VERSION ""

NS_ :

BS_:

BU_: Receiver ChassisBus VehicleBus PartyBus

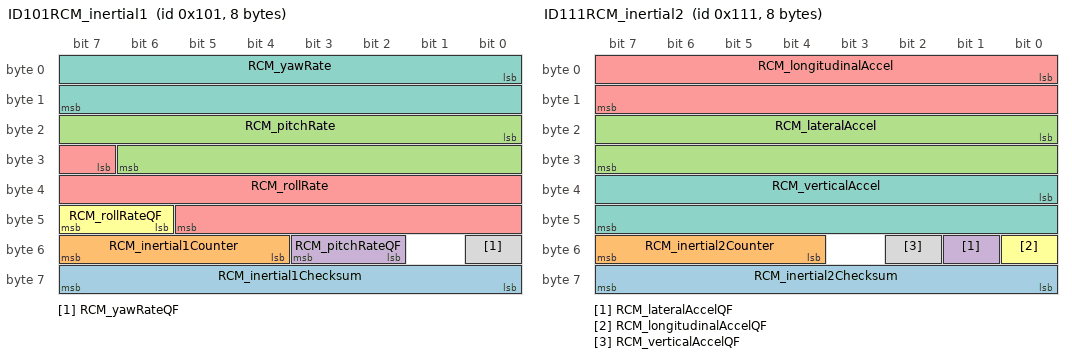
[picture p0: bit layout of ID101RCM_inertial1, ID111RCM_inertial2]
BO_ 257 ID101RCM_inertial1: 8 ChassisBus
 SG_ RCM_inertial1Checksum : 56|8@1+ (1,0) [0|255] ""  Receiver
 SG_ RCM_inertial1Counter : 52|4@1+ (1,0) [0|15] ""  Receiver
 SG_ RCM_pitchRate : 16|15@1- (0.00025,0) [-4.096|4.09575] "rad/s"  Receiver
 SG_ RCM_pitchRateQF : 50|2@1+ (1,0) [0|3] ""  Receiver
 SG_ RCM_rollRate : 31|15@1- (0.00025,0) [-4.096|4.09575] "rad/s"  Receiver
 SG_ RCM_rollRateQF : 46|2@1+ (1,0) [0|3] ""  Receiver
 SG_ RCM_yawRate : 0|16@1- (0.0001,0) [-3.2766|3.2766] "rad/s"  Receiver
 SG_ RCM_yawRateQF : 48|1@1+ (1,0) [0|1] ""  Receiver

BO_ 273 ID111RCM_inertial2: 8 ChassisBus
 SG_ RCM_inertial2Checksum : 56|8@1+ (1,0) [0|255] ""  Receiver
 SG_ RCM_inertial2Counter : 52|4@1+ (1,0) [0|15] ""  Receiver
 SG_ RCM_lateralAccel : 16|16@1- (0.00125,0) [-40.9575|40.9575] "m/s^2"  Receiver
 SG_ RCM_lateralAccelQF : 49|1@1+ (1,0) [0|1] ""  Receiver
 SG_ RCM_longitudinalAccel : 0|16@1- (0.00125,0) [-40.9575|40.9575] "m/s^2"  Receiver
 SG_ RCM_longitudinalAccelQF : 48|1@1+ (1,0) [0|1] ""  Receiver
 SG_ RCM_verticalAccel : 32|16@1- (0.00125,0) [-40.9575|40.9575] "m/s^2"  Receiver
 SG_ RCM_verticalAccelQF : 50|1@1+ (1,0) [0|1] ""  Receiver

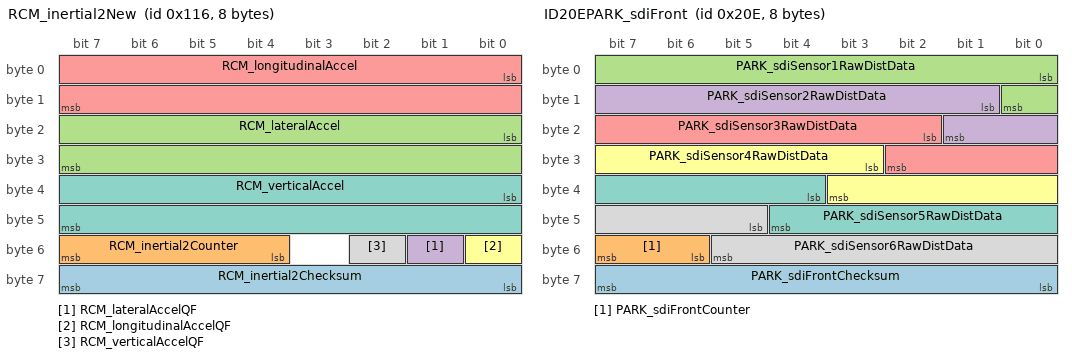
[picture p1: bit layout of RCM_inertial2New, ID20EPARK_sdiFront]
BO_ 278 RCM_inertial2New: 8 ChassisBus
 SG_ RCM_inertial2Checksum : 56|8@1+ (1,0) [0|255] ""  Receiver
 SG_ RCM_inertial2Counter : 52|4@1+ (1,0) [0|15] ""  Receiver
 SG_ RCM_lateralAccel : 16|16@1- (0.00125,0) [-40.9575|40.9575] "m/s^2"  Receiver
 SG_ RCM_lateralAccelQF : 49|1@1+ (1,0) [0|1] ""  Receiver
 SG_ RCM_longitudinalAccel : 0|16@1- (0.00125,0) [-40.9575|40.9575] "m/s^2"  Receiver
 SG_ RCM_longitudinalAccelQF : 48|1@1+ (1,0) [0|1] ""  Receiver
 SG_ RCM_verticalAccel : 32|16@1- (0.00125,0) [-40.9575|40.9575] "m/s^2"  Receiver
 SG_ RCM_verticalAccelQF : 50|1@1+ (1,0) [0|1] ""  Receiver

BO_ 325 ID145ESP_status: 8 ChassisBus
 SG_ ESP_absBrakeEvent2 : 22|2@1+ (1,0) [0|3] ""  Receiver
 SG_ ESP_absFaultLamp : 17|1@1+ (1,0) [0|1] ""  Receiver
 SG_ ESP_brakeApply : 31|1@1+ (1,0) [0|1] ""  Receiver
 SG_ ESP_brakeDiscWipingActive : 28|1@1+ (1,0) [0|1] ""  Receiver
 SG_ ESP_brakeLamp : 21|1@1+ (1,0) [0|1] ""  Receiver
 SG_ ESP_brakeTorqueTarget : 51|13@1+ (2,0) [0|16382] "Nm"  Receiver
 SG_ ESP_btcTargetState : 38|2@1+ (1,0) [0|3] ""  Receiver
 SG_ ESP_cdpStatus : 34|2@1+ (1,0) [0|3] ""  Receiver
 SG_ ESP_driverBrakeApply : 29|2@1+ (1,0) [0|3] ""  Receiver
 SG_ ESP_ebdFaultLamp : 16|1@1+ (1,0) [0|1] ""  Receiver
 SG_ ESP_ebrStandstillSkid : 48|1@1+ (1,0) [0|1] ""  Receiver
 SG_ ESP_ebrStatus : 49|2@1+ (1,0) [0|3] ""  Receiver
 SG_ ESP_espFaultLamp : 18|1@1+ (1,0) [0|1] ""  Receiver
 SG_ ESP_espLampFlash : 20|1@1+ (1,0) [0|1] ""  Receiver
 SG_ ESP_espModeActive : 12|2@1+ (1,0) [0|3] ""  Receiver
 SG_ ESP_hydraulicBoostEnabled : 19|1@1+ (1,0) [0|1] ""  Receiver
 SG_ ESP_lateralAccelQF : 25|1@1+ (1,0) [0|1] ""  Receiver
 SG_ ESP_longitudinalAccelQF : 24|1@1+ (1,0) [0|1] ""  Receiver
 SG_ ESP_ptcTargetState : 36|2@1+ (1,0) [0|3] ""  Receiver
 SG_ ESP_stabilityControlSts2 : 14|2@1+ (1,0) [0|3] ""  Receiver
 SG_ ESP_statusChecksum : 0|8@1+ (1,0) [0|255] ""  Receiver
 SG_ ESP_statusCounter : 8|4@1+ (1,0) [0|15] ""  Receiver
 SG_ ESP_steeringAngleQF : 27|1@1+ (1,0) [0|1] ""  Receiver
 SG_ ESP_yawRateQF : 26|1@1+ (1,0) [0|1] ""  Receiver

BO_ 526 ID20EPARK_sdiFront: 8 ChassisBus
 SG_ PARK_sdiFrontChecksum : 56|8@1+ (1,0) [0|255] ""  Receiver
 SG_ PARK_sdiFrontCounter : 54|2@1+ (1,0) [0|3] ""  Receiver
 SG_ PARK_sdiSensor1RawDistData : 0|9@1+ (1,0) [0|511] "cm"  Receiver
 SG_ PARK_sdiSensor2RawDistData : 9|9@1+ (1,0) [0|511] "cm"  Receiver
 SG_ PARK_sdiSensor3RawDistData : 18|9@1+ (1,0) [0|511] "cm"  Receiver
 SG_ PARK_sdiSensor4RawDistData : 27|9@1+ (1,0) [0|511] "cm"  Receiver
 SG_ PARK_sdiSensor5RawDistData : 36|9@1+ (1,0) [0|511] "cm"  Receiver
 SG_ PARK_sdiSensor6RawDistData : 45|9@1+ (1,0) [0|511] "cm"  Receiver

BO_ 537 ID219VCSEC_TPMSData: 5 ChassisBus
 SG_ VCSEC_TPMSDataIndex M : 0|2@1+ (1,0) [0|3] ""  Receiver
 SG_ VCSEC_TPMSBatVoltage0 m0 : 24|8@1+ (0.01,1.5) [1.5|4.04] "V"  Receiver
 SG_ VCSEC_TPMSBatVoltage1 m1 : 24|8@1+ (0.01,1.5) [1.5|4.04] "V"  Receiver
 SG_ VCSEC_TPMSBatVoltage2 m2 : 24|8@1+ (0.01,1.5) [1.5|4.04] "V"  Receiver
 SG_ VCSEC_TPMSBatVoltage3 m3 : 24|8@1+ (0.01,1.5) [1.5|4.04] "V"  Receiver
 SG_ VCSEC_TPMSLocation0 m0 : 32|3@1+ (1,0) [0|4] ""  Receiver
 SG_ VCSEC_TPMSLocation1 m1 : 32|3@1+ (1,0) [0|4] ""  Receiver
 SG_ VCSEC_TPMSLocation2 m2 : 32|3@1+ (1,0) [0|4] ""  Receiver
 SG_ VCSEC_TPMSLocation3 m3 : 32|3@1+ (1,0) [0|4] ""  Receiver
 SG_ VCSEC_TPMSPressure0 m0 : 8|8@1+ (0.025,0) [0|6.35] "bar"  Receiver
 SG_ VCSEC_TPMSPressure1 m1 : 8|8@1+ (0.025,0) [0|6.35] "bar"  Receiver
 SG_ VCSEC_TPMSPressure2 m2 : 8|8@1+ (0.025,0) [0|6.35] "bar"  Receiver
 SG_ VCSEC_TPMSPressure3 m3 : 8|8@1+ (0.025,0) [0|6.35] "bar"  Receiver
 SG_ VCSEC_TPMSTemperature0 m0 : 16|8@1+ (1,-40) [-40|214] "C"  Receiver
 SG_ VCSEC_TPMSTemperature1 m1 : 16|8@1+ (1,-40) [-40|214] "C"  Receiver
 SG_ VCSEC_TPMSTemperature2 m2 : 16|8@1+ (1,-40) [-40|214] "C"  Receiver
 SG_ VCSEC_TPMSTemperature3 m3 : 16|8@1+ (1,-40) [-40|214] "C"  Receiver

BO_ 568 ID238UI_driverAssistMapData: 8 ChassisBus
 SG_ UI_acceptBottsDots : 48|1@1+ (1,0) [0|1] ""  Receiver
 SG_ UI_autosteerRestricted : 49|1@1+ (1,0) [0|1] ""  Receiver
 SG_ UI_controlledAccess : 37|1@1+ (1,0) [0|1] ""  Receiver
 SG_ UI_countryCode : 16|10@1+ (1,0) [0|1023] ""  Receiver
 SG_ UI_gpsRoadMatch : 28|1@1+ (1,0) [0|1] ""  Receiver
 SG_ UI_inSuperchargerGeofence : 6|1@1+ (1,0) [0|1] ""  Receiver
 SG_ UI_mapDataChecksum : 56|8@1+ (1,0) [0|255] ""  Receiver
 SG_ UI_mapDataCounter : 52|4@1+ (1,0) [0|15] ""  Receiver
 SG_ UI_mapSpeedLimit : 8|5@1+ (1,0) [0|31] ""  Receiver
 SG_ UI_mapSpeedLimitDependency : 0|3@1+ (1,0) [0|7] ""  Receiver
 SG_ UI_mapSpeedLimitType : 13|3@1+ (1,0) [0|7] ""  Receiver
 SG_ UI_mapSpeedUnits : 7|1@1+ (1,0) [0|1] ""  Receiver
 SG_ UI_navRouteActive : 29|1@1+ (1,0) [0|1] ""  Receiver
 SG_ UI_nextBranchDist : 32|5@1+ (10,0) [0|300] "m"  Receiver
 SG_ UI_nextBranchLeftOffRamp : 38|1@1+ (1,0) [0|1] ""  Receiver
 SG_ UI_nextBranchRightOffRamp : 39|1@1+ (1,0) [0|1] ""  Receiver
 SG_ UI_parallelAutoparkEnabled : 30|1@1+ (1,0) [0|1] ""  Receiver
 SG_ UI_perpendicularAutoparkEnabled : 31|1@1+ (1,0) [0|1] ""  Receiver
 SG_ UI_pmmEnabled : 50|1@1+ (1,0) [0|1] ""  Receiver
 SG_ UI_rejectAutosteer : 46|1@1+ (1,0) [0|1] ""  Receiver
 SG_ UI_rejectHPP : 42|1@1+ (1,0) [0|1] ""  Receiver
 SG_ UI_rejectHandsOn : 47|1@1+ (1,0) [0|1] ""  Receiver
 SG_ UI_rejectLeftFreeSpace : 44|1@1+ (1,0) [0|1] ""  Receiver
 SG_ UI_rejectLeftLane : 40|1@1+ (1,0) [0|1] ""  Receiver
 SG_ UI_rejectNav : 43|1@1+ (1,0) [0|1] ""  Receiver
 SG_ UI_rejectRightFreeSpace : 45|1@1+ (1,0) [0|1] ""  Receiver
 SG_ UI_rejectRightLane : 41|1@1+ (1,0) [0|1] ""  Receiver
 SG_ UI_roadClass : 3|3@1+ (1,0) [0|6] ""  Receiver
 SG_ UI_scaEnabled : 51|1@1+ (1,0) [0|1] ""  Receiver
 SG_ UI_streetCount : 26|2@1+ (1,0) [0|3] ""  Receiver

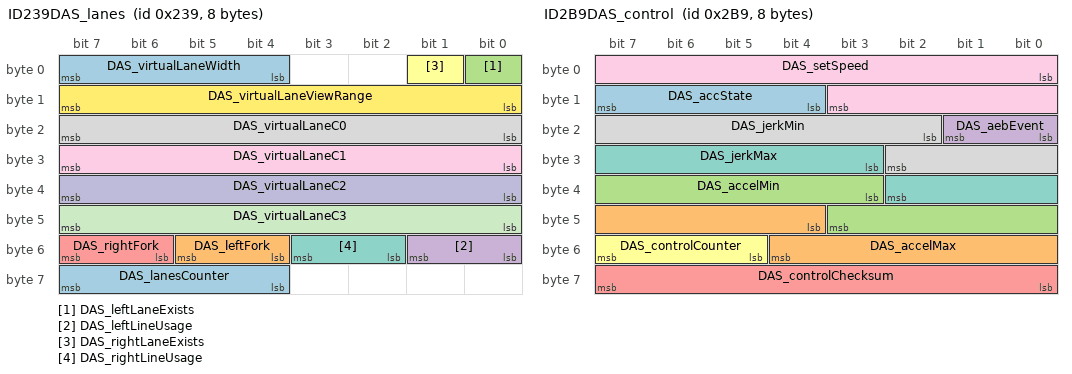
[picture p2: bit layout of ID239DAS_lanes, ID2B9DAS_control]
BO_ 569 ID239DAS_lanes: 8 ChassisBus
 SG_ DAS_lanesCounter : 60|4@1+ (1,0) [0|15] ""  Receiver
 SG_ DAS_leftFork : 52|2@1+ (1,0) [0|3] ""  Receiver
 SG_ DAS_leftLaneExists : 0|1@1+ (1,0) [0|1] ""  Receiver
 SG_ DAS_leftLineUsage : 48|2@1+ (1,0) [0|3] ""  Receiver
 SG_ DAS_rightFork : 54|2@1+ (1,0) [0|3] ""  Receiver
 SG_ DAS_rightLaneExists : 1|1@1+ (1,0) [0|1] ""  Receiver
 SG_ DAS_rightLineUsage : 50|2@1+ (1,0) [0|3] ""  Receiver
 SG_ DAS_virtualLaneC0 : 16|8@1+ (0.035,-3.5) [-3.5|3.5] "m"  Receiver
 SG_ DAS_virtualLaneC1 : 24|8@1+ (0.0016,-0.2) [-0.2|0.2] "rad"  Receiver
 SG_ DAS_virtualLaneC2 : 32|8@1+ (2E-005,-0.0025) [-0.0025|0.0025] "m-1"  Receiver
 SG_ DAS_virtualLaneC3 : 40|8@1+ (2.4E-007,-3E-005) [-3E-005|3E-005] "m-2"  Receiver
 SG_ DAS_virtualLaneViewRange : 8|8@1+ (1,0) [0|160] "m"  Receiver
 SG_ DAS_virtualLaneWidth : 4|4@1+ (0.3125,2) [2|6.6875] "m"  Receiver

BO_ 586 ID24ADAS_visualDebug: 8 ChassisBus
 SG_ DAS_accSmartSpeedActive : 48|1@1+ (1,0) [0|1] ""  Receiver
 SG_ DAS_accSmartSpeedState : 49|3@1+ (1,0) [0|7] ""  Receiver
 SG_ DAS_autosteerBottsDotsUsage : 12|2@1+ (1,0) [0|3] ""  Receiver
 SG_ DAS_autosteerHPPUsage : 6|2@1+ (1,0) [0|3] ""  Receiver
 SG_ DAS_autosteerHealthAnomalyLevel : 18|3@1+ (1,0) [0|7] ""  Receiver
 SG_ DAS_autosteerHealthState : 21|3@1+ (1,0) [0|5] ""  Receiver
 SG_ DAS_autosteerModelUsage : 10|2@1+ (1,0) [0|3] ""  Receiver
 SG_ DAS_autosteerNavigationUsage : 8|2@1+ (1,0) [0|3] ""  Receiver
 SG_ DAS_autosteerVehiclesUsage : 4|2@1+ (1,0) [0|3] ""  Receiver
 SG_ DAS_behaviorType : 56|2@1+ (1,0) [0|3] ""  Receiver
 SG_ DAS_devAppInterfaceEnabled : 38|1@1+ (1,0) [0|1] ""  Receiver
 SG_ DAS_lastAutosteerAbortReason : 32|6@1+ (1,0) [0|34] ""  Receiver
 SG_ DAS_lastLinePreferenceReason : 24|4@1+ (1,0) [0|15] ""  Receiver
 SG_ DAS_navAvailable : 39|1@1+ (1,0) [0|1] ""  Receiver
 SG_ DAS_navDistance : 40|8@1+ (100,0) [0|25500] "km"  Receiver
 SG_ DAS_offsetSide : 14|2@1+ (1,0) [0|3] ""  Receiver
 SG_ DAS_plannerState : 28|4@1+ (1,0) [0|7] ""  Receiver
 SG_ DAS_rearLeftVehDetectedCurrent : 61|1@1+ (1,0) [0|1] ""  Receiver
 SG_ DAS_rearLeftVehDetectedTrip : 63|1@1+ (1,0) [0|1] ""  Receiver
 SG_ DAS_rearRightVehDetectedTrip : 62|1@1+ (1,0) [0|1] ""  Receiver
 SG_ DAS_rearVehDetectedThisCycle : 60|1@1+ (1,0) [0|1] ""  Receiver
 SG_ DAS_roadSurfaceType : 16|2@1+ (1,0) [0|2] ""  Receiver
 SG_ DAS_ulcInProgress : 52|1@1+ (1,0) [0|1] ""  Receiver
 SG_ DAS_ulcType : 58|2@1+ (1,0) [0|2] ""  Receiver

BO_ 603 ID25BAPP_environment: 1 ChassisBus
 SG_ APP_environmentRainy : 0|1@1+ (1,0) [0|1] ""  Receiver
 SG_ APP_environmentSnowy : 1|1@1+ (1,0) [0|1] ""  Receiver

BO_ 697 ID2B9DAS_control: 8 ChassisBus
 SG_ DAS_accState : 12|4@1+ (1,0) [0|15] ""  Receiver
 SG_ DAS_accelMax : 44|9@1+ (0.04,-15) [-15|5.44] "m/s^2"  Receiver
 SG_ DAS_accelMin : 35|9@1+ (0.04,-15) [-15|5.44] "m/s^2"  Receiver
 SG_ DAS_aebEvent : 16|2@1+ (1,0) [0|3] ""  Receiver
 SG_ DAS_controlChecksum : 56|8@1+ (1,0) [0|255] ""  Receiver
 SG_ DAS_controlCounter : 53|3@1+ (1,0) [0|7] ""  Receiver
 SG_ DAS_jerkMax : 27|8@1+ (0.059,0) [0|15.045] "m/s^3"  Receiver
 SG_ DAS_jerkMin : 18|9@1+ (0.03,-15.232) [-15.232|0.098] "m/s^3"  Receiver
 SG_ DAS_setSpeed : 0|12@1+ (0.1,0) [0|409.4] "kph"  Receiver

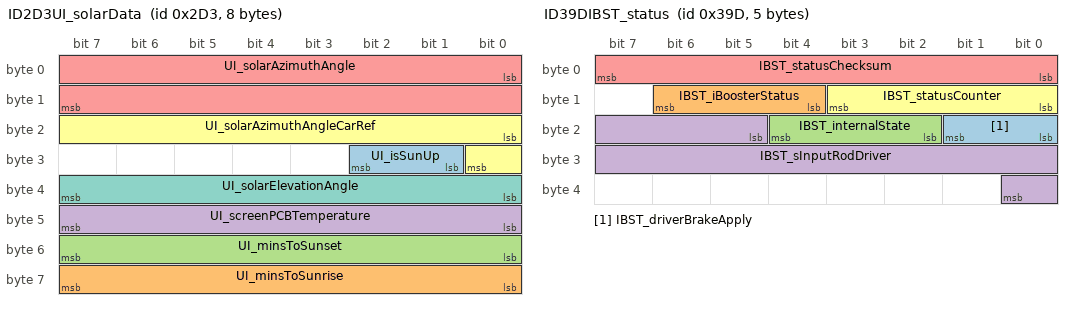
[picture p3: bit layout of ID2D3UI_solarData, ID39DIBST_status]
BO_ 723 ID2D3UI_solarData: 8 ChassisBus
 SG_ UI_isSunUp : 25|2@1+ (1,0) [0|3] ""  Receiver
 SG_ UI_minsToSunrise : 56|8@1+ (10,0) [0|2550] "min"  Receiver
 SG_ UI_minsToSunset : 48|8@1+ (10,0) [0|2550] "min"  Receiver
 SG_ UI_screenPCBTemperature : 40|8@1- (0.5,40) [-20|100] "C"  Receiver
 SG_ UI_solarAzimuthAngle : 0|16@1- (1,0) [-32767|32767] "deg"  Receiver
 SG_ UI_solarAzimuthAngleCarRef : 16|9@1- (1,0) [-256|254] "deg"  Receiver
 SG_ UI_solarElevationAngle : 32|8@1- (1,0) [-128|126] "deg"  Receiver

BO_ 905 ID389DAS_status2: 8 ChassisBus
 SG_ DAS_ACC_report : 26|5@1+ (1,0) [0|24] ""  Receiver
 SG_ DAS_accSpeedLimit : 0|10@1+ (0.2,0) [0|204.6] "mph"  Receiver
 SG_ DAS_activationFailureStatus : 14|2@1+ (1,0) [0|2] ""  Receiver
 SG_ DAS_csaState : 32|2@1+ (1,0) [0|3] ""  Receiver
 SG_ DAS_driverInteractionLevel : 38|2@1+ (1,0) [0|2] ""  Receiver
 SG_ DAS_longCollisionWarning : 48|4@1+ (1,0) [0|15] ""  Receiver
 SG_ DAS_pmmCameraFaultReason : 24|2@1+ (1,0) [0|2] ""  Receiver
 SG_ DAS_pmmLoggingRequest : 13|1@1+ (1,0) [0|1] ""  Receiver
 SG_ DAS_pmmObstacleSeverity : 10|3@1+ (1,0) [0|7] ""  Receiver
 SG_ DAS_pmmRadarFaultReason : 19|2@1+ (1,0) [0|2] ""  Receiver
 SG_ DAS_pmmSysFaultReason : 21|3@1+ (1,0) [0|7] ""  Receiver
 SG_ DAS_pmmUltrasonicsFaultReason : 16|3@1+ (1,0) [0|4] ""  Receiver
 SG_ DAS_ppOffsetDesiredRamp : 40|8@1+ (0.01,-1.28) [-1.28|1.27] "m"  Receiver
 SG_ DAS_radarTelemetry : 34|2@1+ (1,0) [0|2] ""  Receiver
 SG_ DAS_relaxCruiseLimits : 31|1@1+ (1,0) [0|1] ""  Receiver
 SG_ DAS_robState : 36|2@1+ (1,0) [0|3] ""  Receiver
 SG_ DAS_status2Checksum : 56|8@1+ (1,0) [0|255] ""  Receiver
 SG_ DAS_status2Counter : 52|4@1+ (1,0) [0|15] ""  Receiver

BO_ 921 ID399DAS_status: 8 ChassisBus
 SG_ DAS_autoLaneChangeState : 46|5@1+ (1,0) [0|31] ""  Receiver
 SG_ DAS_autoParked : 25|1@1+ (1,0) [0|1] ""  Receiver
 SG_ DAS_autoparkReady : 24|1@1+ (1,0) [0|1] ""  Receiver
 SG_ DAS_autoparkWaitingForBrake : 26|1@1+ (1,0) [0|1] ""  Receiver
 SG_ DAS_autopilotHandsOnState : 42|4@1+ (1,0) [0|15] ""  Receiver
 SG_ DAS_autopilotState : 0|4@1+ (1,0) [0|15] ""  Receiver
 SG_ DAS_blindSpotRearLeft : 4|2@1+ (1,0) [0|3] ""  Receiver
 SG_ DAS_blindSpotRearRight : 6|2@1+ (1,0) [0|3] ""  Receiver
 SG_ DAS_fleetSpeedState : 40|2@1+ (1,0) [0|3] ""  Receiver
 SG_ DAS_forwardCollisionWarning : 22|2@1+ (1,0) [0|3] ""  Receiver
 SG_ DAS_fusedSpeedLimit : 8|5@1+ (5,0) [0|150] "kph/mph"  Receiver
 SG_ DAS_heaterState : 21|1@1+ (1,0) [0|1] ""  Receiver
 SG_ DAS_laneDepartureWarning : 37|3@1+ (1,0) [0|5] ""  Receiver
 SG_ DAS_lssState : 29|3@1+ (1,0) [0|7] ""  Receiver
 SG_ DAS_sideCollisionAvoid : 32|2@1+ (1,0) [0|3] ""  Receiver
 SG_ DAS_sideCollisionInhibit : 36|1@1+ (1,0) [0|1] ""  Receiver
 SG_ DAS_sideCollisionWarning : 34|2@1+ (1,0) [0|3] ""  Receiver
 SG_ DAS_statusChecksum : 56|8@1+ (1,0) [0|255] ""  Receiver
 SG_ DAS_statusCounter : 52|4@1+ (1,0) [0|15] ""  Receiver
 SG_ DAS_summonAvailable : 51|1@1+ (1,0) [0|1] ""  Receiver
 SG_ DAS_summonClearedGate : 15|1@1+ (1,0) [0|1] ""  Receiver
 SG_ DAS_summonFwdLeashReached : 27|1@1+ (1,0) [0|1] ""  Receiver
 SG_ DAS_summonObstacle : 14|1@1+ (1,0) [0|1] ""  Receiver
 SG_ DAS_summonRvsLeashReached : 28|1@1+ (1,0) [0|1] ""  Receiver
 SG_ DAS_suppressSpeedWarning : 13|1@1+ (1,0) [0|1] ""  Receiver
 SG_ DAS_visionOnlySpeedLimit : 16|5@1+ (5,0) [0|150] "kph/mph"  Receiver

BO_ 925 ID39DIBST_status: 5 ChassisBus
 SG_ IBST_driverBrakeApply : 16|2@1+ (1,0) [0|3] ""  Receiver
 SG_ IBST_iBoosterStatus : 12|3@1+ (1,0) [0|6] ""  Receiver
 SG_ IBST_internalState : 18|3@1+ (1,0) [0|6] ""  Receiver
 SG_ IBST_sInputRodDriver : 21|12@1+ (0.015625,-5) [-5|47] "mm"  Receiver
 SG_ IBST_statusChecksum : 0|8@1+ (1,0) [0|255] ""  Receiver
 SG_ IBST_statusCounter : 8|4@1+ (1,0) [0|15] ""  Receiver

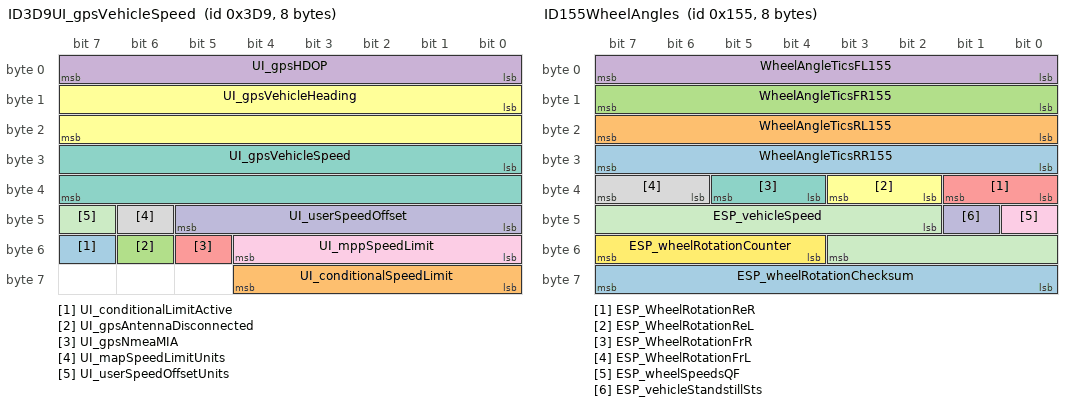
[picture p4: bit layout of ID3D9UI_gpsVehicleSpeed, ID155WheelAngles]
BO_ 985 ID3D9UI_gpsVehicleSpeed: 8 ChassisBus
 SG_ UI_conditionalLimitActive : 55|1@1+ (1,0) [0|1] ""  Receiver
 SG_ UI_conditionalSpeedLimit : 56|5@1+ (5,0) [0|155] "kph/mph"  Receiver
 SG_ UI_gpsAntennaDisconnected : 54|1@1+ (1,0) [0|1] ""  Receiver
 SG_ UI_gpsHDOP : 0|8@1+ (0.1,0) [0|25.5] ""  Receiver
 SG_ UI_gpsNmeaMIA : 53|1@1+ (1,0) [0|1] ""  Receiver
 SG_ UI_gpsVehicleHeading : 8|16@1+ (0.0078125,0) [0|511.992] "deg"  Receiver
 SG_ UI_gpsVehicleSpeed : 24|16@1+ (0.00390625,0) [0|250.996] "kph"  Receiver
 SG_ UI_mapSpeedLimitUnits : 46|1@1+ (1,0) [0|1] ""  Receiver
 SG_ UI_mppSpeedLimit : 48|5@1+ (5,0) [0|155] "kph/mph"  Receiver
 SG_ UI_userSpeedOffset : 40|6@1+ (1,-30) [-30|33] "kph/mph"  Receiver
 SG_ UI_userSpeedOffsetUnits : 47|1@1+ (1,0) [0|1] ""  Receiver

BO_ 1011 ID3F3UI_odo: 3 ChassisBus
 SG_ UI_odometer : 0|24@1+ (0.1,0) [0|1677720] "km"  Receiver

BO_ 1016 ID3F8UI_driverAssistControl: 8 ChassisBus
 SG_ UI_accFollowDistanceSetting : 45|3@1+ (1,0) [0|7] ""  Receiver
 SG_ UI_adaptiveSetSpeedEnable : 39|1@1+ (1,0) [0|1] ""  Receiver
 SG_ UI_alcOffHighwayEnable : 56|1@1+ (1,0) [0|1] ""  Receiver
 SG_ UI_autoSummonEnable : 10|1@1+ (1,0) [0|1] ""  Receiver
 SG_ UI_autopilotControlRequest : 0|1@1+ (1,0) [0|1] ""  Receiver
 SG_ UI_coastToCoast : 9|1@1+ (1,0) [0|1] ""  Receiver
 SG_ UI_curvSpeedAdaptDisable : 4|1@1+ (1,0) [0|1] ""  Receiver
 SG_ UI_curvatureDatabaseOnly : 22|1@1+ (1,0) [0|1] ""  Receiver
 SG_ UI_dasDeveloper : 5|1@1+ (1,0) [0|1] ""  Receiver
 SG_ UI_driveOnMapsEnable : 13|1@1+ (1,0) [0|1] ""  Receiver
 SG_ UI_drivingSide : 40|2@1+ (1,0) [0|2] ""  Receiver
 SG_ UI_enableBrakeLightPulse : 63|1@1+ (1,0) [0|1] ""  Receiver
 SG_ UI_enableClipTelemetry : 42|1@1+ (1,0) [0|1] ""  Receiver
 SG_ UI_enableRoadSegmentTelemetry : 44|1@1+ (1,0) [0|1] ""  Receiver
 SG_ UI_enableTripTelemetry : 43|1@1+ (1,0) [0|1] ""  Receiver
 SG_ UI_enableVinAssociation : 6|1@1+ (1,0) [0|1] ""  Receiver
 SG_ UI_enableVisionOnlyStops : 60|1@1+ (1,0) [0|1] ""  Receiver
 SG_ UI_exceptionListEnable : 11|1@1+ (1,0) [0|1] ""  Receiver
 SG_ UI_followNavRouteEnable : 49|1@1+ (1,0) [0|1] ""  Receiver
 SG_ UI_fuseHPPDisable : 17|1@1+ (1,0) [0|1] ""  Receiver
 SG_ UI_fuseLanesDisable : 16|1@1+ (1,0) [0|1] ""  Receiver
 SG_ UI_fuseVehiclesDisable : 18|1@1+ (1,0) [0|1] ""  Receiver
 SG_ UI_handsOnRequirementDisable : 14|1@1+ (1,0) [0|1] ""  Receiver
 SG_ UI_hasDriveOnNav : 48|1@1+ (1,0) [0|1] ""  Receiver
 SG_ UI_lssElkEnabled : 23|1@1+ (1,0) [0|1] ""  Receiver
 SG_ UI_lssLdwEnabled : 8|1@1+ (1,0) [0|1] ""  Receiver
 SG_ UI_lssLkaEnabled : 7|1@1+ (1,0) [0|1] ""  Receiver
 SG_ UI_roadCheckDisable : 12|1@1+ (1,0) [0|1] ""  Receiver
 SG_ UI_selfParkRequest : 28|4@1+ (1,0) [0|15] ""  Receiver
 SG_ UI_smartSummonType : 58|2@1+ (1,0) [0|2] ""  Receiver
 SG_ UI_source3D : 61|2@1+ (1,0) [0|2] ""  Receiver
 SG_ UI_summonEntryType : 26|2@1+ (1,0) [0|3] ""  Receiver
 SG_ UI_summonExitType : 24|2@1+ (1,0) [0|3] ""  Receiver
 SG_ UI_summonHeartbeat : 2|2@1+ (1,0) [0|3] ""  Receiver
 SG_ UI_summonReverseDist : 32|6@1+ (1,0) [0|63] ""  Receiver
 SG_ UI_ulcBlindSpotConfig : 52|2@1+ (1,0) [0|2] ""  Receiver
 SG_ UI_ulcOffHighway : 15|1@1+ (1,0) [0|1] ""  Receiver
 SG_ UI_ulcSpeedConfig : 50|2@1+ (1,0) [0|3] ""  Receiver
 SG_ UI_ulcStalkConfirm : 1|1@1+ (1,0) [0|1] ""  Receiver
 SG_ UI_undertakeAssistEnable : 38|1@1+ (1,0) [0|1] ""  Receiver
 SG_ UI_validationLoop : 57|1@1+ (1,0) [0|1] ""  Receiver
 SG_ UI_visionSpeedType : 20|2@1+ (1,0) [0|3] ""  Receiver

BO_ 1021 ID3FDUI_autopilotControl: 8 ChassisBus
 SG_ UI_autopilotControlIndex M : 0|3@1+ (1,0) [0|7] ""  Receiver
 SG_ UI_apmv3Branch m1 : 40|3@1+ (1,0) [0|5] ""  Receiver
 SG_ UI_applyEceR79 m1 : 19|1@1+ (1,0) [0|1] ""  Receiver
 SG_ UI_blindspotDistance m0 : 15|3@1+ (1,0) [0|5] ""  Receiver
 SG_ UI_blindspotMinSpeed m0 : 11|4@1+ (1,0) [0|10] ""  Receiver
 SG_ UI_blindspotTTC m0 : 18|3@1+ (1,0) [0|7] ""  Receiver
 SG_ UI_disableBackup m1 : 30|1@1+ (1,0) [0|1] ""  Receiver
 SG_ UI_disableFisheye m1 : 25|1@1+ (1,0) [0|1] ""  Receiver
 SG_ UI_disableLeftPillar m1 : 26|1@1+ (1,0) [0|1] ""  Receiver
 SG_ UI_disableLeftRepeater m1 : 28|1@1+ (1,0) [0|1] ""  Receiver
 SG_ UI_disableMain m1 : 23|1@1+ (1,0) [0|1] ""  Receiver
 SG_ UI_disableNarrow m1 : 24|1@1+ (1,0) [0|1] ""  Receiver
 SG_ UI_disableRadar m1 : 31|1@1+ (1,0) [0|1] ""  Receiver
 SG_ UI_disableRightPillar m1 : 27|1@1+ (1,0) [0|1] ""  Receiver
 SG_ UI_disableRightRepeater m1 : 29|1@1+ (1,0) [0|1] ""  Receiver
 SG_ UI_donAlcProgGoreAbortThres m0 : 29|4@1+ (1,0) [0|9] ""  Receiver
 SG_ UI_donDisableAutoWiperDuration m0 : 4|3@1+ (1,0) [0|6] ""  Receiver
 SG_ UI_donDisableCutin m0 : 24|1@1+ (1,0) [0|1] ""  Receiver
 SG_ UI_donDisableOnAutoWiperSpeed m0 : 7|4@1+ (1,0) [0|15] ""  Receiver
 SG_ UI_donMinGoreWidthForAbortMap m0 : 25|4@1+ (1,0) [0|11] ""  Receiver
 SG_ UI_donMinGoreWidthForAbortNotMap m0 : 33|4@1+ (1,0) [0|11] ""  Receiver
 SG_ UI_donStopEndOfRampBuffer m0 : 21|3@1+ (1,0) [0|4] ""  Receiver
 SG_ UI_driverMonitorConfirmation m1 : 17|1@1+ (1,0) [0|1] ""  Receiver
 SG_ UI_enableAutopilotStopWarning m1 : 44|1@1+ (1,0) [0|1] ""  Receiver
 SG_ UI_enableCabinCamera m1 : 43|1@1+ (1,0) [0|1] ""  Receiver
 SG_ UI_enableCabinCameraTelemetry m1 : 48|1@1+ (1,0) [0|1] ""  Receiver
 SG_ UI_enableMapStops m1 : 20|1@1+ (1,0) [0|1] ""  Receiver
 SG_ UI_factorySummonEnable m1 : 39|1@1+ (1,0) [0|1] ""  Receiver
 SG_ UI_fsdStopsControlEnabled m0 : 38|1@1+ (1,0) [0|1] ""  Receiver
 SG_ UI_fsdVisualizationEnabled m0 : 37|1@1+ (1,0) [0|1] ""  Receiver
 SG_ UI_hardCoreSummon m1 : 47|1@1+ (1,0) [0|1] ""  Receiver
 SG_ UI_homelinkNearby m0 : 45|1@1+ (1,0) [0|1] ""  Receiver
 SG_ UI_hovEnabled m0 : 3|1@1+ (1,0) [0|1] ""  Receiver
 SG_ UI_noStalkConfirmAlertChime m1 : 37|1@1+ (1,0) [0|1] ""  Receiver
 SG_ UI_noStalkConfirmAlertHaptic m1 : 32|1@1+ (1,0) [0|1] ""  Receiver
 SG_ UI_showLaneGraph m1 : 45|1@1+ (1,0) [0|1] ""  Receiver
 SG_ UI_showTrackLabels m1 : 46|1@1+ (1,0) [0|1] ""  Receiver
 SG_ UI_ulcSnooze m1 : 36|1@1+ (1,0) [0|1] ""  Receiver

BO_ 341 ID155WheelAngles: 8 ChassisBus
 SG_ WheelAngleTicsRR155 : 24|8@1+ (1.40625,0) [0|358.594] "deg"  Receiver
 SG_ WheelAngleTicsRL155 : 16|8@1+ (1.40625,0) [0|358.594] "deg"  Receiver
 SG_ WheelAngleTicsFR155 : 8|8@1+ (1.40625,0) [0|358.594] "deg"  Receiver
 SG_ WheelAngleTicsFL155 : 0|8@1+ (1.40625,0) [0|358.594] "deg"  Receiver
 SG_ ESP_WheelRotationReR : 32|2@1+ (1,0) [0|3] ""  Receiver
 SG_ ESP_WheelRotationReL : 34|2@1+ (1,0) [0|3] ""  Receiver
 SG_ ESP_WheelRotationFrR : 36|2@1+ (1,0) [0|3] ""  Receiver
 SG_ ESP_WheelRotationFrL : 38|2@1+ (1,0) [0|3] ""  Receiver
 SG_ ESP_wheelSpeedsQF : 40|1@1+ (1,0) [0|1] ""  Receiver
 SG_ ESP_vehicleStandstillSts : 41|1@1+ (1,0) [0|1] ""  Receiver
 SG_ ESP_vehicleSpeed : 42|10@1+ (0.5,0) [0|511] "kph"  Receiver
 SG_ ESP_wheelRotationCounter : 52|4@1+ (1,0) [0|15] ""  Receiver
 SG_ ESP_wheelRotationChecksum : 56|8@1+ (1,0) [0|255] ""  Receiver

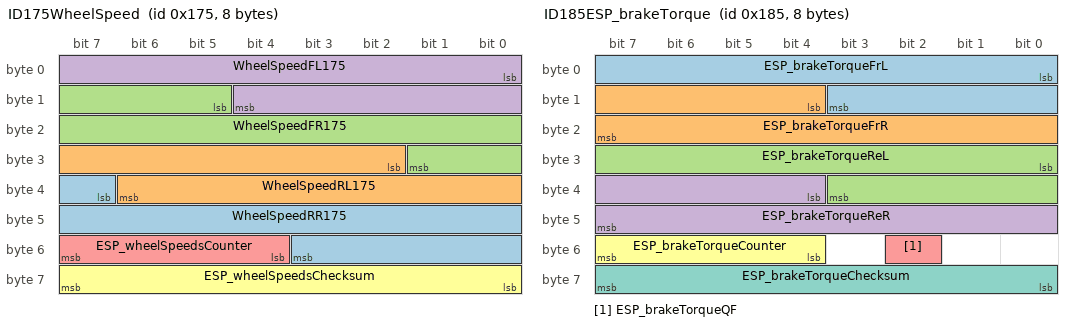
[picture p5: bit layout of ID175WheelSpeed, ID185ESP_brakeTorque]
BO_ 373 ID175WheelSpeed: 8 ChassisBus
 SG_ WheelSpeedRR175 : 39|13@1+ (0.04,0) [0|327.64] "KPH"  Receiver
 SG_ WheelSpeedRL175 : 26|13@1+ (0.04,0) [0|327.64] "KPH"  Receiver
 SG_ WheelSpeedFR175 : 13|13@1+ (0.04,0) [0|327.64] "KPH"  Receiver
 SG_ WheelSpeedFL175 : 0|13@1+ (0.04,0) [0|327.64] "KPH"  Receiver
 SG_ ESP_wheelSpeedsCounter : 52|4@1+ (1,0) [0|15] ""  Receiver
 SG_ ESP_wheelSpeedsChecksum : 56|8@1+ (1,0) [0|255] ""  Receiver

BO_ 389 ID185ESP_brakeTorque: 8 ChassisBus
 SG_ ESP_brakeTorqueFrL : 0|12@1+ (2,0) [0|8190] "Nm"  Receiver
 SG_ ESP_brakeTorqueFrR : 12|12@1+ (2,0) [0|8190] "Nm"  Receiver
 SG_ ESP_brakeTorqueReL : 24|12@1+ (2,0) [0|8190] "Nm"  Receiver
 SG_ ESP_brakeTorqueReR : 36|12@1+ (2,0) [0|8190] "Nm"  Receiver
 SG_ ESP_brakeTorqueQF : 50|1@1+ (1,0) [0|1] ""  Receiver
 SG_ ESP_brakeTorqueCounter : 52|4@1+ (1,0) [0|15] ""  Receiver
 SG_ ESP_brakeTorqueChecksum : 56|8@1+ (1,0) [0|255] ""  Receiver

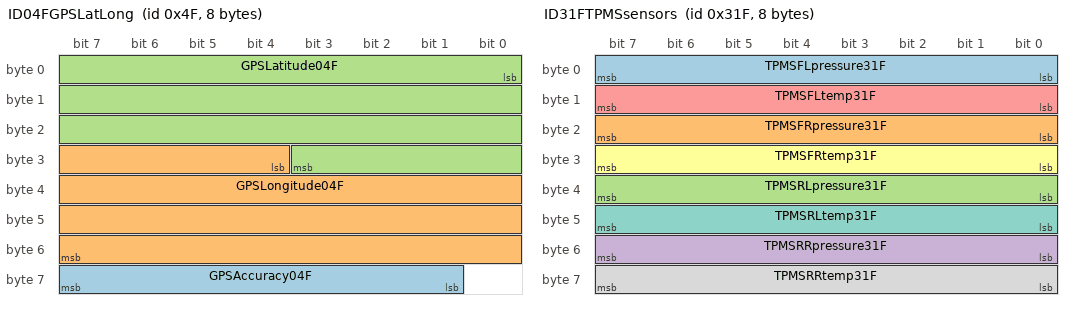
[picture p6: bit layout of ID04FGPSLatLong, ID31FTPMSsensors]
BO_ 79 ID04FGPSLatLong: 8 ChassisBus
 SG_ GPSAccuracy04F : 57|7@1+ (0.2,0) [0|25.2] "m"  Receiver
 SG_ GPSLongitude04F : 28|28@1- (1E-006,0) [-134.218|134.218] "Deg"  Receiver
 SG_ GPSLatitude04F : 0|28@1- (1E-006,0) [-134.218|134.218] "Deg"  Receiver

BO_ 799 ID31FTPMSsensors: 8 ChassisBus
 SG_ TPMSFLpressure31F : 0|8@1+ (0.025,0) [0|6.375] "bar"  Receiver
 SG_ TPMSFRpressure31F : 16|8@1+ (0.025,0) [0|6.375] "bar"  Receiver
 SG_ TPMSRLpressure31F : 32|8@1+ (0.025,0) [0|6.375] "bar"  Receiver
 SG_ TPMSRRpressure31F : 48|8@1+ (0.025,0) [0|6.375] "bar"  Receiver
 SG_ TPMSFLtemp31F : 8|8@1+ (1,-40) [-40|215] "C"  Receiver
 SG_ TPMSFRtemp31F : 24|8@1+ (1,-40) [-40|215] "C"  Receiver
 SG_ TPMSRLtemp31F : 40|8@1+ (1,-40) [-40|215] "C"  Receiver
 SG_ TPMSRRtemp31F : 56|8@1+ (1,-40) [-40|215] "C"  Receiver

CM_ SG_ 130 UI_tripPlanningActive "Navigation Active";
CM_ SG_ 257 RCM_pitchRate "Pitch";
CM_ SG_ 257 RCM_rollRate "Roll";
CM_ SG_ 257 RCM_yawRate "Yaw";
CM_ SG_ 273 RCM_lateralAccel "L/R Acceleration";
CM_ SG_ 273 RCM_longitudinalAccel "F/B Acceleration";
CM_ SG_ 273 RCM_verticalAccel "Vertical Acceleration";
CM_ SG_ 692 PCS_dcdcHvBusVolt "DCDC HV Voltage";
CM_ SG_ 692 PCS_dcdcLvBusVolt "DCDC 12v Voltage";
CM_ SG_ 692 PCS_dcdcLvOutputCurrent "DCDC 12v Output Current";
CM_ SG_ 985 UI_gpsVehicleHeading "GPS Heading";
CM_ SG_ 985 UI_gpsVehicleSpeed "GPS Speed";
CM_ SG_ 1011 UI_odometer "UI Odometer";
CM_ SG_ 615 DI_gradeEst "Estimated Grade";
CM_ SG_ 615 DI_mass "Estimated Mass";
CM_ SG_ 642 VCLEFT_hvacBlowerRPMActual "HVAC Blower Speed";
CM_ SG_ 647 PTC_leftCurrentHV "Heater Left Current";
CM_ SG_ 647 PTC_rightCurrentHV "Heater Right Current";
CM_ SG_ 647 PTC_voltageHV "Heater Voltage";
CM_ SG_ 819 UI_acChargeCurrentLimit "UI Charge Current Limit";
CM_ SG_ 826 UI_Range "Range";
CM_ SG_ 826 UI_SOC "State of Charge UI";
CM_ SG_ 826 UI_uSOE "UI fine SOC";
CM_ SG_ 826 UI_ratedWHpM "WHM Rating";
CM_ SG_ 577 VCFRONT_coolantFlowBatActual "Battery Coolant Flow";
CM_ SG_ 577 VCFRONT_coolantFlowPTActual "Powertrain Coolant Flow";
CM_ BO_ 1367 "swapped with 5D7 in old firmware";
CM_ BO_ 1495 "swapped with 557 in old firmware";
CM_ BO_ 2005 "swapped with 757 in old firmware";
CM_ BO_ 1879 "swapped with 7D5 in old firmware";
CM_ SG_ 579 VCRIGHT_hvacCabinTempEst "Cabin Temperature";
CM_ SG_ 524 VCRIGHT_wattsDemandEvap "Evaporator Power";
CM_ SG_ 792 UTCyear318 "Year";
CM_ SG_ 792 UTCmonth318 "Month";
CM_ SG_ 792 UTCseconds318 "Seconds";
CM_ SG_ 792 UTChour318 "Hour";
CM_ SG_ 792 UTCday318 "Day";
CM_ SG_ 792 UTCminutes318 "Minute";
CM_ SG_ 1320 UnixTimeSeconds528 "Unix Time";
CM_ SG_ 390 DIF_axleSpeed "Front Axle Speed";
CM_ SG_ 390 DIF_torqueActual "Front Axle Torque";
CM_ SG_ 390 DIF_torqueCommand "Front Axle Torque Request";
CM_ BO_ 918 "swapped with 395 in old firmware";
CM_ BO_ 917 "swapped with 396 in old firmware";
CM_ SG_ 472 RearTorqueRequest1D8 "Rear Motor Torque Request";
CM_ SG_ 472 RearTorque1D8 "Rear Motor Torque";
CM_ SG_ 468 RAWTorqueFront1D4 "Front Torque Old, Axle torque 2 with 9/1 gearing";
CM_ SG_ 469 FrontTorqueRequest1D5 "Front Motor Torque Request";
CM_ SG_ 469 FrontTorque1D5 "Front Motor Torque";
CM_ SG_ 741 FrontPower2E5 "Front Motor Power";
CM_ SG_ 741 FrontPowerLimit2E5 "Front Power Limit, approx offset Orig scale 1";
CM_ SG_ 741 FrontHeatPower2E5 "Front Waste Heat Power";
CM_ SG_ 822 DriveRegenRating336 "Regen Rating";
CM_ SG_ 822 DrivePowerRating336 "Power Rating";
CM_ SG_ 616 SystemRegenPowerMax268 "Max Regen Power";
CM_ SG_ 616 SystemHeatPowerMax268 "System Max Waste Heat Power";
CM_ SG_ 616 SystemHeatPower268 "System Waste Heat Power";
CM_ SG_ 616 SystemDrivePowerMax268 "Max Drive Power";
CM_ SG_ 79 GPSLongitude04F "Longitude";
CM_ SG_ 79 GPSLatitude04F "Latitude";
CM_ SG_ 978 TotalDischargeKWh3D2 "Lifetime Discharge";
CM_ SG_ 978 TotalChargeKWh3D2 "Lifetime Charge";
CM_ SG_ 722 MinVoltage2D2 "BMS Min Voltage";
CM_ SG_ 722 MaxDischargeCurrent2D2 "BMS Max Discharge Current";
CM_ SG_ 722 MaxChargeCurrent2D2 "BMS Max Charge Current";
CM_ SG_ 722 MaxVoltage2D2 "BMS Max Voltage";
CM_ SG_ 1345 FCMaxPowerLimit541 "Supercharger Power Limit";
CM_ SG_ 1345 FCMaxCurrentLimit541 "Supercharger Current Limit";
CM_ SG_ 580 FCMinVlimit244 "Supercharger Min Voltage";
CM_ SG_ 580 FCMaxVlimit244 "Supercharger Max Voltage";
CM_ SG_ 580 FCCurrentLimit244 "Supercharger Max Current";
CM_ SG_ 580 FCPowerLimit244 "Supercharger Max Power";
CM_ SG_ 801 VCFRONT_tempAmbientFiltered "Outside Temperature";
CM_ SG_ 801 VCFRONT_tempCoolantBatInlet "Battery Coolant Temp";
CM_ SG_ 801 VCFRONT_tempCoolantPTInlet "Powertrain Coolant Temp";
CM_ SG_ 984 Elevation3D8 "Elevation";
CM_ SG_ 609 v12vBattVoltage261 "12V Battery Voltage";
CM_ SG_ 609 v12vBattCurrent261 "12V Battery Current";
CM_ SG_ 609 v12vBattTemp261 "12V Battery Temp";
CM_ SG_ 609 v12vBattAH261 "12V Battery Capacity";
CM_ SG_ 297 SteeringSpeed129 "Steering Speed";
CM_ SG_ 297 SteeringAngle129 "Steering Angle";
CM_ SG_ 612 ChargeLinePower264 "Charger Line Power";
CM_ SG_ 612 ChargeLineCurrentLimit264 "Charge Connector Current Limit";
CM_ SG_ 612 ChargeLineVoltage264 "Charger Line Voltage";
CM_ SG_ 612 ChargeLineCurrent264 "Charger Line Current";
CM_ SG_ 548 DCDCoutputCurrent224 "DCDC Output Current";
CM_ SG_ 280 DI_accelPedalPos "Pedal Position";
CM_ SG_ 280 DI_brakePedalState "Brake Pedal";
CM_ SG_ 280 DI_gear "Gear";
CM_ SG_ 280 DI_regenLight "Regen Brake";
CM_ SG_ 280 DI_tractionControlMode "Traction Control Mode";
CM_ SG_ 850 BMS_energyBuffer "Battery Buffer kWh";
CM_ SG_ 850 BMS_energyToChargeComplete "Charge Remaining kWh";
CM_ SG_ 850 BMS_fullChargeComplete "Charge Complete";
CM_ SG_ 850 BMS_nominalEnergyRemaining "Batt Remaining kWh";
CM_ SG_ 850 BMS_nominalFullPackEnergy "Batt Full kWh";
CM_ SG_ 594 BMS_hvacPowerBudget "BMS Max HVAC Power";
CM_ SG_ 594 BMS_maxDischargePower "BMS Max Discharge Power";
CM_ SG_ 594 BMS_maxRegenPower "BMS Max Regen Power";
CM_ SG_ 594 BMS_maxStationaryHeatPower "BMS Max Waste Heat Power";
CM_ SG_ 786 BMSdissipation312 "Battery Dissipation";
CM_ SG_ 786 BMSinletActiveCoolTarget312 "Battery Cool Target";
CM_ SG_ 786 BMSinletActiveHeatTarget312 "Battery Heat Target";
CM_ SG_ 786 BMSmaxPackTemperature "Max Battery Temp";
CM_ SG_ 786 BMSminPackTemperature "Min Battery Temp";
CM_ SG_ 658 BattBeginningOfLifeEnergy292 "HV Battery Original Energy";
CM_ SG_ 658 SOCmax292 "BMS Max SOC";
CM_ SG_ 658 SOCave292 "BMS Ave SOC";
CM_ SG_ 658 SOCmin292 "BMS Min SOC";
CM_ SG_ 599 DI_uiSpeed "UI Speed";
CM_ SG_ 599 DI_uiSpeedUnits "Speed Units, 0-mph 1-kph";
CM_ SG_ 599 DI_vehicleSpeed "Vehicle Speed, .05 -25 for mph";
CM_ SG_ 1029 VINB405 "VIN3, last 7 of VIN (ASCII)";
CM_ SG_ 1029 VINC405 "VIN2, part two of VIN (ASCII)";
CM_ SG_ 1029 VINA405 "VIN1, four zeros then first 3 characters of VIN";
CM_ SG_ 886 TempStator376 "Front Stator Temp";
CM_ SG_ 789 RearTempStator315 "Rear Stator Temp";
CM_ SG_ 340 RAWTorqueRear154 "Rear Torque Old, Axle torque 2 with 9/1 gearing";
CM_ SG_ 950 Odometer3B6 "Odometer";
CM_ SG_ 614 RearPowerLimit266 "Rear Power Limit, approx offset Orig scale 1";
CM_ SG_ 614 RearHeatPower266 "Rear Waste Heat Power";
CM_ SG_ 614 RearPower266 "Rear Motor Power";
CM_ SG_ 741 FrontPower2E5 "Front Motor Power";
CM_ SG_ 741 FrontPowerLimit2E5 "Front Power Limit, approx offset Orig scale 1";
CM_ SG_ 741 FrontHeatPower2E5 "Front Waste Heat Power";
CM_ SG_ 264 DIR_axleSpeed "Rear Axle Speed";
CM_ SG_ 264 DIR_torqueActual "Rear Axle Torque";
CM_ SG_ 264 DIR_torqueCommand "Rear Axle Torque Request";
CM_ SG_ 306 ChargeHoursRemaining132 "Charge Time Remaining";
CM_ SG_ 306 BattVoltage132 "HV Battery Voltage";
CM_ SG_ 306 RawBattCurrent132 "HV Raw Current, old offset 1000";
CM_ SG_ 306 SmoothBattCurrent132 "HV Battery Current";
CM_ SG_ 294 RearHighVoltage126 "Rear Motor Voltage";
CM_ SG_ 294 RearMotorCurrent126 "Rear Motor Current";
CM_ SG_ 421 FrontHighVoltage1A5 "Front Motor Voltage";
CM_ SG_ 421 FrontMotorCurrent1A5 "Front Motor Current";
CM_ BO_ 1022 "Brake Temps Estimated";
CM_ SG_ 2047 GTW_chassisType "Model";
CM_ SG_ 2047 GTW_packEnergy "Battery Pack Size";
CM_ SG_ 818 BattBrickTempMax332 "Max Batt Brick Temp";
CM_ SG_ 818 BattBrickTempMin332 "Min Batt Brick Temp";
CM_ SG_ 818 BattBrickVoltageMax332 "Max Batt Brick V";
CM_ SG_ 818 BattBrickVoltageMin332 "Min Batt Brick V";
BA_DEF_ BO_  "GenMsgSendType" ENUM  "Cyclic","SendType1","SendType2","SendType3","SendType4","SendType5","SendType6","SendType7","SendType8","SendType9";
BA_DEF_ BO_  "GenMsgCycleTime" INT 0 0;
BA_DEF_  "BusType" STRING ;
BA_DEF_ SG_  "GenSigEnvVarType" ENUM  "Cyclic","SendType1","SendType2","SendType3","SendType4","SendType5","SendType6","SendType7","SendType8","SendType9","No","Yes","No","Yes","No","Yes","No","Yes","int","float","undef";
BA_DEF_  "Modified" STRING ;
BA_DEF_ BO_  "SystemMessageLongSymbol" STRING ;
BA_DEF_DEF_  "GenMsgSendType" "";
BA_DEF_DEF_  "GenMsgCycleTime" 0;
BA_DEF_DEF_  "BusType" "";
BA_DEF_DEF_  "GenSigEnvVarType" "";
BA_DEF_DEF_  "Modified" "JW2021Aug29";
BA_DEF_DEF_  "SystemMessageLongSymbol" "";
BA_ "BusType" "CAN";
BA_ "GenMsgCycleTime" BO_ 530 100;
BA_ "GenMsgSendType" BO_ 530 0;
BA_ "GenMsgCycleTime" BO_ 819 500;
BA_ "GenMsgCycleTime" BO_ 577 100;
BA_ "GenMsgCycleTime" BO_ 468 10;
BA_ "GenMsgSendType" BO_ 468 0;
BA_ "GenMsgCycleTime" BO_ 962 50;
BA_ "GenMsgCycleTime" BO_ 822 1000;
BA_ "GenMsgCycleTime" BO_ 659 500;
BA_ "GenMsgCycleTime" BO_ 616 100;
BA_ "GenMsgSendType" BO_ 79 0;
BA_ "GenMsgCycleTime" BO_ 79 1000;
BA_ "GenMsgCycleTime" BO_ 978 1000;
BA_ "GenMsgCycleTime" BO_ 722 100;
BA_ "GenMsgCycleTime" BO_ 1345 100;
BA_ "GenMsgCycleTime" BO_ 580 100;
BA_ "GenMsgCycleTime" BO_ 532 100;
BA_ "GenMsgCycleTime" BO_ 533 1000;
BA_ "GenMsgCycleTime" BO_ 535 1000;
BA_ "GenMsgCycleTime" BO_ 801 1000;
BA_ "SystemMessageLongSymbol" BO_ 513 "ID201VCFRONT_loggingAndVitals10Hz";
BA_ "GenMsgCycleTime" BO_ 984 1000;
BA_ "GenMsgCycleTime" BO_ 609 100;
BA_ "GenMsgSendType" BO_ 297 0;
BA_ "GenMsgCycleTime" BO_ 297 10;
BA_ "GenMsgCycleTime" BO_ 612 100;
BA_ "GenMsgCycleTime" BO_ 548 100;
BA_ "GenMsgSendType" BO_ 280 0;
BA_ "GenMsgCycleTime" BO_ 280 10;
BA_ "GenMsgCycleTime" BO_ 850 1000;
BA_ "GenMsgCycleTime" BO_ 594 100;
BA_ "GenMsgCycleTime" BO_ 786 1000;
BA_ "GenMsgCycleTime" BO_ 658 100;
BA_ "GenMsgCycleTime" BO_ 599 20;
BA_ "GenMsgCycleTime" BO_ 1029 205;
BA_ "GenMsgCycleTime" BO_ 886 1000;
BA_ "GenMsgCycleTime" BO_ 340 10;
BA_ "GenMsgSendType" BO_ 340 0;
BA_ "GenMsgCycleTime" BO_ 950 1000;
BA_ "GenMsgCycleTime" BO_ 614 10;
BA_ "GenMsgCycleTime" BO_ 741 1000;
BA_ "GenMsgSendType" BO_ 264 0;
BA_ "GenMsgCycleTime" BO_ 264 10;
BA_ "GenMsgCycleTime" BO_ 306 10;
BA_ "GenMsgSendType" BO_ 306 0;
BA_ "GenMsgSendType" BO_ 294 0;
BA_ "GenMsgCycleTime" BO_ 294 100;
BA_ "GenMsgCycleTime" BO_ 799 1000;
BA_ "GenMsgCycleTime" BO_ 1022 1000;
BA_ "GenMsgCycleTime" BO_ 2047 100;
BA_ "GenSigEnvVarType" SG_ 472 TorqueFlags1D8 0;
VAL_ 12 UI_autopilotTrial 3 "ACTIVE" 0 "NONE" 1 "START" 2 "STOP" ;
VAL_ 12 UI_cellNetworkTechnology 9 "CELL_NETWORK_CDMA" 2 "CELL_NETWORK_EDGE" 1 "CELL_NETWORK_GPRS" 8 "CELL_NETWORK_GSM" 4 "CELL_NETWORK_HSDPA" 6 "CELL_NETWORK_HSPA" 5 "CELL_NETWORK_HSUPA" 7 "CELL_NETWORK_LTE" 0 "CELL_NETWORK_NONE" 15 "CELL_NETWORK_SNA" 3 "CELL_NETWORK_UMTS" 10 "CELL_NETWORK_WCDMA" ;
VAL_ 12 UI_cellSignalBars 5 "FIVE" 4 "FOUR" 1 "ONE" 7 "SNA" 3 "THREE" 2 "TWO" 0 "ZERO" ;
VAL_ 12 UI_factoryReset 3 "CUSTOMER" 1 "DEVELOPER" 2 "DIAGNOSTIC" 0 "NONE_SNA" ;
VAL_ 130 UI_energyAtDestination 32768 "SNA" 32767 "TRIP_TOO_LONG" ;
VAL_ 130 UI_hindsightEnergy 32768 "SNA" 32767 "TRIP_TOO_LONG" ;
VAL_ 130 UI_predictedEnergy 32768 "SNA" 32767 "TRIP_TOO_LONG" ;
VAL_ 257 RCM_pitchRate 16384 "SNA" ;
VAL_ 257 RCM_pitchRateQF 3 "FAULTED" 0 "INIT" 2 "TEMP_INVALID" 1 "VALID" ;
VAL_ 257 RCM_rollRate 16384 "SNA" ;
VAL_ 257 RCM_rollRateQF 3 "FAULTED" 0 "INIT" 2 "TEMP_INVALID" 1 "VALID" ;
VAL_ 257 RCM_yawRate 32768 "SNA" ;
VAL_ 257 RCM_yawRateQF 0 "FAULTED" 1 "NOT_FAULTED" ;
VAL_ 273 RCM_lateralAccel 32768 "SNA" ;
VAL_ 273 RCM_lateralAccelQF 0 "FAULTED" 1 "NOT_FAULTED" ;
VAL_ 273 RCM_longitudinalAccel 32768 "SNA" ;
VAL_ 273 RCM_longitudinalAccelQF 0 "FAULTED" 1 "NOT_FAULTED" ;
VAL_ 273 RCM_verticalAccel 32768 "SNA" ;
VAL_ 273 RCM_verticalAccelQF 0 "FAULTED" 1 "NOT_FAULTED" ;
VAL_ 258 VCLEFT_frontLatchStatus 5 "LATCH_AJAR" 2 "LATCH_CLOSED" 3 "LATCH_CLOSING" 7 "LATCH_DEFAULT" 8 "LATCH_FAULT" 1 "LATCH_OPENED" 4 "LATCH_OPENING" 0 "LATCH_SNA" 6 "LATCH_TIMEOUT" ;
VAL_ 258 VCLEFT_mirrorFoldState 1 "MIRROR_FOLD_STATE_FOLDED" 3 "MIRROR_FOLD_STATE_FOLDING" 2 "MIRROR_FOLD_STATE_UNFOLDED" 4 "MIRROR_FOLD_STATE_UNFOLDING" 0 "MIRROR_FOLD_STATE_UNKNOWN" ;
VAL_ 258 VCLEFT_mirrorHeatState 4 "HEATER_STATE_FAULT" 2 "HEATER_STATE_OFF" 3 "HEATER_STATE_OFF_UNAVAILABLE" 1 "HEATER_STATE_ON" 0 "HEATER_STATE_SNA" ;
VAL_ 258 VCLEFT_mirrorRecallState 0 "MIRROR_RECALL_STATE_INIT" 1 "MIRROR_RECALL_STATE_RECALLING_AXIS_1" 2 "MIRROR_RECALL_STATE_RECALLING_AXIS_2" 3 "MIRROR_RECALL_STATE_RECALLING_COMPLETE" 4 "MIRROR_RECALL_STATE_RECALLING_FAILED" 5 "MIRROR_RECALL_STATE_RECALLING_STOPPED" ;
VAL_ 258 VCLEFT_mirrorState 3 "MIRROR_STATE_FOLD_UNFOLD" 0 "MIRROR_STATE_IDLE" 4 "MIRROR_STATE_RECALL" 1 "MIRROR_STATE_TILT_X" 2 "MIRROR_STATE_TILT_Y" ;
VAL_ 258 VCLEFT_rearLatchStatus 5 "LATCH_AJAR" 2 "LATCH_CLOSED" 3 "LATCH_CLOSING" 7 "LATCH_DEFAULT" 8 "LATCH_FAULT" 1 "LATCH_OPENED" 4 "LATCH_OPENING" 0 "LATCH_SNA" 6 "LATCH_TIMEOUT" ;
VAL_ 259 VCRIGHT_frontLatchStatus 5 "LATCH_AJAR" 2 "LATCH_CLOSED" 3 "LATCH_CLOSING" 7 "LATCH_DEFAULT" 8 "LATCH_FAULT" 1 "LATCH_OPENED" 4 "LATCH_OPENING" 0 "LATCH_SNA" 6 "LATCH_TIMEOUT" ;
VAL_ 259 VCRIGHT_mirrorFoldState 1 "MIRROR_FOLD_STATE_FOLDED" 3 "MIRROR_FOLD_STATE_FOLDING" 2 "MIRROR_FOLD_STATE_UNFOLDED" 4 "MIRROR_FOLD_STATE_UNFOLDING" 0 "MIRROR_FOLD_STATE_UNKNOWN" ;
VAL_ 259 VCRIGHT_mirrorRecallState 0 "MIRROR_RECALL_STATE_INIT" 1 "MIRROR_RECALL_STATE_RECALLING_AXIS_1" 2 "MIRROR_RECALL_STATE_RECALLING_AXIS_2" 3 "MIRROR_RECALL_STATE_RECALLING_COMPLETE" 4 "MIRROR_RECALL_STATE_RECALLING_FAILED" 5 "MIRROR_RECALL_STATE_RECALLING_STOPPED" ;
VAL_ 259 VCRIGHT_mirrorState 3 "MIRROR_STATE_FOLD_UNFOLD" 0 "MIRROR_STATE_IDLE" 4 "MIRROR_STATE_RECALL" 1 "MIRROR_STATE_TILT_X" 2 "MIRROR_STATE_TILT_Y" ;
VAL_ 259 VCRIGHT_rearLatchStatus 5 "LATCH_AJAR" 2 "LATCH_CLOSED" 3 "LATCH_CLOSING" 7 "LATCH_DEFAULT" 8 "LATCH_FAULT" 1 "LATCH_OPENED" 4 "LATCH_OPENING" 0 "LATCH_SNA" 6 "LATCH_TIMEOUT" ;
VAL_ 259 VCRIGHT_trunkLatchStatus 5 "LATCH_AJAR" 2 "LATCH_CLOSED" 3 "LATCH_CLOSING" 7 "LATCH_DEFAULT" 8 "LATCH_FAULT" 1 "LATCH_OPENED" 4 "LATCH_OPENING" 0 "LATCH_SNA" 6 "LATCH_TIMEOUT" ;
VAL_ 275 GTW_bmpState 2 "BMP_STATE_ASLEEP" 3 "BMP_STATE_MIA" 0 "BMP_STATE_OFF" 1 "BMP_STATE_ON" 5 "BMP_STATE_POWER_CYCLE" 4 "BMP_STATE_RESET" 255 "DUMMY" ;
VAL_ 281 VCSEC_windowRequestPercent 127 "SNA" ;
VAL_ 281 VCSEC_windowRequestType 3 "WINDOW_REQUEST_GOTO_CLOSED" 2 "WINDOW_REQUEST_GOTO_CRACKED" 1 "WINDOW_REQUEST_GOTO_PERCENT" 0 "WINDOW_REQUEST_IDLE" ;
VAL_ 290 VCLEFT_frontDoorState 1 "DOOR_STATE_CLOSED" 4 "DOOR_STATE_OPEN_OR_AJAR" 3 "DOOR_STATE_RELEASING_LATCH" 0 "DOOR_STATE_UNKNOWN" 2 "DOOR_STATE_WAIT_FOR_SHORT_DROP" ;
VAL_ 290 VCLEFT_frontHandleDebounceStatus 3 "EXTERIOR_HANDLE_STATUS_ACTIVE" 4 "EXTERIOR_HANDLE_STATUS_DISCONNECTED" 5 "EXTERIOR_HANDLE_STATUS_FAULT" 1 "EXTERIOR_HANDLE_STATUS_INDETERMINATE" 2 "EXTERIOR_HANDLE_STATUS_NOT_ACTIVE" 0 "EXTERIOR_HANDLE_STATUS_SNA" ;
VAL_ 290 VCLEFT_frontHandleRawStatus 3 "EXTERIOR_HANDLE_STATUS_ACTIVE" 4 "EXTERIOR_HANDLE_STATUS_DISCONNECTED" 5 "EXTERIOR_HANDLE_STATUS_FAULT" 1 "EXTERIOR_HANDLE_STATUS_INDETERMINATE" 2 "EXTERIOR_HANDLE_STATUS_NOT_ACTIVE" 0 "EXTERIOR_HANDLE_STATUS_SNA" ;
VAL_ 290 VCLEFT_rearDoorState 1 "DOOR_STATE_CLOSED" 4 "DOOR_STATE_OPEN_OR_AJAR" 3 "DOOR_STATE_RELEASING_LATCH" 0 "DOOR_STATE_UNKNOWN" 2 "DOOR_STATE_WAIT_FOR_SHORT_DROP" ;
VAL_ 290 VCLEFT_rearHandleDebounceStatus 3 "EXTERIOR_HANDLE_STATUS_ACTIVE" 4 "EXTERIOR_HANDLE_STATUS_DISCONNECTED" 5 "EXTERIOR_HANDLE_STATUS_FAULT" 1 "EXTERIOR_HANDLE_STATUS_INDETERMINATE" 2 "EXTERIOR_HANDLE_STATUS_NOT_ACTIVE" 0 "EXTERIOR_HANDLE_STATUS_SNA" ;
VAL_ 290 VCLEFT_rearHandleRawStatus 3 "EXTERIOR_HANDLE_STATUS_ACTIVE" 4 "EXTERIOR_HANDLE_STATUS_DISCONNECTED" 5 "EXTERIOR_HANDLE_STATUS_FAULT" 1 "EXTERIOR_HANDLE_STATUS_INDETERMINATE" 2 "EXTERIOR_HANDLE_STATUS_NOT_ACTIVE" 0 "EXTERIOR_HANDLE_STATUS_SNA" ;
VAL_ 322 VCLEFT_liftgateStatusIndex 0 "LIFTGATE_STATUS_INDEX_0" 1 "LIFTGATE_STATUS_INDEX_1" 2 "LIFTGATE_STATUS_INDEX_INVALID" ;
VAL_ 322 VCLEFT_liftgateLatchRequest 1 "LATCH_REQUEST_CINCH" 3 "LATCH_REQUEST_FORCE_RELEASE" 0 "LATCH_REQUEST_NONE" 2 "LATCH_REQUEST_RELEASE" 4 "LATCH_REQUEST_RESET" ;
VAL_ 322 VCLEFT_liftgateMvmntNotAllowedCo 4 "PLG_MVMT_NOT_ALLOWED_EXTERIOR_PRESS_AT_MAX_OPEN" 5 "PLG_MVMT_NOT_ALLOWED_LOCKED" 1 "PLG_MVMT_NOT_ALLOWED_LOW_12V" 0 "PLG_MVMT_NOT_ALLOWED_NONE" 3 "PLG_MVMT_NOT_ALLOWED_UNCALIBRATED" 2 "PLG_MVMT_NOT_ALLOWED_VEHICLE_AT_SPEED" ;
VAL_ 322 VCLEFT_liftgatePhysicalChimeRequ 0 "LIFTGATE_CHIME_REQUEST_NONE" 4 "LIFTGATE_CHIME_REQUEST_ONE_LONG" 1 "LIFTGATE_CHIME_REQUEST_ONE_SHORT" 3 "LIFTGATE_CHIME_REQUEST_THREE_SHORT" 2 "LIFTGATE_CHIME_REQUEST_TWO_SHORT" ;
VAL_ 322 VCLEFT_liftgateRequestSource 5 "PLG_REQUEST_SOURCE_CLOSE_ALL" 2 "PLG_REQUEST_SOURCE_EXTERIOR" 4 "PLG_REQUEST_SOURCE_KEY_TRUNK_BUTTON" 6 "PLG_REQUEST_SOURCE_MCU_CLOSE" 1 "PLG_REQUEST_SOURCE_MCU_SWITCH" 0 "PLG_REQUEST_SOURCE_NONE" 3 "PLG_REQUEST_SOURCE_SHUTFACE" 7 "PLG_REQUEST_SOURCE_UDS" ;
VAL_ 322 VCLEFT_liftgateState 2 "PLG_STATE_BACKOFF" 5 "PLG_STATE_CLOSED" 4 "PLG_STATE_CLOSING" 11 "PLG_STATE_END_OF_TRAVEL" 0 "PLG_STATE_INIT" 7 "PLG_STATE_LATCH_CLOSING" 12 "PLG_STATE_LATCH_ENTRY" 10 "PLG_STATE_LATCH_EXIT" 6 "PLG_STATE_LATCH_OPENING" 8 "PLG_STATE_NOT_INSTALLED" 1 "PLG_STATE_OFF" 3 "PLG_STATE_OPENING" 9 "PLG_STATE_UNKNOWN" ;
VAL_ 322 VCLEFT_liftgateStoppingCondition 11 "PLG_STOPPING_CONDITION_COUNT" 10 "PLG_STOPPING_CONDITION_LATCH_FAULT" 3 "PLG_STOPPING_CONDITION_LOW_12V" 0 "PLG_STOPPING_CONDITION_NONE" 6 "PLG_STOPPING_CONDITION_OBSTACLE_CURRENT" 2 "PLG_STOPPING_CONDITION_OBSTACLE_STALL" 7 "PLG_STOPPING_CONDITION_OBSTACLE_TRAJ_POS" 8 "PLG_STOPPING_CONDITION_OBSTACLE_TRAJ_VEL" 1 "PLG_STOPPING_CONDITION_PINCH" 4 "PLG_STOPPING_CONDITION_STATE_TIMEOUT" 9 "PLG_STOPPING_CONDITION_UNCALIBRATED" 5 "PLG_STOPPING_CONDITION_VEHICLE_AT_SPEED" ;
VAL_ 322 VCLEFT_liftgateUIChimeRequest 0 "LIFTGATE_CHIME_REQUEST_NONE" 4 "LIFTGATE_CHIME_REQUEST_ONE_LONG" 1 "LIFTGATE_CHIME_REQUEST_ONE_SHORT" 3 "LIFTGATE_CHIME_REQUEST_THREE_SHORT" 2 "LIFTGATE_CHIME_REQUEST_TWO_SHORT" ;
VAL_ 325 ESP_absBrakeEvent2 2 "ABS_EVENT_ACTIVE_FRONT" 1 "ABS_EVENT_ACTIVE_FRONT_REAR" 3 "ABS_EVENT_ACTIVE_REAR" 0 "ABS_EVENT_NOT_ACTIVE" ;
VAL_ 325 ESP_absFaultLamp 0 "ABS_FAULT_LAMP_OFF" 1 "ABS_FAULT_LAMP_ON" ;
VAL_ 325 ESP_brakeApply 1 "BLS_ACTIVE" 0 "BLS_INACTIVE" ;
VAL_ 325 ESP_brakeDiscWipingActive 1 "BDW_ACTIVE" 0 "BDW_INACTIVE" ;
VAL_ 325 ESP_brakeLamp 0 "LAMP_OFF" 1 "LAMP_ON" ;
VAL_ 325 ESP_brakeTorqueTarget 8191 "SNA" ;
VAL_ 325 ESP_btcTargetState 1 "BACKUP" 0 "OFF" 2 "ON" 3 "SNA" ;
VAL_ 325 ESP_cdpStatus 2 "ACTUATING_EPB_CDP" 3 "CDP_COMMAND_INVALID" 1 "CDP_IS_AVAILABLE" 0 "CDP_IS_NOT_AVAILABLE" ;
VAL_ 325 ESP_driverBrakeApply 2 "Driver_applying_brakes" 3 "Faulty_SNA" 0 "NotInit_orOff" 1 "Not_Applied" ;
VAL_ 325 ESP_ebdFaultLamp 0 "EBD_FAULT_LAMP_OFF" 1 "EBD_FAULT_LAMP_ON" ;
VAL_ 325 ESP_ebrStandstillSkid 0 "NO_STANDSTILL_SKID" 1 "STANDSTILL_SKID_DETECTED" ;
VAL_ 325 ESP_ebrStatus 2 "ACTUATING_DI_EBR" 3 "EBR_COMMAND_INVALID" 1 "EBR_IS_AVAILABLE" 0 "EBR_IS_NOT_AVAILABLE" ;
VAL_ 325 ESP_espFaultLamp 0 "ESP_FAULT_LAMP_OFF" 1 "ESP_FAULT_LAMP_ON" ;
VAL_ 325 ESP_espLampFlash 1 "ESP_LAMP_FLASH" 0 "ESP_LAMP_OFF" ;
VAL_ 325 ESP_espModeActive 0 "ESP_MODE_00_NORMAL" 1 "ESP_MODE_01" 2 "ESP_MODE_02" 3 "ESP_MODE_03" ;
VAL_ 325 ESP_lateralAccelQF 1 "IN_SPEC" 0 "UNDEFINABLE_ACCURACY" ;
VAL_ 325 ESP_longitudinalAccelQF 1 "IN_SPEC" 0 "UNDEFINABLE_ACCURACY" ;
VAL_ 325 ESP_ptcTargetState 1 "BACKUP" 0 "FAULT" 2 "ON" 3 "SNA" ;
VAL_ 325 ESP_stabilityControlSts2 2 "ENGAGED" 3 "FAULTED" 0 "INIT" 1 "ON" ;
VAL_ 325 ESP_steeringAngleQF 1 "IN_SPEC" 0 "UNDEFINABLE_ACCURACY" ;
VAL_ 325 ESP_yawRateQF 1 "IN_SPEC" 0 "UNDEFINABLE_ACCURACY" ;
VAL_ 522 HVP_fcContNegativeState 3 "CONTACTOR_STATE_BLOCKED" 6 "CONTACTOR_STATE_ECONOMIZED" 1 "CONTACTOR_STATE_OPEN" 5 "CONTACTOR_STATE_OPENING" 2 "CONTACTOR_STATE_PRECHARGE" 4 "CONTACTOR_STATE_PULLED_IN" 0 "CONTACTOR_STATE_SNA" 7 "CONTACTOR_STATE_WELDED" ;
VAL_ 522 HVP_fcContPositiveState 3 "CONTACTOR_STATE_BLOCKED" 6 "CONTACTOR_STATE_ECONOMIZED" 1 "CONTACTOR_STATE_OPEN" 5 "CONTACTOR_STATE_OPENING" 2 "CONTACTOR_STATE_PRECHARGE" 4 "CONTACTOR_STATE_PULLED_IN" 0 "CONTACTOR_STATE_SNA" 7 "CONTACTOR_STATE_WELDED" ;
VAL_ 522 HVP_fcContactorSetState 3 "CONTACTOR_SET_STATE_BLOCKED" 5 "CONTACTOR_SET_STATE_CLOSED" 2 "CONTACTOR_SET_STATE_CLOSING" 9 "CONTACTOR_SET_STATE_NEGATIVE_CLOSED" 1 "CONTACTOR_SET_STATE_OPEN" 4 "CONTACTOR_SET_STATE_OPENING" 6 "CONTACTOR_SET_STATE_PARTIAL_WELD" 8 "CONTACTOR_SET_STATE_POSITIVE_CLOSED" 0 "CONTACTOR_SET_STATE_SNA" 7 "CONTACTOR_SET_STATE_WELDED" ;
VAL_ 522 HVP_fcCtrsRequestStatus 1 "REQUEST_ACTIVE" 2 "REQUEST_COMPLETED" 0 "REQUEST_NOT_ACTIVE" ;
VAL_ 522 HVP_fcLinkAllowedToEnergize 1 "FC_LINK_ENERGY_AC" 2 "FC_LINK_ENERGY_DC" 0 "FC_LINK_ENERGY_NONE" ;
VAL_ 522 HVP_hvilStatus 2 "CURRENT_SOURCE_FAULT" 3 "INTERNAL_OPEN_FAULT" 8 "NO_12V_SUPPLY" 5 "PENTHOUSE_LID_OPEN_FAULT" 1 "STATUS_OK" 0 "UNKNOWN" 6 "UNKNOWN_LOCATION_OPEN_FAULT" 7 "VEHICLE_NODE_FAULT" 4 "VEHICLE_OPEN_FAULT" 9 "VEHICLE_OR_PENTHOUSE_LID_OPEN_FAULT" ;
VAL_ 522 HVP_packContNegativeState 3 "CONTACTOR_STATE_BLOCKED" 6 "CONTACTOR_STATE_ECONOMIZED" 1 "CONTACTOR_STATE_OPEN" 5 "CONTACTOR_STATE_OPENING" 2 "CONTACTOR_STATE_PRECHARGE" 4 "CONTACTOR_STATE_PULLED_IN" 0 "CONTACTOR_STATE_SNA" 7 "CONTACTOR_STATE_WELDED" ;
VAL_ 522 HVP_packContPositiveState 3 "CONTACTOR_STATE_BLOCKED" 6 "CONTACTOR_STATE_ECONOMIZED" 1 "CONTACTOR_STATE_OPEN" 5 "CONTACTOR_STATE_OPENING" 2 "CONTACTOR_STATE_PRECHARGE" 4 "CONTACTOR_STATE_PULLED_IN" 0 "CONTACTOR_STATE_SNA" 7 "CONTACTOR_STATE_WELDED" ;
VAL_ 522 HVP_packContactorSetState 3 "CONTACTOR_SET_STATE_BLOCKED" 5 "CONTACTOR_SET_STATE_CLOSED" 2 "CONTACTOR_SET_STATE_CLOSING" 9 "CONTACTOR_SET_STATE_NEGATIVE_CLOSED" 1 "CONTACTOR_SET_STATE_OPEN" 4 "CONTACTOR_SET_STATE_OPENING" 6 "CONTACTOR_SET_STATE_PARTIAL_WELD" 8 "CONTACTOR_SET_STATE_POSITIVE_CLOSED" 0 "CONTACTOR_SET_STATE_SNA" 7 "CONTACTOR_SET_STATE_WELDED" ;
VAL_ 522 HVP_packCtrsRequestStatus 1 "REQUEST_ACTIVE" 2 "REQUEST_COMPLETED" 0 "REQUEST_NOT_ACTIVE" ;
VAL_ 526 PARK_sdiSensor1RawDistData 0 "BLOCKED" 1 "NEAR_DETECTION" 500 "NO_OBJECT_DETECTED" 511 "SNA" ;
VAL_ 526 PARK_sdiSensor2RawDistData 0 "BLOCKED" 1 "NEAR_DETECTION" 500 "NO_OBJECT_DETECTED" 511 "SNA" ;
VAL_ 526 PARK_sdiSensor3RawDistData 0 "BLOCKED" 1 "NEAR_DETECTION" 500 "NO_OBJECT_DETECTED" 511 "SNA" ;
VAL_ 526 PARK_sdiSensor4RawDistData 0 "BLOCKED" 1 "NEAR_DETECTION" 500 "NO_OBJECT_DETECTED" 511 "SNA" ;
VAL_ 526 PARK_sdiSensor5RawDistData 0 "BLOCKED" 1 "NEAR_DETECTION" 500 "NO_OBJECT_DETECTED" 511 "SNA" ;
VAL_ 526 PARK_sdiSensor6RawDistData 0 "BLOCKED" 1 "NEAR_DETECTION" 500 "NO_OBJECT_DETECTED" 511 "SNA" ;
VAL_ 537 VCSEC_TPMSDataIndex 0 "TPMS_DATA_SENSOR_0" 1 "TPMS_DATA_SENSOR_1" 2 "TPMS_DATA_SENSOR_2" 3 "TPMS_DATA_SENSOR_3" ;
VAL_ 537 VCSEC_TPMSBatVoltage0 255 "SNA" ;
VAL_ 537 VCSEC_TPMSBatVoltage1 255 "SNA" ;
VAL_ 537 VCSEC_TPMSBatVoltage2 255 "SNA" ;
VAL_ 537 VCSEC_TPMSBatVoltage3 255 "SNA" ;
VAL_ 537 VCSEC_TPMSLocation0 0 "LOCATION_FL" 1 "LOCATION_FR" 2 "LOCATION_RL" 3 "LOCATION_RR" 4 "LOCATION_UNKNOWN" ;
VAL_ 537 VCSEC_TPMSLocation1 0 "LOCATION_FL" 1 "LOCATION_FR" 2 "LOCATION_RL" 3 "LOCATION_RR" 4 "LOCATION_UNKNOWN" ;
VAL_ 537 VCSEC_TPMSLocation2 0 "LOCATION_FL" 1 "LOCATION_FR" 2 "LOCATION_RL" 3 "LOCATION_RR" 4 "LOCATION_UNKNOWN" ;
VAL_ 537 VCSEC_TPMSLocation3 0 "LOCATION_FL" 1 "LOCATION_FR" 2 "LOCATION_RL" 3 "LOCATION_RR" 4 "LOCATION_UNKNOWN" ;
VAL_ 537 VCSEC_TPMSPressure0 255 "SNA" ;
VAL_ 537 VCSEC_TPMSPressure1 255 "SNA" ;
VAL_ 537 VCSEC_TPMSPressure2 255 "SNA" ;
VAL_ 537 VCSEC_TPMSPressure3 255 "SNA" ;
VAL_ 537 VCSEC_TPMSTemperature0 255 "SNA" ;
VAL_ 537 VCSEC_TPMSTemperature1 255 "SNA" ;
VAL_ 537 VCSEC_TPMSTemperature2 255 "SNA" ;
VAL_ 537 VCSEC_TPMSTemperature3 255 "SNA" ;
VAL_ 516 PCS_chargeShutdownRequest 2 "EMERGENCY_SHUTDOWN_REQUESTED" 1 "GRACEFUL_SHUTDOWN_REQUESTED" 0 "NO_SHUTDOWN_REQUESTED" ;
VAL_ 516 PCS_chgMainState 9 "PCS_CHG_STATE_CLEAR_FAULTS" 6 "PCS_CHG_STATE_ENABLE" 8 "PCS_CHG_STATE_FAULTED" 1 "PCS_CHG_STATE_IDLE" 0 "PCS_CHG_STATE_INIT" 4 "PCS_CHG_STATE_QUALIFY_LINE_CONFIG" 7 "PCS_CHG_STATE_SHUTDOWN" 2 "PCS_CHG_STATE_STARTUP" 5 "PCS_CHG_STATE_SYSTEM_CONFIG" 3 "PCS_CHG_STATE_WAIT_FOR_LINE_VOLTAGE" ;
VAL_ 516 PCS_gridConfig 1 "GRID_CONFIG_SINGLE_PHASE" 0 "GRID_CONFIG_SNA" 2 "GRID_CONFIG_THREE_PHASE" 3 "GRID_CONFIG_THREE_PHASE_DELTA" ;
VAL_ 516 PCS_hvChargeStatus 1 "PCS_CHARGE_BLOCKED" 2 "PCS_CHARGE_ENABLED" 3 "PCS_CHARGE_FAULTED" 0 "PCS_CHARGE_STANDBY" ;
VAL_ 516 PCS_hwVariantType 1 "PCS_32A_SINGLE_PHASE_VARIANT" 0 "PCS_48A_SINGLE_PHASE_VARIANT" 3 "PCS_HW_VARIANT_TYPE_SNA" 2 "PCS_THREE_PHASES_VARIANT" ;
VAL_ 554 HVP_dcLinkVoltageFiltered 550 "SNA" ;
VAL_ 554 HVP_pcsControlRequest 3 "DISCHARGE" 2 "PRECHARGE" 0 "SHUTDOWN" 1 "SUPPORT" ;
VAL_ 562 BMS_fcContactorRequest 1 "SET_REQUEST_CLOSE" 4 "SET_REQUEST_CLOSE_NEGATIVE_ONLY" 5 "SET_REQUEST_CLOSE_POSITIVE_ONLY" 2 "SET_REQUEST_OPEN" 3 "SET_REQUEST_OPEN_IMMEDIATELY" 0 "SET_REQUEST_SNA" ;
VAL_ 562 BMS_fcLinkOkToEnergizeRequest 1 "FC_LINK_ENERGY_AC" 2 "FC_LINK_ENERGY_DC" 0 "FC_LINK_ENERGY_NONE" ;
VAL_ 562 BMS_internalHvilSenseV 65535 "SNA" ;
VAL_ 562 BMS_packContactorRequest 1 "SET_REQUEST_CLOSE" 4 "SET_REQUEST_CLOSE_NEGATIVE_ONLY" 5 "SET_REQUEST_CLOSE_POSITIVE_ONLY" 2 "SET_REQUEST_OPEN" 3 "SET_REQUEST_OPEN_IMMEDIATELY" 0 "SET_REQUEST_SNA" ;
VAL_ 627 UI_displayBrightnessLevel 255 "SNA" ;
VAL_ 627 UI_domeLightSwitch 2 "DOME_LIGHT_SWITCH_AUTO" 0 "DOME_LIGHT_SWITCH_OFF" 1 "DOME_LIGHT_SWITCH_ON" ;
VAL_ 627 UI_driveStateRequest 0 "DRIVE_STATE_REQ_IDLE" 1 "DRIVE_STATE_REQ_START" ;
VAL_ 627 UI_frontLeftSeatHeatReq 1 "HEATER_REQUEST_LEVEL1" 2 "HEATER_REQUEST_LEVEL2" 3 "HEATER_REQUEST_LEVEL3" 0 "HEATER_REQUEST_OFF" ;
VAL_ 627 UI_frontRightSeatHeatReq 1 "HEATER_REQUEST_LEVEL1" 2 "HEATER_REQUEST_LEVEL2" 3 "HEATER_REQUEST_LEVEL3" 0 "HEATER_REQUEST_OFF" ;
VAL_ 627 UI_lockRequest 0 "UI_LOCK_REQUEST_IDLE" 1 "UI_LOCK_REQUEST_LOCK" 4 "UI_LOCK_REQUEST_REMOTE_LOCK" 3 "UI_LOCK_REQUEST_REMOTE_UNLOCK" 7 "UI_LOCK_REQUEST_SNA" 2 "UI_LOCK_REQUEST_UNLOCK" ;
VAL_ 627 UI_mirrorFoldRequest 0 "MIRROR_FOLD_REQUEST_IDLE" 2 "MIRROR_FOLD_REQUEST_PRESENT" 1 "MIRROR_FOLD_REQUEST_RETRACT" 3 "MIRROR_FOLD_REQUEST_SNA" ;
VAL_ 627 UI_rearCenterSeatHeatReq 1 "HEATER_REQUEST_LEVEL1" 2 "HEATER_REQUEST_LEVEL2" 3 "HEATER_REQUEST_LEVEL3" 0 "HEATER_REQUEST_OFF" ;
VAL_ 627 UI_rearLeftSeatHeatReq 1 "HEATER_REQUEST_LEVEL1" 2 "HEATER_REQUEST_LEVEL2" 3 "HEATER_REQUEST_LEVEL3" 0 "HEATER_REQUEST_OFF" ;
VAL_ 627 UI_rearRightSeatHeatReq 1 "HEATER_REQUEST_LEVEL1" 2 "HEATER_REQUEST_LEVEL2" 3 "HEATER_REQUEST_LEVEL3" 0 "HEATER_REQUEST_OFF" ;
VAL_ 627 UI_remoteClosureRequest 2 "UI_REMOTE_CLOSURE_REQUEST_FRONT_TRUNK_MOVE" 0 "UI_REMOTE_CLOSURE_REQUEST_IDLE" 1 "UI_REMOTE_CLOSURE_REQUEST_REAR_TRUNK_MOVE" 3 "UI_REMOTE_CLOSURE_REQUEST_SNA" ;
VAL_ 627 UI_remoteStartRequest 0 "UI_REMOTE_START_REQUEST_IDLE" 4 "UI_REMOTE_START_REQUEST_SNA" 1 "UI_REMOTE_START_REQUEST_START" ;
VAL_ 627 UI_steeringBacklightEnabled 0 "STEERING_BACKLIGHT_DISABLED" 1 "STEERING_BACKLIGHT_ENABLED" ;
VAL_ 627 UI_steeringButtonMode 4 "STEERING_BUTTON_MODE_HEADLIGHT_LEFT" 5 "STEERING_BUTTON_MODE_HEADLIGHT_RIGHT" 2 "STEERING_BUTTON_MODE_MIRROR_LEFT" 3 "STEERING_BUTTON_MODE_MIRROR_RIGHT" 0 "STEERING_BUTTON_MODE_OFF" 1 "STEERING_BUTTON_MODE_STEERING_COLUMN_ADJ" ;
VAL_ 627 UI_wiperMode 2 "WIPER_MODE_NORMAL" 3 "WIPER_MODE_PARK" 1 "WIPER_MODE_SERVICE" 0 "WIPER_MODE_SNA" ;
VAL_ 627 UI_wiperRequest 2 "WIPER_REQUEST_AUTO" 6 "WIPER_REQUEST_FAST_CONTINUOUS" 4 "WIPER_REQUEST_FAST_INTERMITTENT" 1 "WIPER_REQUEST_OFF" 5 "WIPER_REQUEST_SLOW_CONTINUOUS" 3 "WIPER_REQUEST_SLOW_INTERMITTENT" 0 "WIPER_REQUEST_SNA" ;
VAL_ 1066 VCSEC_TPMSConnectionTypeCurrent0 0 "CONNECTIONTYPE_FAST" 1 "CONNECTIONTYPE_SLOW" 2 "CONNECTIONTYPE_UNKNOWN" ;
VAL_ 1066 VCSEC_TPMSConnectionTypeCurrent1 0 "CONNECTIONTYPE_FAST" 1 "CONNECTIONTYPE_SLOW" 2 "CONNECTIONTYPE_UNKNOWN" ;
VAL_ 1066 VCSEC_TPMSConnectionTypeCurrent2 0 "CONNECTIONTYPE_FAST" 1 "CONNECTIONTYPE_SLOW" 2 "CONNECTIONTYPE_UNKNOWN" ;
VAL_ 1066 VCSEC_TPMSConnectionTypeCurrent3 0 "CONNECTIONTYPE_FAST" 1 "CONNECTIONTYPE_SLOW" 2 "CONNECTIONTYPE_UNKNOWN" ;
VAL_ 1066 VCSEC_TPMSConnectionTypeDesired0 0 "CONNECTIONTYPE_FAST" 1 "CONNECTIONTYPE_SLOW" 2 "CONNECTIONTYPE_UNKNOWN" ;
VAL_ 1066 VCSEC_TPMSConnectionTypeDesired1 0 "CONNECTIONTYPE_FAST" 1 "CONNECTIONTYPE_SLOW" 2 "CONNECTIONTYPE_UNKNOWN" ;
VAL_ 1066 VCSEC_TPMSConnectionTypeDesired2 0 "CONNECTIONTYPE_FAST" 1 "CONNECTIONTYPE_SLOW" 2 "CONNECTIONTYPE_UNKNOWN" ;
VAL_ 1066 VCSEC_TPMSConnectionTypeDesired3 0 "CONNECTIONTYPE_FAST" 1 "CONNECTIONTYPE_SLOW" 2 "CONNECTIONTYPE_UNKNOWN" ;
VAL_ 1066 VCSEC_TPMSSensorState0 3 "SENSOR_CONNECTED" 4 "SENSOR_DISCONNECTING" 0 "SENSOR_NOT_PAIRED" 1 "SENSOR_WAIT_FOR_ADV" 2 "SENSOR_WAIT_FOR_CONN" ;
VAL_ 1066 VCSEC_TPMSSensorState1 3 "SENSOR_CONNECTED" 4 "SENSOR_DISCONNECTING" 0 "SENSOR_NOT_PAIRED" 1 "SENSOR_WAIT_FOR_ADV" 2 "SENSOR_WAIT_FOR_CONN" ;
VAL_ 1066 VCSEC_TPMSSensorState2 3 "SENSOR_CONNECTED" 4 "SENSOR_DISCONNECTING" 0 "SENSOR_NOT_PAIRED" 1 "SENSOR_WAIT_FOR_ADV" 2 "SENSOR_WAIT_FOR_CONN" ;
VAL_ 1066 VCSEC_TPMSSensorState3 3 "SENSOR_CONNECTED" 4 "SENSOR_DISCONNECTING" 0 "SENSOR_NOT_PAIRED" 1 "SENSOR_WAIT_FOR_ADV" 2 "SENSOR_WAIT_FOR_CONN" ;
VAL_ 558 PARK_sdiSensor10RawDistData 0 "BLOCKED" 1 "NEAR_DETECTION" 500 "NO_OBJECT_DETECTED" 511 "SNA" ;
VAL_ 558 PARK_sdiSensor11RawDistData 0 "BLOCKED" 1 "NEAR_DETECTION" 500 "NO_OBJECT_DETECTED" 511 "SNA" ;
VAL_ 558 PARK_sdiSensor12RawDistData 0 "BLOCKED" 1 "NEAR_DETECTION" 500 "NO_OBJECT_DETECTED" 511 "SNA" ;
VAL_ 558 PARK_sdiSensor7RawDistData 0 "BLOCKED" 1 "NEAR_DETECTION" 500 "NO_OBJECT_DETECTED" 511 "SNA" ;
VAL_ 558 PARK_sdiSensor8RawDistData 0 "BLOCKED" 1 "NEAR_DETECTION" 500 "NO_OBJECT_DETECTED" 511 "SNA" ;
VAL_ 558 PARK_sdiSensor9RawDistData 0 "BLOCKED" 1 "NEAR_DETECTION" 500 "NO_OBJECT_DETECTED" 511 "SNA" ;
VAL_ 568 UI_countryCode 1023 "SNA" 0 "UNKNOWN" ;
VAL_ 568 UI_mapSpeedLimit 3 "LESS_OR_EQ_10" 21 "LESS_OR_EQ_100" 22 "LESS_OR_EQ_105" 23 "LESS_OR_EQ_110" 24 "LESS_OR_EQ_115" 25 "LESS_OR_EQ_120" 26 "LESS_OR_EQ_130" 27 "LESS_OR_EQ_140" 4 "LESS_OR_EQ_15" 28 "LESS_OR_EQ_150" 29 "LESS_OR_EQ_160" 5 "LESS_OR_EQ_20" 6 "LESS_OR_EQ_25" 7 "LESS_OR_EQ_30" 8 "LESS_OR_EQ_35" 9 "LESS_OR_EQ_40" 10 "LESS_OR_EQ_45" 1 "LESS_OR_EQ_5" 11 "LESS_OR_EQ_50" 12 "LESS_OR_EQ_55" 13 "LESS_OR_EQ_60" 14 "LESS_OR_EQ_65" 2 "LESS_OR_EQ_7" 15 "LESS_OR_EQ_70" 16 "LESS_OR_EQ_75" 17 "LESS_OR_EQ_80" 18 "LESS_OR_EQ_85" 19 "LESS_OR_EQ_90" 20 "LESS_OR_EQ_95" 31 "SNA" 0 "UNKNOWN" 30 "UNLIMITED" ;
VAL_ 568 UI_mapSpeedLimitDependency 6 "LANE" 0 "NONE" 2 "RAIN" 1 "SCHOOL" 5 "SEASON" 7 "SNA" 3 "SNOW" 4 "TIME" ;
VAL_ 568 UI_mapSpeedLimitType 2 "ADVISORY" 4 "BUMPS" 3 "DEPENDENT" 1 "REGULAR" 7 "UNKNOWN_SNA" ;
VAL_ 568 UI_mapSpeedUnits 1 "KPH" 0 "MPH" ;
VAL_ 568 UI_nextBranchDist 31 "SNA" ;
VAL_ 568 UI_roadClass 1 "CLASS_1_MAJOR" 2 "CLASS_2" 3 "CLASS_3" 4 "CLASS_4" 5 "CLASS_5" 6 "CLASS_6_MINOR" 0 "UNKNOWN_INVALID_SNA" ;
VAL_ 569 DAS_leftFork 1 "LEFT_FORK_AVAILABLE" 0 "LEFT_FORK_NONE" 2 "LEFT_FORK_SELECTED" 3 "LEFT_FORK_UNAVAILABLE" ;
VAL_ 569 DAS_leftLineUsage 1 "AVAILABLE" 3 "BLACKLISTED" 2 "FUSED" 0 "REJECTED_UNAVAILABLE" ;
VAL_ 569 DAS_rightFork 1 "RIGHT_FORK_AVAILABLE" 0 "RIGHT_FORK_NONE" 2 "RIGHT_FORK_SELECTED" 3 "RIGHT_FORK_UNAVAILABLE" ;
VAL_ 569 DAS_rightLineUsage 1 "AVAILABLE" 3 "BLACKLISTED" 2 "FUSED" 0 "REJECTED_UNAVAILABLE" ;
VAL_ 586 DAS_accSmartSpeedState 2 "ACTIVE_INTEGRATING" 1 "ACTIVE_OFFRAMP" 3 "ACTIVE_ONRAMP" 0 "NOT_ACTIVE" 5 "OFFRAMP_DELAY" 4 "SET_SPEED_SET_REQUESTED" 7 "SNA" ;
VAL_ 586 DAS_autosteerBottsDotsUsage 1 "AVAILABLE" 3 "BLACKLISTED" 2 "FUSED" 0 "REJECTED_UNAVAILABLE" ;
VAL_ 586 DAS_autosteerHPPUsage 1 "AVAILABLE" 3 "BLACKLISTED" 2 "FUSED" 0 "REJECTED_UNAVAILABLE" ;
VAL_ 586 DAS_autosteerHealthState 4 "HEALTH_ABORTING" 2 "HEALTH_DEGRADED" 5 "HEALTH_FAULT" 1 "HEALTH_NOMINAL" 3 "HEALTH_SEVERELY_DEGRADED" 0 "HEALTH_UNAVAILABLE" ;
VAL_ 586 DAS_autosteerModelUsage 1 "AVAILABLE" 3 "BLACKLISTED" 2 "FUSED" 0 "REJECTED_UNAVAILABLE" ;
VAL_ 586 DAS_autosteerNavigationUsage 1 "AVAILABLE" 3 "BLACKLISTED" 2 "FUSED" 0 "REJECTED_UNAVAILABLE" ;
VAL_ 586 DAS_autosteerVehiclesUsage 1 "AVAILABLE" 3 "BLACKLISTED" 2 "FUSED" 0 "REJECTED_UNAVAILABLE" ;
VAL_ 586 DAS_behaviorType 0 "DAS_BEHAVIOR_INVALID" 1 "DAS_BEHAVIOR_IN_LANE" 2 "DAS_BEHAVIOR_LANE_CHANGE_LEFT" 3 "DAS_BEHAVIOR_LANE_CHANGE_RIGHT" ;
VAL_ 586 DAS_lastAutosteerAbortReason 29 "UI_ABORT_REASON_ACC_CANCEL" 32 "UI_ABORT_REASON_AEB" 14 "UI_ABORT_REASON_APP_ME_STATE_NOT_VISION" 30 "UI_ABORT_REASON_CAMERA_FAILSAFES" 16 "UI_ABORT_REASON_CAM_MSG_MIA" 17 "UI_ABORT_REASON_CAM_WATCHDOG" 23 "UI_ABORT_REASON_CID_SWITCH_DISABLED" 21 "UI_ABORT_REASON_COMPONENT_MIA" 22 "UI_ABORT_REASON_CRUISE_FAULT" 24 "UI_ABORT_REASON_DRIVING_OFF_NAV" 20 "UI_ABORT_REASON_EPAS_EAC_DENIED" 28 "UI_ABORT_REASON_EPAS_ERROR_CODE" 26 "UI_ABORT_REASON_FOLLOWER_OUTPUT_INVALID" 0 "UI_ABORT_REASON_HM_LANE_VIEW_RANGE" 2 "UI_ABORT_REASON_HM_STEERING_ERROR" 1 "UI_ABORT_REASON_HM_VIRTUAL_LANE_NO_INPUTS" 15 "UI_ABORT_REASON_ME_MAIN_STATE_NOT_VISION" 31 "UI_ABORT_REASON_NO_ABORT" 27 "UI_ABORT_REASON_PLANNER_OUTPUT_INVALID" 33 "UI_ABORT_REASON_SEATBELT_UNBUCKLED" 19 "UI_ABORT_REASON_SIDE_COLLISION_IMMINENT" 18 "UI_ABORT_REASON_TRAILER_MODE" 34 "UI_ABORT_REASON_USER_OVERRIDE_STRIKEOUT" 25 "UI_ABORT_REASON_VEHICLE_SPEED_ABOVE_MAX" ;
VAL_ 586 DAS_lastLinePreferenceReason 1 "AGREEMENT_WITH_NEIGHBOR_LANES" 4 "AVOID_ONCOMING_LANES" 5 "COUNTRY_DRIVING_SIDE" 3 "NAVIGATION_BRANCH" 2 "NEIGHBOR_LANE_PROBABILIY" 15 "NONE" 0 "OTHER_LANE_DISAGREES_WITH_MODEL" ;
VAL_ 586 DAS_navAvailable 1 "DAS_NAV_AVAILABLE" 0 "DAS_NAV_UNAVAILABLE" ;
VAL_ 586 DAS_offsetSide 0 "NO_OFFSET" 3 "OFFSET_BOTH_OBJECTS" 2 "OFFSET_LEFT_OBJECT" 1 "OFFSET_RIGHT_OBJECT" ;
VAL_ 586 DAS_plannerState 0 "TP_EXTSTATE_DISABLED" 2 "TP_EXTSTATE_FOLLOW" 7 "TP_EXTSTATE_LANECHANGE_ABORT" 4 "TP_EXTSTATE_LANECHANGE_IN_PROGRESS" 3 "TP_EXTSTATE_LANECHANGE_REQUESTED" 6 "TP_EXTSTATE_LANECHANGE_WAIT_FOR_FWD_OBSTACLE" 5 "TP_EXTSTATE_LANECHANGE_WAIT_FOR_SIDE_OBSTACLE" 1 "TP_EXTSTATE_VL" ;
VAL_ 586 DAS_rearLeftVehDetectedCurrent 1 "VEHICLE_DETECTED" 0 "VEHICLE_NOT_DETECTED" ;
VAL_ 586 DAS_rearLeftVehDetectedTrip 1 "VEHICLE_DETECTED" 0 "VEHICLE_NOT_DETECTED" ;
VAL_ 586 DAS_rearRightVehDetectedTrip 1 "VEHICLE_DETECTED" 0 "VEHICLE_NOT_DETECTED" ;
VAL_ 586 DAS_rearVehDetectedThisCycle 1 "VEHICLE_DETECTED" 0 "VEHICLE_NOT_DETECTED" ;
VAL_ 586 DAS_roadSurfaceType 2 "ROAD_SURFACE_ENHANCED" 1 "ROAD_SURFACE_NORMAL" 0 "ROAD_SURFACE_SNA" ;
VAL_ 586 DAS_ulcInProgress 1 "ULC_ACTIVE" 0 "ULC_INACTIVE" ;
VAL_ 586 DAS_ulcType 1 "ULC_TYPE_NAV" 0 "ULC_TYPE_NONE" 2 "ULC_TYPE_SPEED" ;
VAL_ 605 CP_UHF_controlState 3 "CP_UHF_CALIBRATE" 6 "CP_UHF_CHECK_RX" 1 "CP_UHF_CONFIG" 10 "CP_UHF_FAULT" 8 "CP_UHF_HANDLE_FOUND" 2 "CP_UHF_IDLE" 0 "CP_UHF_INIT" 4 "CP_UHF_PREPARE_RX" 7 "CP_UHF_READ_RXFIFO" 5 "CP_UHF_RX" 9 "CP_UHF_SLEEP" ;
VAL_ 605 CP_chargeCablePresent 0 "CABLE_NOT_PRESENT" 1 "CABLE_PRESENT" ;
VAL_ 605 CP_chargeCableState 2 "CHARGE_CABLE_CONNECTED" 1 "CHARGE_CABLE_NOT_CONNECTED" 0 "CHARGE_CABLE_UNKNOWN_SNA" ;
VAL_ 605 CP_coldWeatherMode 1 "CP_COLD_WEATHER_LATCH_MITIGATION" 0 "CP_COLD_WEATHER_NONE" ;
VAL_ 605 CP_doorControlState 5 "CP_doorClosing" 1 "CP_doorIdle" 0 "CP_doorInit" 2 "CP_doorOpenRequested" 3 "CP_doorOpening" 6 "CP_doorSenseClosed" 4 "CP_doorSenseOpen" ;
VAL_ 605 CP_faultLineSensed 0 "FAULT_LINE_CLEARED" 1 "FAULT_LINE_SET" ;
VAL_ 605 CP_inductiveDoorState 7 "CP_INDUCTIVE_DOOR_FAULT" 0 "CP_INDUCTIVE_DOOR_INIT" 1 "CP_INDUCTIVE_DOOR_INIT_FROM_CHARGE" 2 "CP_INDUCTIVE_DOOR_INIT_FROM_DRIVE" 4 "CP_INDUCTIVE_DOOR_NOT_PRESENT" 6 "CP_INDUCTIVE_DOOR_OFF_CHARGE" 5 "CP_INDUCTIVE_DOOR_OFF_DRIVE" 3 "CP_INDUCTIVE_DOOR_PRESENT" ;
VAL_ 605 CP_inductiveSensorState 7 "CP_INDUCTIVE_SENSOR_CONFIG" 5 "CP_INDUCTIVE_SENSOR_FAULT" 0 "CP_INDUCTIVE_SENSOR_INIT" 3 "CP_INDUCTIVE_SENSOR_PAUSE" 1 "CP_INDUCTIVE_SENSOR_POLL" 6 "CP_INDUCTIVE_SENSOR_RESET" 2 "CP_INDUCTIVE_SENSOR_SHUTDOWN" 4 "CP_INDUCTIVE_SENSOR_WAIT_FOR_INIT" ;
VAL_ 605 CP_latch2ControlState 2 "CP_latchDisengageRequested" 4 "CP_latchDisengaged" 3 "CP_latchDisengaging" 5 "CP_latchEngaging" 1 "CP_latchIdle" 0 "CP_latchInit" ;
VAL_ 605 CP_latch2State 3 "CP_LATCH_BLOCKING" 1 "CP_LATCH_DISENGAGED" 2 "CP_LATCH_ENGAGED" 0 "CP_LATCH_SNA" ;
VAL_ 605 CP_latchControlState 2 "CP_latchDisengageRequested" 4 "CP_latchDisengaged" 3 "CP_latchDisengaging" 5 "CP_latchEngaging" 1 "CP_latchIdle" 0 "CP_latchInit" ;
VAL_ 605 CP_latchState 3 "CP_LATCH_BLOCKING" 1 "CP_LATCH_DISENGAGED" 2 "CP_LATCH_ENGAGED" 0 "CP_LATCH_SNA" ;
VAL_ 605 CP_ledColor 7 "CP_LEDS_AMBER" 3 "CP_LEDS_BLUE" 9 "CP_LEDS_DEBUG" 6 "CP_LEDS_FLASHING_AMBER" 10 "CP_LEDS_FLASHING_BLUE" 5 "CP_LEDS_FLASHING_GREEN" 2 "CP_LEDS_GREEN" 0 "CP_LEDS_OFF" 8 "CP_LEDS_RAVE" 1 "CP_LEDS_RED" 4 "CP_LEDS_WHITE" ;
VAL_ 605 CP_type 1 "CP_TYPE_EURO_IEC" 2 "CP_TYPE_GB" 3 "CP_TYPE_IEC_CCS" 0 "CP_TYPE_US_TESLA" ;
VAL_ 697 DAS_accState 1 "ACC_CANCEL_CAMERA_BLIND" 0 "ACC_CANCEL_GENERIC" 13 "ACC_CANCEL_GENERIC_SILENT" 14 "ACC_CANCEL_OUT_OF_CALIBRATION" 12 "ACC_CANCEL_PATH_NOT_CLEAR" 2 "ACC_CANCEL_RADAR_BLIND" 3 "ACC_HOLD" 4 "ACC_ON" 8 "APC_ABORT" 5 "APC_BACKWARD" 7 "APC_COMPLETE" 6 "APC_FORWARD" 9 "APC_PAUSE" 11 "APC_SELFPARK_START" 10 "APC_UNPARK_COMPLETE" 15 "FAULT_SNA" ;
VAL_ 697 DAS_accelMax 511 "SNA" ;
VAL_ 697 DAS_accelMin 511 "SNA" ;
VAL_ 697 DAS_aebEvent 1 "AEB_ACTIVE" 2 "AEB_FAULT" 0 "AEB_NOT_ACTIVE" 3 "AEB_SNA" ;
VAL_ 697 DAS_jerkMax 255 "SNA" ;
VAL_ 697 DAS_jerkMin 511 "SNA" ;
VAL_ 697 DAS_setSpeed 4095 "SNA" ;
VAL_ 723 UI_isSunUp 0 "SUN_DOWN" 3 "SUN_SNA" 1 "SUN_UP" ;
VAL_ 723 UI_solarAzimuthAngle 32768 "SNA" ;
VAL_ 723 UI_solarAzimuthAngleCarRef 255 "SNA" ;
VAL_ 723 UI_solarElevationAngle 127 "SNA" ;
VAL_ 777 DAS_objectId 3 "CUTIN_VEHICLE" 0 "LEAD_VEHICLES" 1 "LEFT_VEHICLES" 2 "RIGHT_VEHICLES" 4 "ROAD_SIGN" 5 "VEHICLE_HEADINGS" ;
VAL_ 777 DAS_cutinVehDx 255 "SNA" ;
VAL_ 777 DAS_cutinVehHeading 255 "SNA" ;
VAL_ 777 DAS_cutinVehId 127 "SNA" ;
VAL_ 777 DAS_cutinVehType 4 "BICYCLE" 2 "CAR" 3 "MOTORCYCLE" 5 "PEDESTRIAN" 1 "TRUCK" 0 "UNKNOWN" ;
VAL_ 777 DAS_cutinVehVxRel 15 "SNA" ;
VAL_ 777 DAS_leadVeh2Dx 255 "SNA" ;
VAL_ 777 DAS_leadVeh2Heading 255 "SNA" ;
VAL_ 777 DAS_leadVeh2Id 0 "SNA" ;
VAL_ 777 DAS_leadVeh2Type 4 "BICYCLE" 2 "CAR" 3 "MOTORCYCLE" 5 "PEDESTRIAN" 1 "TRUCK" 0 "UNKNOWN" ;
VAL_ 777 DAS_leadVeh2VxRel 15 "SNA" ;
VAL_ 777 DAS_leadVehDx 255 "SNA" ;
VAL_ 777 DAS_leadVehHeading 255 "SNA" ;
VAL_ 777 DAS_leadVehId 127 "SNA" ;
VAL_ 777 DAS_leadVehType 4 "BICYCLE" 2 "CAR" 6 "IPSO" 3 "MOTORCYCLE" 5 "PEDESTRIAN" 1 "TRUCK" 0 "UNKNOWN" ;
VAL_ 777 DAS_leadVehVxRel 15 "SNA" ;
VAL_ 777 DAS_leftVeh2Dx 255 "SNA" ;
VAL_ 777 DAS_leftVeh2Heading 255 "SNA" ;
VAL_ 777 DAS_leftVeh2Id 0 "SNA" ;
VAL_ 777 DAS_leftVeh2Type 4 "BICYCLE" 2 "CAR" 3 "MOTORCYCLE" 5 "PEDESTRIAN" 1 "TRUCK" 0 "UNKNOWN" ;
VAL_ 777 DAS_leftVeh2VxRel 15 "SNA" ;
VAL_ 777 DAS_leftVehDx 255 "SNA" ;
VAL_ 777 DAS_leftVehHeading 255 "SNA" ;
VAL_ 777 DAS_leftVehId 127 "SNA" ;
VAL_ 777 DAS_leftVehType 4 "BICYCLE" 2 "CAR" 3 "MOTORCYCLE" 5 "PEDESTRIAN" 1 "TRUCK" 0 "UNKNOWN" ;
VAL_ 777 DAS_leftVehVxRel 15 "SNA" ;
VAL_ 777 DAS_rightVeh2Dx 255 "SNA" ;
VAL_ 777 DAS_rightVeh2Heading 255 "SNA" ;
VAL_ 777 DAS_rightVeh2Id 0 "SNA" ;
VAL_ 777 DAS_rightVeh2Type 4 "BICYCLE" 2 "CAR" 3 "MOTORCYCLE" 5 "PEDESTRIAN" 1 "TRUCK" 0 "UNKNOWN" ;
VAL_ 777 DAS_rightVeh2VxRel 15 "SNA" ;
VAL_ 777 DAS_rightVehDx 255 "SNA" ;
VAL_ 777 DAS_rightVehHeading 255 "SNA" ;
VAL_ 777 DAS_rightVehId 127 "SNA" ;
VAL_ 777 DAS_rightVehType 4 "BICYCLE" 2 "CAR" 3 "MOTORCYCLE" 5 "PEDESTRIAN" 1 "TRUCK" 0 "UNKNOWN" ;
VAL_ 777 DAS_rightVehVxRel 15 "SNA" ;
VAL_ 777 DAS_roadSignArrow 0 "CIRCLE" 1 "LEFT" 2 "RIGHT" 3 "STRAIGHT" 4 "UNKNOWN" ;
VAL_ 777 DAS_roadSignColor 3 "GREEN" 0 "NONE" 1 "RED" 4 "RED_YELLOW" 2 "YELLOW" ;
VAL_ 777 DAS_roadSignId 255 "SNA" 0 "STOP_SIGN" 1 "TRAFFIC_LIGHT" ;
VAL_ 777 DAS_roadSignOrientation 2 "HORIZONTAL_3_LIGHT" 0 "UNKNOWN" 1 "VERTICAL_3_LIGHT" ;
VAL_ 777 DAS_roadSignSource 1 "NAV" 0 "NONE" 2 "VISION" ;
VAL_ 777 DAS_roadSignStopLineDist 1023 "SNA" ;
VAL_ 905 DAS_ACC_report 24 "ACC_REPORT_BEHAVIOR_REPORT" 23 "ACC_REPORT_CAMERA_ONLY" 21 "ACC_REPORT_CIPV_CUTTING_OUT" 10 "ACC_REPORT_CSA" 18 "ACC_REPORT_FLEET_SPEEDS" 13 "ACC_REPORT_LC_EXTERNAL_STATE_ABORTED" 12 "ACC_REPORT_LC_EXTERNAL_STATE_ABORTING" 14 "ACC_REPORT_LC_EXTERNAL_STATE_ACTIVE_RESTRICTED" 11 "ACC_REPORT_LC_HANDS_ON_REQD_STRUCK_OUT" 19 "ACC_REPORT_MCVLR_DPP" 20 "ACC_REPORT_MCVLR_IN_PATH" 22 "ACC_REPORT_RADAR_OBJ_FIVE" 15 "ACC_REPORT_RADAR_OBJ_ONE" 16 "ACC_REPORT_RADAR_OBJ_TWO" 1 "ACC_REPORT_TARGET_CIPV" 5 "ACC_REPORT_TARGET_CUTIN" 2 "ACC_REPORT_TARGET_IN_FRONT_OF_CIPV" 17 "ACC_REPORT_TARGET_MCP" 3 "ACC_REPORT_TARGET_MCVL" 4 "ACC_REPORT_TARGET_MCVR" 0 "ACC_REPORT_TARGET_NONE" 9 "ACC_REPORT_TARGET_TYPE_FAULT" 8 "ACC_REPORT_TARGET_TYPE_IPSO" 6 "ACC_REPORT_TARGET_TYPE_STOP_SIGN" 7 "ACC_REPORT_TARGET_TYPE_TRAFFIC_LIGHT" ;
VAL_ 905 DAS_accSpeedLimit 0 "NONE" 1023 "SNA" ;
VAL_ 905 DAS_activationFailureStatus 1 "LC_ACTIVATION_FAILED_1" 2 "LC_ACTIVATION_FAILED_2" 0 "LC_ACTIVATION_IDLE" ;
VAL_ 905 DAS_csaState 1 "CSA_EXTERNAL_STATE_AVAILABLE" 2 "CSA_EXTERNAL_STATE_ENABLE" 3 "CSA_EXTERNAL_STATE_HOLD" 0 "CSA_EXTERNAL_STATE_UNAVAILABLE" ;
VAL_ 905 DAS_driverInteractionLevel 2 "CONTINUED_DRIVER_NOT_INTERACTING" 0 "DRIVER_INTERACTING" 1 "DRIVER_NOT_INTERACTING" ;
VAL_ 905 DAS_longCollisionWarning 3 "FCM_LONG_COLLISION_WARNING_IPSO" 0 "FCM_LONG_COLLISION_WARNING_NONE" 2 "FCM_LONG_COLLISION_WARNING_PEDESTRIAN" 15 "FCM_LONG_COLLISION_WARNING_SNA" 4 "FCM_LONG_COLLISION_WARNING_STOPSIGN_STOPLINE" 5 "FCM_LONG_COLLISION_WARNING_TFL_STOPLINE" 6 "FCM_LONG_COLLISION_WARNING_VEHICLE_CIPV" 12 "FCM_LONG_COLLISION_WARNING_VEHICLE_CIPV2" 7 "FCM_LONG_COLLISION_WARNING_VEHICLE_CUTIN" 8 "FCM_LONG_COLLISION_WARNING_VEHICLE_MCVL" 9 "FCM_LONG_COLLISION_WARNING_VEHICLE_MCVL2" 10 "FCM_LONG_COLLISION_WARNING_VEHICLE_MCVR" 11 "FCM_LONG_COLLISION_WARNING_VEHICLE_MCVR2" 1 "FCM_LONG_COLLISION_WARNING_VEHICLE_UNKNOWN" ;
VAL_ 905 DAS_pmmCameraFaultReason 1 "PMM_CAMERA_BLOCKED_FRONT" 2 "PMM_CAMERA_INVALID_MIA" 0 "PMM_CAMERA_NO_FAULT" ;
VAL_ 905 DAS_pmmLoggingRequest 0 "FALSE" 1 "TRUE" ;
VAL_ 905 DAS_pmmObstacleSeverity 6 "PMM_ACCEL_LIMIT" 3 "PMM_BRAKE_REQUEST" 5 "PMM_CRASH_FRONT" 4 "PMM_CRASH_REAR" 2 "PMM_IMMINENT_FRONT" 1 "PMM_IMMINENT_REAR" 0 "PMM_NONE" 7 "PMM_SNA" ;
VAL_ 905 DAS_pmmRadarFaultReason 1 "PMM_RADAR_BLOCKED_FRONT" 2 "PMM_RADAR_INVALID_MIA" 0 "PMM_RADAR_NO_FAULT" ;
VAL_ 905 DAS_pmmSysFaultReason 7 "PMM_FAULT_BRAKE_PEDAL_INHIBIT" 1 "PMM_FAULT_DAS_DISABLED" 5 "PMM_FAULT_DISABLED_BY_USER" 3 "PMM_FAULT_DI_FAULT" 0 "PMM_FAULT_NONE" 6 "PMM_FAULT_ROAD_TYPE" 2 "PMM_FAULT_SPEED" 4 "PMM_FAULT_STEERING_ANGLE_RATE" ;
VAL_ 905 DAS_pmmUltrasonicsFaultReason 3 "PMM_ULTRASONICS_BLOCKED_BOTH" 1 "PMM_ULTRASONICS_BLOCKED_FRONT" 2 "PMM_ULTRASONICS_BLOCKED_REAR" 4 "PMM_ULTRASONICS_INVALID_MIA" 0 "PMM_ULTRASONICS_NO_FAULT" ;
VAL_ 905 DAS_ppOffsetDesiredRamp 128 "PP_NO_OFFSET" ;
VAL_ 905 DAS_radarTelemetry 0 "RADAR_TELEMETRY_IDLE" 1 "RADAR_TELEMETRY_NORMAL" 2 "RADAR_TELEMETRY_URGENT" ;
VAL_ 905 DAS_robState 2 "ROB_STATE_ACTIVE" 0 "ROB_STATE_INHIBITED" 3 "ROB_STATE_MAPLESS" 1 "ROB_STATE_MEASURE" ;
VAL_ 921 DAS_autoLaneChangeState 19 "ALC_ABORT_BLINKER_TURNED_OFF" 18 "ALC_ABORT_LC_HEALTH_BAD" 30 "ALC_ABORT_MISSION_PLAN_INVALID" 20 "ALC_ABORT_OTHER_REASON" 17 "ALC_ABORT_POOR_VIEW_RANGE" 15 "ALC_ABORT_SIDE_OBSTACLE_PRESENT_L" 16 "ALC_ABORT_SIDE_OBSTACLE_PRESENT_R" 29 "ALC_ABORT_TIMEOUT" 8 "ALC_AVAILABLE_BOTH" 6 "ALC_AVAILABLE_ONLY_L" 7 "ALC_AVAILABLE_ONLY_R" 26 "ALC_BLOCKED_LANE_TYPE_L" 27 "ALC_BLOCKED_LANE_TYPE_R" 23 "ALC_BLOCKED_VEH_TTC_AND_USS_L" 25 "ALC_BLOCKED_VEH_TTC_AND_USS_R" 22 "ALC_BLOCKED_VEH_TTC_L" 24 "ALC_BLOCKED_VEH_TTC_R" 9 "ALC_IN_PROGRESS_L" 10 "ALC_IN_PROGRESS_R" 31 "ALC_SNA" 0 "ALC_UNAVAILABLE_DISABLED" 4 "ALC_UNAVAILABLE_EXITING_HIGHWAY" 1 "ALC_UNAVAILABLE_NO_LANES" 21 "ALC_UNAVAILABLE_SOLID_LANE_LINE" 2 "ALC_UNAVAILABLE_SONICS_INVALID" 3 "ALC_UNAVAILABLE_TP_FOLLOW" 5 "ALC_UNAVAILABLE_VEHICLE_SPEED" 13 "ALC_WAITING_FOR_FWD_OBST_TO_PASS_L" 14 "ALC_WAITING_FOR_FWD_OBST_TO_PASS_R" 11 "ALC_WAITING_FOR_SIDE_OBST_TO_PASS_L" 12 "ALC_WAITING_FOR_SIDE_OBST_TO_PASS_R" 28 "ALC_WAITING_HANDS_ON" ;
VAL_ 921 DAS_autoparkReady 1 "AUTOPARK_READY" 0 "AUTOPARK_UNAVAILABLE" ;
VAL_ 921 DAS_autopilotHandsOnState 0 "LC_HANDS_ON_NOT_REQD" 4 "LC_HANDS_ON_REQD_CHIME_1" 5 "LC_HANDS_ON_REQD_CHIME_2" 1 "LC_HANDS_ON_REQD_DETECTED" 9 "LC_HANDS_ON_REQD_ESCALATED_CHIME_1" 10 "LC_HANDS_ON_REQD_ESCALATED_CHIME_2" 2 "LC_HANDS_ON_REQD_NOT_DETECTED" 6 "LC_HANDS_ON_REQD_SLOWING" 7 "LC_HANDS_ON_REQD_STRUCK_OUT" 3 "LC_HANDS_ON_REQD_VISUAL" 15 "LC_HANDS_ON_SNA" 8 "LC_HANDS_ON_SUSPENDED" ;
VAL_ 921 DAS_autopilotState 9 "ABORTED" 8 "ABORTING" 5 "ACTIVE_NAV" 3 "ACTIVE_NOMINAL" 4 "ACTIVE_RESTRICTED" 2 "AVAILABLE" 0 "DISABLED" 14 "FAULT" 15 "SNA" 1 "UNAVAILABLE" ;
VAL_ 921 DAS_blindSpotRearLeft 0 "NO_WARNING" 3 "SNA" 1 "WARNING_LEVEL_1" 2 "WARNING_LEVEL_2" ;
VAL_ 921 DAS_blindSpotRearRight 0 "NO_WARNING" 3 "SNA" 1 "WARNING_LEVEL_1" 2 "WARNING_LEVEL_2" ;
VAL_ 921 DAS_fleetSpeedState 2 "FLEETSPEED_ACTIVE" 1 "FLEETSPEED_AVAILABLE" 3 "FLEETSPEED_HOLD" 0 "FLEETSPEED_UNAVAILABLE" ;
VAL_ 921 DAS_forwardCollisionWarning 1 "FORWARD_COLLISION_WARNING" 0 "NONE" 3 "SNA" ;
VAL_ 921 DAS_fusedSpeedLimit 31 "NONE" 0 "UNKNOWN_SNA" ;
VAL_ 921 DAS_heaterState 0 "HEATER_OFF_SNA" 1 "HEATER_ON" ;
VAL_ 921 DAS_laneDepartureWarning 1 "LEFT_WARNING" 3 "LEFT_WARNING_SEVERE" 0 "NONE" 2 "RIGHT_WARNING" 4 "RIGHT_WARNING_SEVERE" 5 "SNA" ;
VAL_ 921 DAS_lssState 6 "LSS_STATE_ABORT" 5 "LSS_STATE_BLINDSPOT" 3 "LSS_STATE_ELK" 0 "LSS_STATE_FAULT" 1 "LSS_STATE_LDW" 2 "LSS_STATE_LKA" 4 "LSS_STATE_MONITOR" 7 "LSS_STATE_OFF" ;
VAL_ 921 DAS_sideCollisionAvoid 1 "AVOID_LEFT" 2 "AVOID_RIGHT" 0 "NONE" 3 "SNA" ;
VAL_ 921 DAS_sideCollisionInhibit 1 "INHIBIT" 0 "NO_INHIBIT" ;
VAL_ 921 DAS_sideCollisionWarning 0 "NONE" 1 "WARN_LEFT" 3 "WARN_LEFT_RIGHT" 2 "WARN_RIGHT" ;
VAL_ 921 DAS_suppressSpeedWarning 0 "Do_Not_Suppress" 1 "Suppress_Speed_Warning" ;
VAL_ 921 DAS_visionOnlySpeedLimit 31 "NONE" 0 "UNKNOWN_SNA" ;
VAL_ 925 IBST_driverBrakeApply 1 "BRAKES_NOT_APPLIED" 2 "DRIVER_APPLYING_BRAKES" 3 "FAULT" 0 "NOT_INIT_OR_OFF" ;
VAL_ 925 IBST_iBoosterStatus 4 "IBOOSTER_ACTIVE_GOOD_CHECK" 6 "IBOOSTER_ACTUATION" 3 "IBOOSTER_DIAGNOSTIC" 2 "IBOOSTER_FAILURE" 1 "IBOOSTER_INIT" 0 "IBOOSTER_OFF" 5 "IBOOSTER_READY" ;
VAL_ 925 IBST_internalState 4 "DIAGNOSTIC" 3 "EXTERNAL_BRAKE_REQUEST" 2 "LOCAL_BRAKE_REQUEST" 0 "NO_MODE_ACTIVE" 6 "POST_DRIVE_CHECK" 1 "PRE_DRIVE_CHECK" 5 "TRANSITION_TO_IDLE" ;
VAL_ 929 VCFRONT_12vStatusForDrive 2 "EXIT_DRIVE_REQUESTED_12V" 0 "NOT_READY_FOR_DRIVE_12V" 1 "READY_FOR_DRIVE_12V" ;
VAL_ 929 VCFRONT_2RowCenterUnbuckled 0 "CHIME_NONE" 1 "CHIME_OCCUPIED_AND_UNBUCKLED" 2 "CHIME_SNA" ;
VAL_ 929 VCFRONT_2RowLeftUnbuckled 0 "CHIME_NONE" 1 "CHIME_OCCUPIED_AND_UNBUCKLED" 2 "CHIME_SNA" ;
VAL_ 929 VCFRONT_2RowRightUnbuckled 0 "CHIME_NONE" 1 "CHIME_OCCUPIED_AND_UNBUCKLED" 2 "CHIME_SNA" ;
VAL_ 929 VCFRONT_APGlassHeaterState 4 "HEATER_STATE_FAULT" 2 "HEATER_STATE_OFF" 3 "HEATER_STATE_OFF_UNAVAILABLE" 1 "HEATER_STATE_ON" 0 "HEATER_STATE_SNA" ;
VAL_ 929 VCFRONT_diPowerOnState 0 "DI_POWERED_OFF" 3 "DI_POWERED_ON_FOR_DRIVE" 2 "DI_POWERED_ON_FOR_STATIONARY_HEAT" 1 "DI_POWERED_ON_FOR_SUMMON" 4 "DI_POWER_GOING_DOWN" ;
VAL_ 929 VCFRONT_driverBuckleStatus 1 "BUCKLED" 0 "UNBUCKLED" ;
VAL_ 929 VCFRONT_driverDoorStatus 1 "DOOR_CLOSED" 0 "DOOR_OPEN" ;
VAL_ 929 VCFRONT_driverUnbuckled 0 "CHIME_NONE" 1 "CHIME_OCCUPIED_AND_UNBUCKLED" 2 "CHIME_SNA" ;
VAL_ 929 VCFRONT_passengerUnbuckled 0 "CHIME_NONE" 1 "CHIME_OCCUPIED_AND_UNBUCKLED" 2 "CHIME_SNA" ;
VAL_ 929 VCFRONT_pcsEFuseVoltage 1023 "SNA" ;
VAL_ 929 VCFRONT_thermalSystemType 1 "HEAT_PUMP_THERMAL_SYSTEM" 0 "LEGACY_THERMAL_SYSTEM" ;
VAL_ 985 UI_conditionalSpeedLimit 31 "SNA" ;
VAL_ 985 UI_mapSpeedLimitUnits 1 "KPH" 0 "MPH" ;
VAL_ 985 UI_userSpeedOffsetUnits 1 "KPH" 0 "MPH" ;
VAL_ 994 VCLEFT_FLMapLightStatus 2 "LIGHT_FAULT" 0 "LIGHT_OFF" 1 "LIGHT_ON" 3 "LIGHT_SNA" ;
VAL_ 994 VCLEFT_FRMapLightStatus 2 "LIGHT_FAULT" 0 "LIGHT_OFF" 1 "LIGHT_ON" 3 "LIGHT_SNA" ;
VAL_ 994 VCLEFT_RLMapLightStatus 2 "LIGHT_FAULT" 0 "LIGHT_OFF" 1 "LIGHT_ON" 3 "LIGHT_SNA" ;
VAL_ 994 VCLEFT_RRMapLightStatus 2 "LIGHT_FAULT" 0 "LIGHT_OFF" 1 "LIGHT_ON" 3 "LIGHT_SNA" ;
VAL_ 994 VCLEFT_brakeLightStatus 2 "LIGHT_FAULT" 0 "LIGHT_OFF" 1 "LIGHT_ON" 3 "LIGHT_SNA" ;
VAL_ 994 VCLEFT_brakeTrailerLightStatus 2 "LIGHT_FAULT" 0 "LIGHT_OFF" 1 "LIGHT_ON" 3 "LIGHT_SNA" ;
VAL_ 994 VCLEFT_dynamicBrakeLightStatus 2 "DYNAMIC_BRAKE_LIGHT_ACTIVE_HIGH" 1 "DYNAMIC_BRAKE_LIGHT_ACTIVE_LOW" 0 "DYNAMIC_BRAKE_LIGHT_OFF" ;
VAL_ 994 VCLEFT_fogTrailerLightStatus 2 "LIGHT_FAULT" 0 "LIGHT_OFF" 1 "LIGHT_ON" 3 "LIGHT_SNA" ;
VAL_ 994 VCLEFT_frontRideHeight 128 "SNA" ;
VAL_ 994 VCLEFT_leftTurnTrailerLightStatu 2 "LIGHT_FAULT" 0 "LIGHT_OFF" 1 "LIGHT_ON" 3 "LIGHT_SNA" ;
VAL_ 994 VCLEFT_rearRideHeight 128 "SNA" ;
VAL_ 994 VCLEFT_reverseTrailerLightStatus 2 "LIGHT_FAULT" 0 "LIGHT_OFF" 1 "LIGHT_ON" 3 "LIGHT_SNA" ;
VAL_ 994 VCLEFT_rightTrnTrailerLightStatu 2 "LIGHT_FAULT" 0 "LIGHT_OFF" 1 "LIGHT_ON" 3 "LIGHT_SNA" ;
VAL_ 994 VCLEFT_tailLightStatus 2 "LIGHT_FAULT" 0 "LIGHT_OFF" 1 "LIGHT_ON" 3 "LIGHT_SNA" ;
VAL_ 994 VCLEFT_tailTrailerLightStatus 2 "LIGHT_FAULT" 0 "LIGHT_OFF" 1 "LIGHT_ON" 3 "LIGHT_SNA" ;
VAL_ 994 VCLEFT_trailerDetected 2 "TRAILER_LIGHT_DETECTION_DETECTED" 1 "TRAILER_LIGHT_DETECTION_FAULT" 3 "TRAILER_LIGHT_DETECTION_NOT_DETECTED" 0 "TRAILER_LIGHT_DETECTION_SNA" ;
VAL_ 994 VCLEFT_turnSignalStatus 2 "LIGHT_FAULT" 0 "LIGHT_OFF" 1 "LIGHT_ON" 3 "LIGHT_SNA" ;
VAL_ 1001 DAS_hazardLightRequest 0 "DAS_REQUEST_HAZARDS_OFF" 1 "DAS_REQUEST_HAZARDS_ON" 3 "DAS_REQUEST_HAZARDS_SNA" 2 "DAS_REQUEST_HAZARDS_UNUSED" ;
VAL_ 1001 DAS_headlightRequest 3 "DAS_HEADLIGHT_REQUEST_INVALID" 0 "DAS_HEADLIGHT_REQUEST_OFF" 1 "DAS_HEADLIGHT_REQUEST_ON" ;
VAL_ 1001 DAS_heaterRequest 1 "DAS_HEATER_OFF" 2 "DAS_HEATER_ON" 0 "DAS_HEATER_SNA" ;
VAL_ 1001 DAS_highLowBeamDecision 1 "DAS_HIGH_BEAM_OFF" 2 "DAS_HIGH_BEAM_ON" 3 "DAS_HIGH_BEAM_SNA" 0 "DAS_HIGH_BEAM_UNDECIDED" ;
VAL_ 1001 DAS_highLowBeamOffReason 3 "HIGH_BEAM_OFF_REASON_AMBIENT_LIGHT" 4 "HIGH_BEAM_OFF_REASON_HEAD_LIGHT" 2 "HIGH_BEAM_OFF_REASON_MOVING_RADAR_TARGET" 1 "HIGH_BEAM_OFF_REASON_MOVING_VISION_TARGET" 5 "HIGH_BEAM_OFF_REASON_SNA" 0 "HIGH_BEAM_ON" ;
VAL_ 1001 DAS_turnIndicatorRequest 3 "DAS_TURN_INDICATOR_CANCEL" 4 "DAS_TURN_INDICATOR_DEFER" 1 "DAS_TURN_INDICATOR_LEFT" 0 "DAS_TURN_INDICATOR_NONE" 2 "DAS_TURN_INDICATOR_RIGHT" ;
VAL_ 1001 DAS_turnIndicatorRequestReason 8 "DAS_ACTIVE_COMMANDED_LANE_CHANGE" 3 "DAS_ACTIVE_FORK" 9 "DAS_ACTIVE_INTERSECTION" 6 "DAS_ACTIVE_MERGE" 1 "DAS_ACTIVE_NAV_LANE_CHANGE" 2 "DAS_ACTIVE_SPEED_LANE_CHANGE" 11 "DAS_ACTIVE_SUMMMON" 5 "DAS_CANCEL_FORK" 10 "DAS_CANCEL_INTERSECTION" 4 "DAS_CANCEL_LANE_CHANGE" 7 "DAS_CANCEL_MERGE" 12 "DAS_CANCEL_SUMMMON" 0 "DAS_NONE" ;
VAL_ 1001 DAS_wiperSpeed 1 "DAS_WIPER_SPEED_1" 10 "DAS_WIPER_SPEED_10" 11 "DAS_WIPER_SPEED_11" 12 "DAS_WIPER_SPEED_12" 13 "DAS_WIPER_SPEED_13" 14 "DAS_WIPER_SPEED_14" 2 "DAS_WIPER_SPEED_2" 3 "DAS_WIPER_SPEED_3" 4 "DAS_WIPER_SPEED_4" 5 "DAS_WIPER_SPEED_5" 6 "DAS_WIPER_SPEED_6" 7 "DAS_WIPER_SPEED_7" 8 "DAS_WIPER_SPEED_8" 9 "DAS_WIPER_SPEED_9" 15 "DAS_WIPER_SPEED_INVALID" 0 "DAS_WIPER_SPEED_OFF" ;
VAL_ 1001 DAS_mirrorFoldRequest 0 "NONE" 1 "FOLD" 2 "UNFOLD" 3 "SNA" ;
VAL_ 1011 UI_odometer 16777215 "SNA" ;
VAL_ 1013 VCFRONT_DRLLeftStatus 2 "LIGHT_FAULT" 0 "LIGHT_OFF" 1 "LIGHT_ON" 3 "LIGHT_SNA" ;
VAL_ 1013 VCFRONT_DRLRightStatus 2 "LIGHT_FAULT" 0 "LIGHT_OFF" 1 "LIGHT_ON" 3 "LIGHT_SNA" ;
VAL_ 1013 VCFRONT_ambientLightingBrightnes 255 "SNA" ;
VAL_ 1013 VCFRONT_fogLeftStatus 2 "LIGHT_FAULT" 0 "LIGHT_OFF" 1 "LIGHT_ON" 3 "LIGHT_SNA" ;
VAL_ 1013 VCFRONT_fogRightStatus 2 "LIGHT_FAULT" 0 "LIGHT_OFF" 1 "LIGHT_ON" 3 "LIGHT_SNA" ;
VAL_ 1013 VCFRONT_hazardLightRequest 1 "HAZARD_REQUEST_BUTTON" 6 "HAZARD_REQUEST_CAR_ALARM" 5 "HAZARD_REQUEST_CRASH" 7 "HAZARD_REQUEST_DAS" 2 "HAZARD_REQUEST_LOCK" 4 "HAZARD_REQUEST_MISLOCK" 0 "HAZARD_REQUEST_NONE" 8 "HAZARD_REQUEST_UDS" 3 "HAZARD_REQUEST_UNLOCK" ;
VAL_ 1013 VCFRONT_highBeamLeftStatus 2 "LIGHT_FAULT" 0 "LIGHT_OFF" 1 "LIGHT_ON" 3 "LIGHT_SNA" ;
VAL_ 1013 VCFRONT_highBeamRightStatus 2 "LIGHT_FAULT" 0 "LIGHT_OFF" 1 "LIGHT_ON" 3 "LIGHT_SNA" ;
VAL_ 1013 VCFRONT_indicatorLeftRequest 2 "TURN_SIGNAL_ACTIVE_HIGH" 1 "TURN_SIGNAL_ACTIVE_LOW" 0 "TURN_SIGNAL_OFF" ;
VAL_ 1013 VCFRONT_indicatorRightRequest 2 "TURN_SIGNAL_ACTIVE_HIGH" 1 "TURN_SIGNAL_ACTIVE_LOW" 0 "TURN_SIGNAL_OFF" ;
VAL_ 1013 VCFRONT_lowBeamLeftStatus 2 "LIGHT_FAULT" 0 "LIGHT_OFF" 1 "LIGHT_ON" 3 "LIGHT_SNA" ;
VAL_ 1013 VCFRONT_lowBeamRightStatus 2 "LIGHT_FAULT" 0 "LIGHT_OFF" 1 "LIGHT_ON" 3 "LIGHT_SNA" ;
VAL_ 1013 VCFRONT_parkLeftStatus 2 "LIGHT_FAULT" 0 "LIGHT_OFF" 1 "LIGHT_ON" 3 "LIGHT_SNA" ;
VAL_ 1013 VCFRONT_parkRightStatus 2 "LIGHT_FAULT" 0 "LIGHT_OFF" 1 "LIGHT_ON" 3 "LIGHT_SNA" ;
VAL_ 1013 VCFRONT_sideMarkersStatus 2 "LIGHT_FAULT" 0 "LIGHT_OFF" 1 "LIGHT_ON" 3 "LIGHT_SNA" ;
VAL_ 1013 VCFRONT_sideRepeaterLeftStatus 2 "LIGHT_FAULT" 0 "LIGHT_OFF" 1 "LIGHT_ON" 3 "LIGHT_SNA" ;
VAL_ 1013 VCFRONT_sideRepeaterRightStatus 2 "LIGHT_FAULT" 0 "LIGHT_OFF" 1 "LIGHT_ON" 3 "LIGHT_SNA" ;
VAL_ 1013 VCFRONT_simLatchingStalk 0 "SIMULATED_LATCHING_STALK_IDLE" 1 "SIMULATED_LATCHING_STALK_LEFT" 2 "SIMULATED_LATCHING_STALK_RIGHT" 3 "SIMULATED_LATCHING_STALK_SNA" ;
VAL_ 1013 VCFRONT_switchLightingBrightness 255 "SNA" ;
VAL_ 1013 VCFRONT_turnSignalLeftStatus 2 "LIGHT_FAULT" 0 "LIGHT_OFF" 1 "LIGHT_ON" 3 "LIGHT_SNA" ;
VAL_ 1013 VCFRONT_turnSignalRightStatus 2 "LIGHT_FAULT" 0 "LIGHT_OFF" 1 "LIGHT_ON" 3 "LIGHT_SNA" ;
VAL_ 1016 UI_accFollowDistanceSetting 0 "DISTANCE_SETTING_1" 1 "DISTANCE_SETTING_2" 2 "DISTANCE_SETTING_3" 3 "DISTANCE_SETTING_4" 4 "DISTANCE_SETTING_5" 5 "DISTANCE_SETTING_6" 6 "DISTANCE_SETTING_7" 7 "DISTANCE_SETTING_SNA" ;
VAL_ 1016 UI_autopilotControlRequest 0 "LEGACY_LAT_CTRL" 1 "NEXT_GEN_CTRL" ;
VAL_ 1016 UI_curvSpeedAdaptDisable 1 "CSA_OFF" 0 "CSA_ON" ;
VAL_ 1016 UI_curvatureDatabaseOnly 0 "OFF" 1 "ON" ;
VAL_ 1016 UI_driveOnMapsEnable 0 "DOM_OFF" 1 "DOM_ON" ;
VAL_ 1016 UI_drivingSide 0 "DRIVING_SIDE_LEFT" 1 "DRIVING_SIDE_RIGHT" 2 "DRIVING_SIDE_UNKNOWN" ;
VAL_ 1016 UI_exceptionListEnable 0 "EXCEPTION_LIST_OFF" 1 "EXCEPTION_LIST_ON" ;
VAL_ 1016 UI_followNavRouteEnable 0 "NAV_ROUTE_OFF" 1 "NAV_ROUTE_ON" ;
VAL_ 1016 UI_fuseHPPDisable 1 "FUSE_HPP_OFF" 0 "FUSE_HPP_ON" ;
VAL_ 1016 UI_fuseLanesDisable 1 "FUSE_LANES_OFF" 0 "FUSE_LANES_ON" ;
VAL_ 1016 UI_fuseVehiclesDisable 1 "FUSE_VEH_OFF" 0 "FUSE_VEH_ON" ;
VAL_ 1016 UI_handsOnRequirementDisable 1 "HANDS_ON_REQ_OFF" 0 "HANDS_ON_REQ_ON" ;
VAL_ 1016 UI_lssElkEnabled 0 "ELK_OFF" 1 "ELK_ON" ;
VAL_ 1016 UI_lssLdwEnabled 0 "LDW_OFF" 1 "LDW_ON" ;
VAL_ 1016 UI_lssLkaEnabled 0 "LKA_OFF" 1 "LKA_ON" ;
VAL_ 1016 UI_roadCheckDisable 1 "RC_OFF" 0 "RC_ON" ;
VAL_ 1016 UI_selfParkRequest 3 "ABORT" 9 "AUTO_SUMMON_CANCEL" 7 "AUTO_SUMMON_FORWARD" 10 "AUTO_SUMMON_PRIMED" 8 "AUTO_SUMMON_REVERSE" 0 "NONE" 5 "PAUSE" 4 "PRIME" 6 "RESUME" 1 "SELF_PARK_FORWARD" 2 "SELF_PARK_REVERSE" 11 "SMART_SUMMON" 12 "SMART_SUMMON_NO_OP" 15 "SNA" ;
VAL_ 1016 UI_smartSummonType 1 "FIND_ME" 0 "PIN_DROP" 2 "SMART_AUTOPARK" ;
VAL_ 1016 UI_source3D 2 "XYZ_PREDICTION" 0 "Z_FROM_MAP" 1 "Z_FROM_PATH_PREDICTION" ;
VAL_ 1016 UI_summonEntryType 3 "SNA" 0 "STRAIGHT" 2 "TURN_LEFT" 1 "TURN_RIGHT" ;
VAL_ 1016 UI_summonExitType 3 "SNA" 0 "STRAIGHT" 2 "TURN_LEFT" 1 "TURN_RIGHT" ;
VAL_ 1016 UI_summonReverseDist 63 "SNA" ;
VAL_ 1016 UI_ulcBlindSpotConfig 1 "AGGRESSIVE" 2 "MAD_MAX" 0 "STANDARD" ;
VAL_ 1016 UI_ulcSpeedConfig 2 "SPEED_BASED_ULC_AVERAGE" 0 "SPEED_BASED_ULC_DISABLED" 3 "SPEED_BASED_ULC_MAD_MAX" 1 "SPEED_BASED_ULC_MILD" ;
VAL_ 1016 UI_visionSpeedType 0 "VISION_SPEED_DISABLED" 1 "VISION_SPEED_ONE_SECOND" 3 "VISION_SPEED_OPTIMIZED" 2 "VISION_SPEED_TWO_SECOND" ;
VAL_ 1021 UI_autopilotControlIndex 0 "AUTOPILOT_CONTROL_0" 1 "AUTOPILOT_CONTROL_1" 2 "AUTOPILOT_CONTROL_2" 3 "AUTOPILOT_CONTROL_3" 4 "AUTOPILOT_CONTROL_4" 5 "AUTOPILOT_CONTROL_5" 6 "AUTOPILOT_CONTROL_6" 7 "AUTOPILOT_CONTROL_7" ;
VAL_ 1021 UI_apmv3Branch 5 "DEMO" 2 "DEV" 4 "EAP" 0 "LIVE" 1 "STAGE" 3 "STAGE2" ;
VAL_ 1021 UI_blindspotDistance 1 "BLINDSPOT_DISTANCE_0P5_M" 2 "BLINDSPOT_DISTANCE_1_M" 3 "BLINDSPOT_DISTANCE_2_M" 4 "BLINDSPOT_DISTANCE_4_M" 0 "BLINDSPOT_DISTANCE_DEFAULT" 5 "BLINDSPOT_DISTANCE_OFF" ;
VAL_ 1021 UI_blindspotMinSpeed 2 "BLINDSPOT_MIN_SPEED_10_KPH" 3 "BLINDSPOT_MIN_SPEED_15_KPH" 4 "BLINDSPOT_MIN_SPEED_20_KPH" 5 "BLINDSPOT_MIN_SPEED_25_KPH" 6 "BLINDSPOT_MIN_SPEED_30_KPH" 7 "BLINDSPOT_MIN_SPEED_35_KPH" 8 "BLINDSPOT_MIN_SPEED_40_KPH" 9 "BLINDSPOT_MIN_SPEED_45_KPH" 1 "BLINDSPOT_MIN_SPEED_5_KPH" 0 "BLINDSPOT_MIN_SPEED_DEFAULT" 10 "BLINDSPOT_MIN_SPEED_OFF" ;
VAL_ 1021 UI_blindspotTTC 1 "BLINDSPOT_TTC_0P5_S" 2 "BLINDSPOT_TTC_1_S" 3 "BLINDSPOT_TTC_2_S" 5 "BLINDSPOT_TTC_3_S" 4 "BLINDSPOT_TTC_4_S" 6 "BLINDSPOT_TTC_5_S" 0 "BLINDSPOT_TTC_DEFAULT" 7 "BLINDSPOT_TTC_OFF" ;
VAL_ 1021 UI_donAlcProgGoreAbortThres 1 "DON_ALC_PROGRESS_GORE_ABORT_THRESHOLD_0P00" 2 "DON_ALC_PROGRESS_GORE_ABORT_THRESHOLD_0P05" 3 "DON_ALC_PROGRESS_GORE_ABORT_THRESHOLD_0P10" 4 "DON_ALC_PROGRESS_GORE_ABORT_THRESHOLD_0P15" 5 "DON_ALC_PROGRESS_GORE_ABORT_THRESHOLD_0P20" 6 "DON_ALC_PROGRESS_GORE_ABORT_THRESHOLD_0P25" 7 "DON_ALC_PROGRESS_GORE_ABORT_THRESHOLD_0P30" 8 "DON_ALC_PROGRESS_GORE_ABORT_THRESHOLD_0P35" 9 "DON_ALC_PROGRESS_GORE_ABORT_THRESHOLD_0P40" 0 "DON_ALC_PROGRESS_GORE_ABORT_THRESHOLD_DEFAULT" ;
VAL_ 1021 UI_donDisableAutoWiperDuration 5 "DON_DISABLE_AUTO_WIPER_DURATION_120_S" 2 "DON_DISABLE_AUTO_WIPER_DURATION_15_S" 3 "DON_DISABLE_AUTO_WIPER_DURATION_30_S" 1 "DON_DISABLE_AUTO_WIPER_DURATION_5_S" 4 "DON_DISABLE_AUTO_WIPER_DURATION_60_S" 0 "DON_DISABLE_AUTO_WIPER_DURATION_DEFAULT" 6 "DON_DISABLE_AUTO_WIPER_DURATION_OFF" ;
VAL_ 1021 UI_donDisableCutin 0 "DON_DISABLE_CUTIN_OFF" 1 "DON_DISABLE_CUTIN_ON" ;
VAL_ 1021 UI_donDisableOnAutoWiperSpeed 1 "DAS_WIPER_SPEED_1" 10 "DAS_WIPER_SPEED_10" 11 "DAS_WIPER_SPEED_11" 12 "DAS_WIPER_SPEED_12" 13 "DAS_WIPER_SPEED_13" 14 "DAS_WIPER_SPEED_14" 2 "DAS_WIPER_SPEED_2" 3 "DAS_WIPER_SPEED_3" 4 "DAS_WIPER_SPEED_4" 5 "DAS_WIPER_SPEED_5" 6 "DAS_WIPER_SPEED_6" 7 "DAS_WIPER_SPEED_7" 8 "DAS_WIPER_SPEED_8" 9 "DAS_WIPER_SPEED_9" 15 "DAS_WIPER_SPEED_INVALID" 0 "DAS_WIPER_SPEED_OFF" ;
VAL_ 1021 UI_donMinGoreWidthForAbortMap 2 "DON_MIN_GORE_WIDTH_FOR_ABORT_0P5_M" 1 "DON_MIN_GORE_WIDTH_FOR_ABORT_0_M" 4 "DON_MIN_GORE_WIDTH_FOR_ABORT_1P5_M" 3 "DON_MIN_GORE_WIDTH_FOR_ABORT_1_M" 6 "DON_MIN_GORE_WIDTH_FOR_ABORT_2P5_M" 5 "DON_MIN_GORE_WIDTH_FOR_ABORT_2_M" 8 "DON_MIN_GORE_WIDTH_FOR_ABORT_3P5_M" 7 "DON_MIN_GORE_WIDTH_FOR_ABORT_3_M" 10 "DON_MIN_GORE_WIDTH_FOR_ABORT_4P5_M" 9 "DON_MIN_GORE_WIDTH_FOR_ABORT_4_M" 11 "DON_MIN_GORE_WIDTH_FOR_ABORT_5_M" 0 "DON_MIN_GORE_WIDTH_FOR_ABORT_DEFAULT" ;
VAL_ 1021 UI_donMinGoreWidthForAbortNotMap 2 "DON_MIN_GORE_WIDTH_FOR_ABORT_0P5_M" 1 "DON_MIN_GORE_WIDTH_FOR_ABORT_0_M" 4 "DON_MIN_GORE_WIDTH_FOR_ABORT_1P5_M" 3 "DON_MIN_GORE_WIDTH_FOR_ABORT_1_M" 6 "DON_MIN_GORE_WIDTH_FOR_ABORT_2P5_M" 5 "DON_MIN_GORE_WIDTH_FOR_ABORT_2_M" 8 "DON_MIN_GORE_WIDTH_FOR_ABORT_3P5_M" 7 "DON_MIN_GORE_WIDTH_FOR_ABORT_3_M" 10 "DON_MIN_GORE_WIDTH_FOR_ABORT_4P5_M" 9 "DON_MIN_GORE_WIDTH_FOR_ABORT_4_M" 11 "DON_MIN_GORE_WIDTH_FOR_ABORT_5_M" 0 "DON_MIN_GORE_WIDTH_FOR_ABORT_DEFAULT" ;
VAL_ 1021 UI_donStopEndOfRampBuffer 1 "DON_STOP_END_OF_RAMP_BUFFER_15_M" 2 "DON_STOP_END_OF_RAMP_BUFFER_30_M" 3 "DON_STOP_END_OF_RAMP_BUFFER_45_M" 0 "DON_STOP_END_OF_RAMP_BUFFER_DEFAULT" 4 "DON_STOP_END_OF_RAMP_BUFFER_OFF" ;
VAL_ 1021 UI_homelinkNearby 1 "HOMELINK_NEARBY" 0 "HOMELINK_NOT_NEARBY" ;
VAL_ 1021 UI_hovEnabled 0 "HOV_OFF" 1 "HOV_ON" ;
VAL_ 615 DI_massConfidence 1 "MASS_CONFIDED" 0 "MASS_NOT_CONFIDED" ;
VAL_ 615 DI_relativeTireTreadDepth 32 "SNA" ;
VAL_ 615 DI_tireFitment 3 "FITMENT_SNA" 0 "FITMENT_SQUARE" 1 "FITMENT_STAGGERED" ;
VAL_ 615 DI_trailerDetected 1 "TRAILER_DETECTED" 0 "TRAILER_NOT_DETECTED" ;
VAL_ 642 VCLEFT_blowerIndex 0 "HVAC_FEEDBACK_SIGNALS" 1 "HVAC_VARS" ;
VAL_ 642 VCLEFT_hvacBlowerCBCCtrlState 4 "COUNT" 0 "ERROR" 1 "IDLE" 2 "OFFLINE" 3 "ONLINE" ;
VAL_ 642 VCLEFT_hvacBlowerCBCEstState 14 "COUNT" 0 "ERROR" 1 "IDLE" 5 "IDRATED" 10 "INDUCTANCE_EST" 9 "LOCKROTOR" 12 "MOTOR_IDENTIFIED" 13 "ONLINE" 8 "RAMPDOWN" 4 "RAMPUP" 7 "RATEDFLUX" 6 "RATEDFLUX_OL" 11 "ROTOR_RESISTANCE" 2 "ROVERL" 3 "RS" ;
VAL_ 642 VCLEFT_hvacBlowerFETTemp 127 "SNA" ;
VAL_ 642 VCLEFT_hvacBlowerIPhase0 255 "SNA" ;
VAL_ 642 VCLEFT_hvacBlowerIPhase1 255 "SNA" ;
VAL_ 642 VCLEFT_hvacBlowerIPhase2 255 "SNA" ;
VAL_ 642 VCLEFT_hvacBlowerITerm 127 "SNA" ;
VAL_ 642 VCLEFT_hvacBlowerOutputDuty 127 "SNA" ;
VAL_ 642 VCLEFT_hvacBlowerRPMTarget 1023 "SNA" ;
VAL_ 642 VCLEFT_hvacBlowerRs 255 "SNA" ;
VAL_ 642 VCLEFT_hvacBlowerTorque 1023 "SNA" ;
VAL_ 642 VCLEFT_hvacBlower_IO_CBC_Status 0 "IDLE" 1 "RX" ;
VAL_ 755 UI_hvacReqACDisable 0 "AUTO" 1 "OFF" 2 "ON" ;
VAL_ 755 UI_hvacReqAirDistributionMode 0 "AUTO" 4 "MANUAL_DEFROST" 5 "MANUAL_DEFROST_FLOOR" 6 "MANUAL_DEFROST_PANEL" 7 "MANUAL_DEFROST_PANEL_FLOOR" 1 "MANUAL_FLOOR" 2 "MANUAL_PANEL" 3 "MANUAL_PANEL_FLOOR" ;
VAL_ 755 UI_hvacReqBlowerSegment 1 "1" 10 "10" 2 "2" 3 "3" 4 "4" 5 "5" 6 "6" 7 "7" 8 "8" 9 "9" 11 "AUTO" 0 "OFF" ;
VAL_ 755 UI_hvacReqKeepClimateOn 2 "KEEP_CLIMATE_ON_REQ_DOG" 0 "KEEP_CLIMATE_ON_REQ_OFF" 1 "KEEP_CLIMATE_ON_REQ_ON" 3 "KEEP_CLIMATE_ON_REQ_PARTY" ;
VAL_ 755 UI_hvacReqManualDefogState 1 "DEFOG" 2 "DEFROST" 0 "NONE" ;
VAL_ 755 UI_hvacReqRecirc 0 "AUTO" 2 "FRESH" 1 "RECIRC" ;
VAL_ 755 UI_hvacReqSecondRowState 0 "AUTO" 4 "HIGH" 2 "LOW" 3 "MED" 1 "OFF" ;
VAL_ 755 UI_hvacReqTempSetpointLeft 26 "HI" 0 "LO" ;
VAL_ 755 UI_hvacReqTempSetpointRight 26 "HI" 0 "LO" ;
VAL_ 755 UI_hvacReqUserPowerState 0 "OFF" 1 "ON" 4 "OVERHEAT_PROTECT" 3 "OVERHEAT_PROTECT_FANONLY" 2 "PRECONDITION" ;
VAL_ 787 UI_trackCmpOverclock 0 "TRACK_MODE_CMP_OVERCLOCK_OFF" 1 "TRACK_MODE_CMP_OVERCLOCK_ON" ;
VAL_ 787 UI_trackModeRequest 0 "TRACK_MODE_REQUEST_IDLE" 2 "TRACK_MODE_REQUEST_OFF" 1 "TRACK_MODE_REQUEST_ON" ;
VAL_ 787 UI_trackPostCooling 0 "TRACK_MODE_POST_COOLING_OFF" 1 "TRACK_MODE_POST_COOLING_ON" ;
VAL_ 821 DIR_infoIndex 13 "DI_INFO_APP_CRC" 17 "DI_INFO_APP_GITHASH" 15 "DI_INFO_BOOTLOADER_CRC" 18 "DI_INFO_BOOTLOADER_GITHASH" 14 "DI_INFO_BOOTLOADER_SVN" 10 "DI_INFO_BUILD_HWID_COMPONENTID" 0 "DI_INFO_DEPRECATED_0" 1 "DI_INFO_DEPRECATED_1" 2 "DI_INFO_DEPRECATED_2" 3 "DI_INFO_DEPRECATED_3" 4 "DI_INFO_DEPRECATED_4" 5 "DI_INFO_DEPRECATED_5" 6 "DI_INFO_DEPRECATED_6" 7 "DI_INFO_DEPRECATED_7" 8 "DI_INFO_DEPRECATED_8" 9 "DI_INFO_DEPRECATED_9" 255 "DI_INFO_END" 11 "DI_INFO_PCBAID_ASSYID_USAGEID" 16 "DI_INFO_SUBCOMPONENT" 23 "DI_INFO_SUBCOMPONENT2" 31 "DI_INFO_SUBCOMPONENT_GITHASH" 20 "DI_INFO_UDS_PROTOCOL_BOOTCRC" 19 "DI_INFO_VERSION_DEPRECATED" ;
VAL_ 821 DIR_FPGA_version 254 "FPGA_VERSION_LOCAL_BUILD" 255 "FPGA_VERSION_SNA" ;
VAL_ 821 DIR_buildType 2 "INFO_LOCAL_BUILD" 4 "INFO_MFG_BUILD" 1 "INFO_PLATFORM_BUILD" 3 "INFO_TRACEABLE_CI_BUILD" 0 "INFO_UNKNOWN_BUILD" ;
VAL_ 821 DIR_hardwareId 252 "CONFIGURABLE_HWID_PLACEHOLDER" ;
VAL_ 821 DIR_oilPumpBuildType 2 "INFO_LOCAL_BUILD" 4 "INFO_MFG_BUILD" 1 "INFO_PLATFORM_BUILD" 3 "INFO_TRACEABLE_CI_BUILD" 0 "INFO_UNKNOWN_BUILD" ;
VAL_ 899 VCRIGHT_estimatedThsSolarLoad 1023 "SNA" ;
VAL_ 899 VCRIGHT_estimatedVehicleSituatio 1 "VEHICLE_SITUATION_INDOOR" 2 "VEHICLE_SITUATION_OUTDOOR" 0 "VEHICLE_SITUATION_UNKNOWN" ;
VAL_ 899 VCRIGHT_thsHumidity 255 "SNA" ;
VAL_ 899 VCRIGHT_thsSolarLoadInfrared 1023 "SNA" ;
VAL_ 899 VCRIGHT_thsSolarLoadVisible 1023 "SNA" ;
VAL_ 899 VCRIGHT_thsTemperature 128 "SNA" ;
VAL_ 947 UI_autopilotPowerStateRequest 0 "AUTOPILOT_NOMINAL" 1 "AUTOPILOT_SENTRY" 2 "AUTOPILOT_SUSPEND" ;
VAL_ 947 UI_lightSwitch 0 "LIGHT_SWITCH_AUTO" 3 "LIGHT_SWITCH_OFF" 1 "LIGHT_SWITCH_ON" 2 "LIGHT_SWITCH_PARKING" 4 "LIGHT_SWITCH_SNA" ;
VAL_ 947 UI_shorted12VCellTestMode 2 "SHORTED_CELL_TEST_MODE_ACTIVE" 0 "SHORTED_CELL_TEST_MODE_DISABLED" 1 "SHORTED_CELL_TEST_MODE_SHADOW" ;
VAL_ 947 UI_summonState 3 "ACTIVE" 1 "IDLE" 2 "PRE_PRIMED" 0 "SNA" ;
VAL_ 947 UI_windowRequest 3 "WINDOW_REQUEST_GOTO_CLOSED" 4 "WINDOW_REQUEST_GOTO_OPEN" 1 "WINDOW_REQUEST_GOTO_PERCENT" 2 "WINDOW_REQUEST_GOTO_VENT" 0 "WINDOW_REQUEST_IDLE" ;
VAL_ 963 VCRIGHT_frontBuckleSwitch 3 "SWITCH_FAULT" 1 "SWITCH_OFF" 2 "SWITCH_ON" 0 "SWITCH_SNA" ;
VAL_ 963 VCRIGHT_frontOccupancySwitch 3 "SWITCH_FAULT" 1 "SWITCH_OFF" 2 "SWITCH_ON" 0 "SWITCH_SNA" ;
VAL_ 963 VCRIGHT_frontSeatBackrestBack 3 "SWITCH_FAULT" 1 "SWITCH_OFF" 2 "SWITCH_ON" 0 "SWITCH_SNA" ;
VAL_ 963 VCRIGHT_frontSeatBackrestForward 3 "SWITCH_FAULT" 1 "SWITCH_OFF" 2 "SWITCH_ON" 0 "SWITCH_SNA" ;
VAL_ 963 VCRIGHT_frontSeatLiftDown 3 "SWITCH_FAULT" 1 "SWITCH_OFF" 2 "SWITCH_ON" 0 "SWITCH_SNA" ;
VAL_ 963 VCRIGHT_frontSeatLiftUp 3 "SWITCH_FAULT" 1 "SWITCH_OFF" 2 "SWITCH_ON" 0 "SWITCH_SNA" ;
VAL_ 963 VCRIGHT_frontSeatLumbarDown 3 "SWITCH_FAULT" 1 "SWITCH_OFF" 2 "SWITCH_ON" 0 "SWITCH_SNA" ;
VAL_ 963 VCRIGHT_frontSeatLumbarIn 3 "SWITCH_FAULT" 1 "SWITCH_OFF" 2 "SWITCH_ON" 0 "SWITCH_SNA" ;
VAL_ 963 VCRIGHT_frontSeatLumbarOut 3 "SWITCH_FAULT" 1 "SWITCH_OFF" 2 "SWITCH_ON" 0 "SWITCH_SNA" ;
VAL_ 963 VCRIGHT_frontSeatLumbarUp 3 "SWITCH_FAULT" 1 "SWITCH_OFF" 2 "SWITCH_ON" 0 "SWITCH_SNA" ;
VAL_ 963 VCRIGHT_frontSeatTiltDown 3 "SWITCH_FAULT" 1 "SWITCH_OFF" 2 "SWITCH_ON" 0 "SWITCH_SNA" ;
VAL_ 963 VCRIGHT_frontSeatTiltUp 3 "SWITCH_FAULT" 1 "SWITCH_OFF" 2 "SWITCH_ON" 0 "SWITCH_SNA" ;
VAL_ 963 VCRIGHT_frontSeatTrackBack 3 "SWITCH_FAULT" 1 "SWITCH_OFF" 2 "SWITCH_ON" 0 "SWITCH_SNA" ;
VAL_ 963 VCRIGHT_frontSeatTrackForward 3 "SWITCH_FAULT" 1 "SWITCH_OFF" 2 "SWITCH_ON" 0 "SWITCH_SNA" ;
VAL_ 963 VCRIGHT_rearCenterBuckleSwitch 3 "SWITCH_FAULT" 1 "SWITCH_OFF" 2 "SWITCH_ON" 0 "SWITCH_SNA" ;
VAL_ 963 VCRIGHT_rearRightBuckleSwitch 3 "SWITCH_FAULT" 1 "SWITCH_OFF" 2 "SWITCH_ON" 0 "SWITCH_SNA" ;
VAL_ 995 VCRIGHT_brakeLightStatus 2 "LIGHT_FAULT" 0 "LIGHT_OFF" 1 "LIGHT_ON" 3 "LIGHT_SNA" ;
VAL_ 995 VCRIGHT_interiorTrunkLightStatus 2 "LIGHT_FAULT" 0 "LIGHT_OFF" 1 "LIGHT_ON" 3 "LIGHT_SNA" ;
VAL_ 995 VCRIGHT_rearFogLightStatus 2 "LIGHT_FAULT" 0 "LIGHT_OFF" 1 "LIGHT_ON" 3 "LIGHT_SNA" ;
VAL_ 995 VCRIGHT_reverseLightStatus 2 "LIGHT_FAULT" 0 "LIGHT_OFF" 1 "LIGHT_ON" 3 "LIGHT_SNA" ;
VAL_ 995 VCRIGHT_tailLightStatus 2 "LIGHT_FAULT" 0 "LIGHT_OFF" 1 "LIGHT_ON" 3 "LIGHT_SNA" ;
VAL_ 995 VCRIGHT_turnSignalStatus 2 "LIGHT_FAULT" 0 "LIGHT_OFF" 1 "LIGHT_ON" 3 "LIGHT_SNA" ;
VAL_ 1622 DIF_infoIndex 13 "DI_INFO_APP_CRC" 17 "DI_INFO_APP_GITHASH" 15 "DI_INFO_BOOTLOADER_CRC" 18 "DI_INFO_BOOTLOADER_GITHASH" 14 "DI_INFO_BOOTLOADER_SVN" 10 "DI_INFO_BUILD_HWID_COMPONENTID" 0 "DI_INFO_DEPRECATED_0" 1 "DI_INFO_DEPRECATED_1" 2 "DI_INFO_DEPRECATED_2" 3 "DI_INFO_DEPRECATED_3" 4 "DI_INFO_DEPRECATED_4" 5 "DI_INFO_DEPRECATED_5" 6 "DI_INFO_DEPRECATED_6" 7 "DI_INFO_DEPRECATED_7" 8 "DI_INFO_DEPRECATED_8" 9 "DI_INFO_DEPRECATED_9" 255 "DI_INFO_END" 11 "DI_INFO_PCBAID_ASSYID_USAGEID" 16 "DI_INFO_SUBCOMPONENT" 23 "DI_INFO_SUBCOMPONENT2" 31 "DI_INFO_SUBCOMPONENT_GITHASH" 20 "DI_INFO_UDS_PROTOCOL_BOOTCRC" 19 "DI_INFO_VERSION_DEPRECATED" ;
VAL_ 1622 DIF_FPGA_version 254 "FPGA_VERSION_LOCAL_BUILD" 255 "FPGA_VERSION_SNA" ;
VAL_ 1622 DIF_buildType 2 "INFO_LOCAL_BUILD" 4 "INFO_MFG_BUILD" 1 "INFO_PLATFORM_BUILD" 3 "INFO_TRACEABLE_CI_BUILD" 0 "INFO_UNKNOWN_BUILD" ;
VAL_ 1622 DIF_hardwareId 252 "CONFIGURABLE_HWID_PLACEHOLDER" ;
VAL_ 1622 DIF_oilPumpBuildType 2 "INFO_LOCAL_BUILD" 4 "INFO_MFG_BUILD" 1 "INFO_PLATFORM_BUILD" 3 "INFO_TRACEABLE_CI_BUILD" 0 "INFO_UNKNOWN_BUILD" ;
VAL_ 768 BMS_infoIndex 13 "INFO_APP_CRC" 17 "INFO_APP_GITHASH" 15 "INFO_BOOTLOADER_CRC" 18 "INFO_BOOTLOADER_GITHASH" 14 "INFO_BOOTLOADER_SVN" 10 "INFO_BUILD_HWID_COMPONENTID" 0 "INFO_DEPRECATED_0" 1 "INFO_DEPRECATED_1" 2 "INFO_DEPRECATED_2" 3 "INFO_DEPRECATED_3" 4 "INFO_DEPRECATED_4" 5 "INFO_DEPRECATED_5" 6 "INFO_DEPRECATED_6" 7 "INFO_DEPRECATED_7" 8 "INFO_DEPRECATED_8" 9 "INFO_DEPRECATED_9" 255 "INFO_END" 27 "INFO_PACKAGE_PN_15_20" 25 "INFO_PACKAGE_PN_1_7" 26 "INFO_PACKAGE_PN_8_14" 29 "INFO_PACKAGE_SN_1_7" 30 "INFO_PACKAGE_SN_8_14" 11 "INFO_PCBAID_ASSYID_USAGEID" 16 "INFO_SUBCOMPONENT" 31 "INFO_SUBCOMPONENT_GITHASH" 20 "INFO_UDS_PROTOCOL_BOOTCRC" 22 "INFO_VARIANTCRC" 19 "INFO_VERSION_DEPRECATED" ;
VAL_ 768 BMS_buildType 2 "INFO_LOCAL_BUILD" 4 "INFO_MFG_BUILD" 1 "INFO_PLATFORM_BUILD" 3 "INFO_TRACEABLE_CI_BUILD" 0 "INFO_UNKNOWN_BUILD" ;
VAL_ 530 BMS_chgPowerAvailable 2047 "SNA" ;
VAL_ 530 BMS_contactorState 6 "BMS_CTRSET_BLOCKED" 4 "BMS_CTRSET_CLOSED" 3 "BMS_CTRSET_CLOSING" 1 "BMS_CTRSET_OPEN" 2 "BMS_CTRSET_OPENING" 0 "BMS_CTRSET_SNA" 5 "BMS_CTRSET_WELDED" ;
VAL_ 530 BMS_diLimpRequest 0 "LIMP_REQUEST_NONE" 1 "LIMP_REQUEST_WELDED" ;
VAL_ 530 BMS_ecuLogUploadRequest 1 "REQUEST_PRIORITY_1" 2 "REQUEST_PRIORITY_2" 3 "REQUEST_PRIORITY_3" 0 "REQUEST_PRIORITY_NONE" ;
VAL_ 530 BMS_hvState 1 "HV_COMING_UP" 0 "HV_DOWN" 2 "HV_GOING_DOWN" 6 "HV_UP" 4 "HV_UP_FOR_CHARGE" 5 "HV_UP_FOR_DC_CHARGE" 3 "HV_UP_FOR_DRIVE" ;
VAL_ 530 BMS_isolationResistance 1023 "SNA" ;
VAL_ 530 BMS_smStateRequest 3 "BMS_CHARGE" 5 "BMS_CLEAR_FAULT" 10 "BMS_DIAG" 1 "BMS_DRIVE" 6 "BMS_FAULT" 4 "BMS_FEIM" 9 "BMS_SNA" 0 "BMS_STANDBY" 2 "BMS_SUPPORT" 8 "BMS_TEST" 7 "BMS_WELD" ;
VAL_ 530 BMS_state 3 "BMS_CHARGE" 5 "BMS_CLEAR_FAULT" 10 "BMS_DIAG" 1 "BMS_DRIVE" 6 "BMS_FAULT" 4 "BMS_FEIM" 9 "BMS_SNA" 0 "BMS_STANDBY" 2 "BMS_SUPPORT" 8 "BMS_TEST" 7 "BMS_WELD" ;
VAL_ 530 BMS_uiChargeStatus 2 "BMS_ABOUT_TO_CHARGE" 4 "BMS_CHARGE_COMPLETE" 5 "BMS_CHARGE_STOPPED" 3 "BMS_CHARGING" 0 "BMS_DISCONNECTED" 1 "BMS_NO_POWER" ;
VAL_ 796 CC_currentLimit 255 "SNA" ;
VAL_ 796 CC_gridGrounding 1 "CC_GRID_GROUNDING_IT_SplitPhase" 2 "CC_GRID_GROUNDING_SNA" 0 "CC_GRID_GROUNDING_TN_TT" ;
VAL_ 796 CC_line1Voltage 511 "SNA" ;
VAL_ 796 CC_line2Voltage 511 "SNA" ;
VAL_ 796 CC_line3Voltage 511 "SNA" ;
VAL_ 796 CC_numPhases 0 "SNA" ;
VAL_ 796 CC_pilotState 2 "CC_PILOT_STATE_FAULTED" 1 "CC_PILOT_STATE_IDLE" 0 "CC_PILOT_STATE_READY" 3 "CC_PILOT_STATE_SNA" ;
VAL_ 573 CP_chargeShutdownRequest 2 "EMERGENCY_SHUTDOWN_REQUESTED" 1 "GRACEFUL_SHUTDOWN_REQUESTED" 0 "NO_SHUTDOWN_REQUESTED" ;
VAL_ 573 CP_hvChargeStatus 1 "CP_CHARGE_CONNECTED" 5 "CP_CHARGE_ENABLED" 6 "CP_CHARGE_FAULTED" 0 "CP_CHARGE_INACTIVE" 2 "CP_CHARGE_STANDBY" 4 "CP_EVSE_TEST_PASSED" 3 "CP_EXT_EVSE_TEST_ACTIVE" ;
VAL_ 317 CP_chargeShutdownRequest 2 "EMERGENCY_SHUTDOWN_REQUESTED" 1 "GRACEFUL_SHUTDOWN_REQUESTED" 0 "NO_SHUTDOWN_REQUESTED" ;
VAL_ 317 CP_evseChargeType 2 "AC_CHARGER_PRESENT" 1 "DC_CHARGER_PRESENT" 0 "NO_CHARGER_PRESENT" ;
VAL_ 317 CP_hvChargeStatus 1 "CP_CHARGE_CONNECTED" 5 "CP_CHARGE_ENABLED" 6 "CP_CHARGE_FAULTED" 0 "CP_CHARGE_INACTIVE" 2 "CP_CHARGE_STANDBY" 4 "CP_EVSE_TEST_PASSED" 3 "CP_EXT_EVSE_TEST_ACTIVE" ;
VAL_ 1085 CP_chargeShutdownRequest_log 2 "EMERGENCY_SHUTDOWN_REQUESTED" 1 "GRACEFUL_SHUTDOWN_REQUESTED" 0 "NO_SHUTDOWN_REQUESTED" ;
VAL_ 1085 CP_evseChargeType_log 2 "AC_CHARGER_PRESENT" 1 "DC_CHARGER_PRESENT" 0 "NO_CHARGER_PRESENT" ;
VAL_ 1085 CP_hvChargeStatus_log 1 "CP_CHARGE_CONNECTED" 5 "CP_CHARGE_ENABLED" 6 "CP_CHARGE_FAULTED" 0 "CP_CHARGE_INACTIVE" 2 "CP_CHARGE_STANDBY" 4 "CP_EVSE_TEST_PASSED" 3 "CP_EXT_EVSE_TEST_ACTIVE" ;
VAL_ 541 CP_acChargeState 1 "AC_CHARGE_CONNECTED_CHARGE_BLOCKED" 3 "AC_CHARGE_ENABLED" 6 "AC_CHARGE_FAULT" 0 "AC_CHARGE_INACTIVE" 4 "AC_CHARGE_ONBOARD_CHARGER_SHUTDOWN" 2 "AC_CHARGE_STANDBY" 5 "AC_CHARGE_VEH_SHUTDOWN" ;
VAL_ 541 CP_cableType 2 "CHG_CABLE_TYPE_GB_AC" 3 "CHG_CABLE_TYPE_GB_DC" 0 "CHG_CABLE_TYPE_IEC" 1 "CHG_CABLE_TYPE_SAE" 4 "CHG_CABLE_TYPE_SNA" ;
VAL_ 541 CP_evseChargeType_UI 2 "AC_CHARGER_PRESENT" 1 "DC_CHARGER_PRESENT" 0 "NO_CHARGER_PRESENT" ;
VAL_ 541 CP_gbState 10 "GBDC_CHARGE_DISABLING" 5 "GBDC_CHARGE_PARAM_CONFIG" 8 "GBDC_CHARGING" 2 "GBDC_COMMS_RECEIVED" 11 "GBDC_END_OF_CHARGE" 12 "GBDC_ERROR_HANDLING" 14 "GBDC_FAULTED" 3 "GBDC_HANDSHAKING_EXT_ISO" 0 "GBDC_INACTIVE" 7 "GBDC_READY_TO_CHARGE" 4 "GBDC_RECOGNITION" 13 "GBDC_RETRY_CHARGE" 9 "GBDC_STOP_CHARGE_REQUESTED" 15 "GBDC_TESTER_PRESENT" 6 "GBDC_VEH_PACK_PRECHARGE" 1 "GBDC_WAIT_FOR_COMMS" ;
VAL_ 541 CP_gbdcFailureReason 1 "GBDC_ATTEMPTS_EXPIRED" 3 "GBDC_CRITICAL_FAILURE" 0 "GBDC_FAILURE_NONE" 2 "GBDC_SHUTDOWN_FAILURE" ;
VAL_ 541 CP_gbdcStopChargeReason 3 "GBDC_COMMS_TIMEOUT" 5 "GBDC_EVSE_CRITICAL_FAULT" 4 "GBDC_EVSE_FAULT" 2 "GBDC_EVSE_REQUESTED" 6 "GBDC_LIVE_DISCONNECT" 0 "GBDC_STOP_REASON_NONE" 7 "GBDC_SUPERCHARGER_COMMS_TIMEOUT" 1 "GBDC_VEH_REQUESTED" ;
VAL_ 541 CP_iecComboState 6 "IEC_COMBO_CABLE_CHECK" 5 "IEC_COMBO_CHARGE_PARAM_DISCOVERY" 1 "IEC_COMBO_CONNECTED" 8 "IEC_COMBO_ENABLED" 10 "IEC_COMBO_END_OF_CHARGE" 11 "IEC_COMBO_FAULT" 0 "IEC_COMBO_INACTIVE" 4 "IEC_COMBO_PAYMENT_SELECTION" 7 "IEC_COMBO_PRECHARGE" 3 "IEC_COMBO_SERVICE_DISCOVERY" 9 "IEC_COMBO_SHUTDOWN" 2 "IEC_COMBO_V2G_SESSION_SETUP" 12 "IEC_COMBO_WAIT_RESTART" ;
VAL_ 541 CP_pilot 3 "CHG_PILOT_FAST_CHARGE" 1 "CHG_PILOT_FAULTED" 4 "CHG_PILOT_IDLE" 5 "CHG_PILOT_INVALID" 2 "CHG_PILOT_LINE_CHARGE" 0 "CHG_PILOT_NONE" 7 "CHG_PILOT_SNA" 6 "CHG_PILOT_UNUSED_6" ;
VAL_ 541 CP_proximity 1 "CHG_PROXIMITY_DISCONNECTED" 3 "CHG_PROXIMITY_LATCHED" 0 "CHG_PROXIMITY_SNA" 2 "CHG_PROXIMITY_UNLATCHED" ;
VAL_ 541 CP_teslaDcState 1 "TESLA_DC_CONNECTED_CHARGE_BLOCKED" 9 "TESLA_DC_EMERGENCY_SHUTDOWN" 6 "TESLA_DC_ENABLED" 7 "TESLA_DC_EVSE_SHUTDOWN" 5 "TESLA_DC_EXT_PRECHARGE_ACTIVE" 3 "TESLA_DC_EXT_TESTS_ENABLED" 4 "TESLA_DC_EXT_TEST_ACTIVE" 10 "TESLA_DC_FAULT" 0 "TESLA_DC_INACTIVE" 2 "TESLA_DC_STANDBY" 8 "TESLA_DC_VEH_SHUTDOWN" ;
VAL_ 541 CP_teslaSwcanState 1 "TESLA_SWCAN_ACCEPT" 3 "TESLA_SWCAN_ESTABLISHED" 4 "TESLA_SWCAN_FAULT" 5 "TESLA_SWCAN_GO_TO_SLEEP" 0 "TESLA_SWCAN_INACTIVE" 6 "TESLA_SWCAN_OFFBOARD_UPDATE_IN_PROGRESS" 2 "TESLA_SWCAN_RECEIVE" ;
VAL_ 1859 VCRIGHT_mirrorRecallStatus 2 "RECALL_COMPLETE" 3 "RECALL_INTERRUPTED" 1 "RECALL_IN_PROGRESS" 0 "RECALL_SNA" ;
VAL_ 1859 VCRIGHT_seatRecallStatus 2 "RECALL_COMPLETE" 3 "RECALL_INTERRUPTED" 1 "RECALL_IN_PROGRESS" 0 "RECALL_SNA" ;
VAL_ 1859 VCRIGHT_systemRecallStatus 2 "RECALL_COMPLETE" 3 "RECALL_INTERRUPTED" 1 "RECALL_IN_PROGRESS" 0 "RECALL_SNA" ;
VAL_ 1885 CP_sensorDataSelect 2 "CP_SENSOR_DOOR" 0 "CP_SENSOR_DOOR_COUNTS" 4 "CP_SENSOR_INDUCTIVE_DOOR" 12 "CP_SENSOR_INLET_HARNESS_ID" 3 "CP_SENSOR_LATCH" 9 "CP_SENSOR_PILOT" 10 "CP_SENSOR_PILOT2" 1 "CP_SENSOR_PIN_TEMP" 8 "CP_SENSOR_PROX" 11 "CP_SENSOR_PROX_GB" 7 "CP_SENSOR_RAILS" 5 "CP_SENSOR_SAFETY" 6 "CP_SENSOR_UHF" ;
VAL_ 1885 CP_inlet1HarnessIdState 1 "HARNESS_PEDIGREE_INVALID" 0 "HARNESS_PEDIGREE_UNKNOWN_SNA" 2 "HARNESS_PEDIGREE_VALID" ;
VAL_ 1885 CP_inlet2HarnessIdState 1 "HARNESS_PEDIGREE_INVALID" 0 "HARNESS_PEDIGREE_UNKNOWN_SNA" 2 "HARNESS_PEDIGREE_VALID" ;
VAL_ 819 UI_acChargeCurrentLimit 127 "SNA" ;
VAL_ 819 UI_brickBalancingDisabled 0 "FALSE" 1 "TRUE" ;
VAL_ 819 UI_brickVLoggingRequest 0 "FALSE" 1 "TRUE" ;
VAL_ 820 UI_limitMode 2 "LIMIT_FACTORY" 0 "LIMIT_NORMAL" 3 "LIMIT_SERVICE" 1 "LIMIT_VALET" ;
VAL_ 820 UI_motorOnMode 1 "MOTORONMODE_FRONT_ONLY" 0 "MOTORONMODE_NORMAL" 2 "MOTORONMODE_REAR_ONLY" ;
VAL_ 820 UI_pedalMap 0 "CHILL" 2 "PERFORMANCE" 1 "SPORT" ;
VAL_ 820 UI_speedLimit 255 "SNA" ;
VAL_ 820 UI_stoppingMode 1 "CREEP" 2 "HOLD" 0 "STANDARD" ;
VAL_ 820 UI_systemPowerLimit 31 "SNA" ;
VAL_ 820 UI_systemTorqueLimit 63 "SNA" ;
VAL_ 820 UI_wasteMode 2 "WASTE_TYPE_FULL" 0 "WASTE_TYPE_NONE" 1 "WASTE_TYPE_PARTIAL" ;
VAL_ 820 UI_wasteModeRegenLimit 3 "MAX_REGEN_CURRENT_0A" 2 "MAX_REGEN_CURRENT_10A" 1 "MAX_REGEN_CURRENT_30A" 0 "MAX_REGEN_CURRENT_MAX" ;
VAL_ 820 UI_closureConfirmed 1 "CONFIRMED_FRUNK" 0 "CONFIRMED_NONE" 2 "CONFIRMED_PROX" ;
VAL_ 577 VCFRONT_coolantAirPurgeBatState 1 "AIR_PURGE_STATE_ACTIVE" 2 "AIR_PURGE_STATE_COMPLETE" 0 "AIR_PURGE_STATE_INACTIVE" 3 "AIR_PURGE_STATE_INTERRUPTED" 4 "AIR_PURGE_STATE_PENDING" ;
VAL_ 577 VCFRONT_coolantFlowBatReason 4 "ACTIVE_MANAGER_BATT" 9 "ACTIVE_MANAGER_PT" 6 "BMS_FLOW_REQ" 1 "COOLANT_AIR_PURGE" 7 "DAS_FLOW_REQ" 13 "DIS_FLOW_REQ" 12 "DI_FLOW_REQ" 14 "HP_FLOW_REQ" 0 "NONE" 2 "NO_FLOW_REQ" 3 "OVERRIDE_BATT" 8 "OVERRIDE_PT" 5 "PASSIVE_MANAGER_BATT" 10 "PASSIVE_MANAGER_PT" 11 "PCS_FLOW_REQ" ;
VAL_ 577 VCFRONT_coolantFlowPTReason 4 "ACTIVE_MANAGER_BATT" 9 "ACTIVE_MANAGER_PT" 6 "BMS_FLOW_REQ" 1 "COOLANT_AIR_PURGE" 7 "DAS_FLOW_REQ" 13 "DIS_FLOW_REQ" 12 "DI_FLOW_REQ" 14 "HP_FLOW_REQ" 0 "NONE" 2 "NO_FLOW_REQ" 3 "OVERRIDE_BATT" 8 "OVERRIDE_PT" 5 "PASSIVE_MANAGER_BATT" 10 "PASSIVE_MANAGER_PT" 11 "PCS_FLOW_REQ" ;
VAL_ 577 VCFRONT_wasteHeatRequestType 2 "WASTE_TYPE_FULL" 0 "WASTE_TYPE_NONE" 1 "WASTE_TYPE_PARTIAL" ;
VAL_ 1493 DI_IGBTJunctTemp 255 "SNA" ;
VAL_ 1366 DIF_IGBTJunctTemp 255 "SNA" ;
VAL_ 2005 DIR_fluxState 5 "DI_FLUXSTATE_ENABLED" 9 "DI_FLUXSTATE_FAULT" 4 "DI_FLUXSTATE_FLUX_DOWN" 3 "DI_FLUXSTATE_FLUX_UP" 6 "DI_FLUXSTATE_ICONTROL" 2 "DI_FLUXSTATE_STANDBY" 0 "DI_FLUXSTATE_START" 10 "DI_FLUXSTATE_STATIONARY_WASTE" 1 "DI_FLUXSTATE_TEST" 7 "DI_FLUXSTATE_VCONTROL" ;
VAL_ 2005 DIR_gateDriveState 3 "PSTG_GD_STATE_CONFIGURED" 2 "PSTG_GD_STATE_CONFIGURING" 0 "PSTG_GD_STATE_INIT" 4 "PSTG_GD_STATE_NOT_CONFIGURED" 1 "PSTG_GD_STATE_SELFTEST" ;
VAL_ 2005 DIR_gateDriveSupplyState 0 "PSTG_GD_SUPPLY_DOWN" 3 "PSTG_GD_SUPPLY_FALLING" 1 "PSTG_GD_SUPPLY_RISING" 2 "PSTG_GD_SUPPLY_UP" ;
VAL_ 2005 DIR_magnetTempEst 0 "SNA" ;
VAL_ 2005 DIR_motorType 8 "DI_MOTOR_F1A" 10 "DI_MOTOR_F1AC" 11 "DI_MOTOR_F2AB" 12 "DI_MOTOR_F2AC" 13 "DI_MOTOR_F2AD" 14 "DI_MOTOR_F2AE" 26 "DI_MOTOR_F2AE_AL" 15 "DI_MOTOR_F2APMSRM" 17 "DI_MOTOR_IM100A" 19 "DI_MOTOR_IM100B" 22 "DI_MOTOR_IM130C" 24 "DI_MOTOR_IM130D" 25 "DI_MOTOR_IM130D_AL" 27 "DI_MOTOR_IM130D_AL_POSCO" 20 "DI_MOTOR_IM216A" 3 "DI_MOTOR_M7M3" 4 "DI_MOTOR_M7M4" 5 "DI_MOTOR_M7M5" 7 "DI_MOTOR_M7M6" 6 "DI_MOTOR_M8A" 16 "DI_MOTOR_PM216A" 18 "DI_MOTOR_PM216B" 21 "DI_MOTOR_PM216C" 30 "DI_MOTOR_PM216CSR" 31 "DI_MOTOR_PM216CSR_N42" 23 "DI_MOTOR_PM216D" 32 "DI_MOTOR_PM228B" 28 "DI_MOTOR_PM275B" 29 "DI_MOTOR_PM350B" 1 "DI_MOTOR_ROADSTER_BASE" 2 "DI_MOTOR_ROADSTER_SPORT" 0 "DI_MOTOR_SNA" 9 "DI_MOTOR_SSR1A" ;
VAL_ 2005 DIR_oilPumpPhaseVoltage 255 "SNA" ;
VAL_ 2005 DIR_oilPumpPressureEstimateMax 255 "SNA" ;
VAL_ 2005 DIR_oilPumpPressureExpectedMin 255 "SNA" ;
VAL_ 2005 DIR_powerStageSafeState 2 "PSTG_SAFESTATE_3PS_HIGH" 3 "PSTG_SAFESTATE_3PS_LOW" 1 "PSTG_SAFESTATE_ALL_OFF" 0 "PSTG_SAFESTATE_NONE" ;
VAL_ 2005 DIR_pwmState 1 "PWMSTATE_DPWM2" 2 "PWMSTATE_OPWM1" 3 "PWMSTATE_OPWM2" 0 "PWMSTATE_SVPWM" ;
VAL_ 2005 DIR_rotorOffsetLearningState 9 "ROL_NUM_STATES" 2 "ROL_STATE_ACCELERATE" 5 "ROL_STATE_CORRECT" 8 "ROL_STATE_DONE" 0 "ROL_STATE_INIT" 4 "ROL_STATE_MEASURE" 3 "ROL_STATE_SHIFT" 6 "ROL_STATE_VERIFY" 1 "ROL_STATE_WAIT" 7 "ROL_STATE_WRITE" ;
VAL_ 2005 DIR_ssmState 5 "SSM_STATE_ABORT" 4 "SSM_STATE_ENABLE" 8 "SSM_STATE_FAULT" 2 "SSM_STATE_IDLE" 7 "SSM_STATE_RETRY" 3 "SSM_STATE_STANDBY" 0 "SSM_STATE_START" 1 "SSM_STATE_UNAVAILABLE" 6 "SSM_STATE_WAIT_FOR_RETRY" ;
VAL_ 2005 DIR_tcMaxRequest 255 "SNA" ;
VAL_ 2005 DIR_tcMinRequest 255 "SNA" ;
VAL_ 2005 DIR_usmState 3 "USM_STATE_ABORT" 4 "USM_STATE_ENABLE" 5 "USM_STATE_FAULT" 2 "USM_STATE_RETRY" 1 "USM_STATE_STANDBY" 0 "USM_STATE_START" 6 "USM_STATE_UNAVAILABLE" 7 "USM_STATE_WAIT_FOR_RETRY" ;
VAL_ 1879 DIF_fluxState 5 "DI_FLUXSTATE_ENABLED" 9 "DI_FLUXSTATE_FAULT" 4 "DI_FLUXSTATE_FLUX_DOWN" 3 "DI_FLUXSTATE_FLUX_UP" 6 "DI_FLUXSTATE_ICONTROL" 2 "DI_FLUXSTATE_STANDBY" 0 "DI_FLUXSTATE_START" 10 "DI_FLUXSTATE_STATIONARY_WASTE" 1 "DI_FLUXSTATE_TEST" 7 "DI_FLUXSTATE_VCONTROL" ;
VAL_ 1879 DIF_gateDriveState 3 "PSTG_GD_STATE_CONFIGURED" 2 "PSTG_GD_STATE_CONFIGURING" 0 "PSTG_GD_STATE_INIT" 4 "PSTG_GD_STATE_NOT_CONFIGURED" 1 "PSTG_GD_STATE_SELFTEST" ;
VAL_ 1879 DIF_gateDriveSupplyState 0 "PSTG_GD_SUPPLY_DOWN" 3 "PSTG_GD_SUPPLY_FALLING" 1 "PSTG_GD_SUPPLY_RISING" 2 "PSTG_GD_SUPPLY_UP" ;
VAL_ 1879 DIF_magnetTempEst 0 "SNA" ;
VAL_ 1879 DIF_motorType 8 "DI_MOTOR_F1A" 10 "DI_MOTOR_F1AC" 11 "DI_MOTOR_F2AB" 12 "DI_MOTOR_F2AC" 13 "DI_MOTOR_F2AD" 14 "DI_MOTOR_F2AE" 26 "DI_MOTOR_F2AE_AL" 15 "DI_MOTOR_F2APMSRM" 17 "DI_MOTOR_IM100A" 19 "DI_MOTOR_IM100B" 22 "DI_MOTOR_IM130C" 24 "DI_MOTOR_IM130D" 25 "DI_MOTOR_IM130D_AL" 27 "DI_MOTOR_IM130D_AL_POSCO" 20 "DI_MOTOR_IM216A" 3 "DI_MOTOR_M7M3" 4 "DI_MOTOR_M7M4" 5 "DI_MOTOR_M7M5" 7 "DI_MOTOR_M7M6" 6 "DI_MOTOR_M8A" 16 "DI_MOTOR_PM216A" 18 "DI_MOTOR_PM216B" 21 "DI_MOTOR_PM216C" 30 "DI_MOTOR_PM216CSR" 31 "DI_MOTOR_PM216CSR_N42" 23 "DI_MOTOR_PM216D" 32 "DI_MOTOR_PM228B" 28 "DI_MOTOR_PM275B" 29 "DI_MOTOR_PM350B" 1 "DI_MOTOR_ROADSTER_BASE" 2 "DI_MOTOR_ROADSTER_SPORT" 0 "DI_MOTOR_SNA" 9 "DI_MOTOR_SSR1A" ;
VAL_ 1879 DIF_oilPumpPhaseVoltage 255 "SNA" ;
VAL_ 1879 DIF_oilPumpPressureEstimateMax 255 "SNA" ;
VAL_ 1879 DIF_oilPumpPressureExpectedMin 255 "SNA" ;
VAL_ 1879 DIF_powerStageSafeState 2 "PSTG_SAFESTATE_3PS_HIGH" 3 "PSTG_SAFESTATE_3PS_LOW" 1 "PSTG_SAFESTATE_ALL_OFF" 0 "PSTG_SAFESTATE_NONE" ;
VAL_ 1879 DIF_pwmState 1 "PWMSTATE_DPWM2" 2 "PWMSTATE_OPWM1" 3 "PWMSTATE_OPWM2" 0 "PWMSTATE_SVPWM" ;
VAL_ 1879 DIF_rotorOffsetLearningState 9 "ROL_NUM_STATES" 2 "ROL_STATE_ACCELERATE" 5 "ROL_STATE_CORRECT" 8 "ROL_STATE_DONE" 0 "ROL_STATE_INIT" 4 "ROL_STATE_MEASURE" 3 "ROL_STATE_SHIFT" 6 "ROL_STATE_VERIFY" 1 "ROL_STATE_WAIT" 7 "ROL_STATE_WRITE" ;
VAL_ 1879 DIF_ssmState 5 "SSM_STATE_ABORT" 4 "SSM_STATE_ENABLE" 8 "SSM_STATE_FAULT" 2 "SSM_STATE_IDLE" 7 "SSM_STATE_RETRY" 3 "SSM_STATE_STANDBY" 0 "SSM_STATE_START" 1 "SSM_STATE_UNAVAILABLE" 6 "SSM_STATE_WAIT_FOR_RETRY" ;
VAL_ 1879 DIF_tcMaxRequest 255 "SNA" ;
VAL_ 1879 DIF_tcMinRequest 255 "SNA" ;
VAL_ 1879 DIF_usmState 3 "USM_STATE_ABORT" 4 "USM_STATE_ENABLE" 5 "USM_STATE_FAULT" 2 "USM_STATE_RETRY" 1 "USM_STATE_STANDBY" 0 "USM_STATE_START" 6 "USM_STATE_UNAVAILABLE" 7 "USM_STATE_WAIT_FOR_RETRY" ;
VAL_ 694 DI_ptcStateUI 0 "FAULTED" 1 "BACKUP" 2 "ON" 3 "SNA" ;
VAL_ 694 DI_tractionControlModeUI 0 "NORMAL" 1 "SLIP_START" 2 "DEV_MODE_1" 3 "DEV_MODE_2" 4 "ROLLS_MODE" 5 "DYNO_MODE" 6 "OFFROAD_ASSIST" ;
VAL_ 545 VCFRONT_LVPowerStateIndex 0 "Mux0" 1 "Mux1" ;
VAL_ 545 VCFRONT_CMPDLVState 3 "LV_FAULT" 2 "LV_GOING_DOWN" 0 "LV_OFF" 1 "LV_ON" ;
VAL_ 545 VCFRONT_amplifierLVRequest 3 "LV_FAULT" 2 "LV_GOING_DOWN" 0 "LV_OFF" 1 "LV_ON" ;
VAL_ 545 VCFRONT_cpLVRequest 3 "LV_FAULT" 2 "LV_GOING_DOWN" 0 "LV_OFF" 1 "LV_ON" ;
VAL_ 545 VCFRONT_das1HighCurrentLVState 3 "LV_FAULT" 2 "LV_GOING_DOWN" 0 "LV_OFF" 1 "LV_ON" ;
VAL_ 545 VCFRONT_das2HighCurrentLVState 3 "LV_FAULT" 2 "LV_GOING_DOWN" 0 "LV_OFF" 1 "LV_ON" ;
VAL_ 545 VCFRONT_difLVState 3 "LV_FAULT" 2 "LV_GOING_DOWN" 0 "LV_OFF" 1 "LV_ON" ;
VAL_ 545 VCFRONT_dirLVRequest 3 "LV_FAULT" 2 "LV_GOING_DOWN" 0 "LV_OFF" 1 "LV_ON" ;
VAL_ 545 VCFRONT_epasLVState 3 "LV_FAULT" 2 "LV_GOING_DOWN" 0 "LV_OFF" 1 "LV_ON" ;
VAL_ 545 VCFRONT_espLVState 3 "LV_FAULT" 2 "LV_GOING_DOWN" 0 "LV_OFF" 1 "LV_ON" ;
VAL_ 545 VCFRONT_hvacCompLVState 3 "LV_FAULT" 2 "LV_GOING_DOWN" 0 "LV_OFF" 1 "LV_ON" ;
VAL_ 545 VCFRONT_hvcLVRequest 3 "LV_FAULT" 2 "LV_GOING_DOWN" 0 "LV_OFF" 1 "LV_ON" ;
VAL_ 545 VCFRONT_iBoosterLVState 3 "LV_FAULT" 2 "LV_GOING_DOWN" 0 "LV_OFF" 1 "LV_ON" ;
VAL_ 545 VCFRONT_ocsLVRequest 3 "LV_FAULT" 2 "LV_GOING_DOWN" 0 "LV_OFF" 1 "LV_ON" ;
VAL_ 545 VCFRONT_oilPumpFrontLVState 3 "LV_FAULT" 2 "LV_GOING_DOWN" 0 "LV_OFF" 1 "LV_ON" ;
VAL_ 545 VCFRONT_oilPumpRearLVRequest 3 "LV_FAULT" 2 "LV_GOING_DOWN" 0 "LV_OFF" 1 "LV_ON" ;
VAL_ 545 VCFRONT_parkLVState 3 "LV_FAULT" 2 "LV_GOING_DOWN" 0 "LV_OFF" 1 "LV_ON" ;
VAL_ 545 VCFRONT_pcsLVState 3 "LV_FAULT" 2 "LV_GOING_DOWN" 0 "LV_OFF" 1 "LV_ON" ;
VAL_ 545 VCFRONT_ptcLVRequest 3 "LV_FAULT" 2 "LV_GOING_DOWN" 0 "LV_OFF" 1 "LV_ON" ;
VAL_ 545 VCFRONT_radcLVState 3 "LV_FAULT" 2 "LV_GOING_DOWN" 0 "LV_OFF" 1 "LV_ON" ;
VAL_ 545 VCFRONT_rcmLVRequest 3 "LV_FAULT" 2 "LV_GOING_DOWN" 0 "LV_OFF" 1 "LV_ON" ;
VAL_ 545 VCFRONT_sccmLVRequest 3 "LV_FAULT" 2 "LV_GOING_DOWN" 0 "LV_OFF" 1 "LV_ON" ;
VAL_ 545 VCFRONT_tasLVState 3 "LV_FAULT" 2 "LV_GOING_DOWN" 0 "LV_OFF" 1 "LV_ON" ;
VAL_ 545 VCFRONT_tpmsLVRequest 3 "LV_FAULT" 2 "LV_GOING_DOWN" 0 "LV_OFF" 1 "LV_ON" ;
VAL_ 545 VCFRONT_tunerLVRequest 3 "LV_FAULT" 2 "LV_GOING_DOWN" 0 "LV_OFF" 1 "LV_ON" ;
VAL_ 545 VCFRONT_uiHiCurrentLVState 3 "LV_FAULT" 2 "LV_GOING_DOWN" 0 "LV_OFF" 1 "LV_ON" ;
VAL_ 545 VCFRONT_vcleftHiCurrentLVState 3 "LV_FAULT" 2 "LV_GOING_DOWN" 0 "LV_OFF" 1 "LV_ON" ;
VAL_ 545 VCFRONT_vcrightHiCurrentLVState 3 "LV_FAULT" 2 "LV_GOING_DOWN" 0 "LV_OFF" 1 "LV_ON" ;
VAL_ 549 VCRIGHT_amplifierLVState 3 "LV_FAULT" 2 "LV_GOING_DOWN" 0 "LV_OFF" 1 "LV_ON" ;
VAL_ 549 VCRIGHT_eFuseLockoutStatus 2 "EFUSE_LOCKOUT_STATUS_ACTIVE" 0 "EFUSE_LOCKOUT_STATUS_IDLE" 1 "EFUSE_LOCKOUT_STATUS_PENDING" ;
VAL_ 549 VCRIGHT_hvcLVState 3 "LV_FAULT" 2 "LV_GOING_DOWN" 0 "LV_OFF" 1 "LV_ON" ;
VAL_ 549 VCRIGHT_lumbarLVState 3 "LV_FAULT" 2 "LV_GOING_DOWN" 0 "LV_OFF" 1 "LV_ON" ;
VAL_ 549 VCRIGHT_ocsLVState 3 "LV_FAULT" 2 "LV_GOING_DOWN" 0 "LV_OFF" 1 "LV_ON" ;
VAL_ 549 VCRIGHT_ptcLVState 3 "LV_FAULT" 2 "LV_GOING_DOWN" 0 "LV_OFF" 1 "LV_ON" ;
VAL_ 549 VCRIGHT_rcmLVState 3 "LV_FAULT" 2 "LV_GOING_DOWN" 0 "LV_OFF" 1 "LV_ON" ;
VAL_ 549 VCRIGHT_rearOilPumpLVState 3 "LV_FAULT" 2 "LV_GOING_DOWN" 0 "LV_OFF" 1 "LV_ON" ;
VAL_ 549 VCRIGHT_tunerLVState 3 "LV_FAULT" 2 "LV_GOING_DOWN" 0 "LV_OFF" 1 "LV_ON" ;
VAL_ 549 VCRIGHT_vehiclePowerStateDBG 2 "VEHICLE_POWER_STATE_ACCESSORY" 1 "VEHICLE_POWER_STATE_CONDITIONING" 3 "VEHICLE_POWER_STATE_DRIVE" 0 "VEHICLE_POWER_STATE_OFF" ;
VAL_ 753 VCFRONT_eFuseDebugStatusIndex 8 "VCF_DBG_STS_AUTOPILOT_1" 9 "VCF_DBG_STS_AUTOPILOT_2" 4 "VCF_DBG_STS_EPAS3P" 5 "VCF_DBG_STS_EPAS3S" 6 "VCF_DBG_STS_ESP_MOTOR" 7 "VCF_DBG_STS_ESP_VALVE" 12 "VCF_DBG_STS_HEADLAMPS" 3 "VCF_DBG_STS_IBOOSTER" 18 "VCF_DBG_STS_INVALID" 17 "VCF_DBG_STS_LV_BATTERY_DEBUG" 16 "VCF_DBG_STS_MISC_RAILS" 2 "VCF_DBG_STS_PCS" 14 "VCF_DBG_STS_PUMPS" 15 "VCF_DBG_STS_RAILS_A_B" 10 "VCF_DBG_STS_SLEEP_BYPASS" 11 "VCF_DBG_STS_UI" 13 "VCF_DBG_STS_VBAT_FUSED_HIGH_CURRENT" 1 "VCF_DBG_STS_VCLEFT" 0 "VCF_DBG_STS_VCRIGHT" ;
VAL_ 753 VCFRONT_EPAS3PSelfTestResult 4 "EFUSE_SELF_TEST_EFUSE_RESULT_FAILED_EFUSE_OUTPUT_SHORT" 8 "EFUSE_SELF_TEST_EFUSE_RESULT_FAILED_ENABLE_HIGH_MALFUNCTION" 6 "EFUSE_SELF_TEST_EFUSE_RESULT_FAILED_ENABLE_LOW_MALFUNCTION" 10 "EFUSE_SELF_TEST_EFUSE_RESULT_FAILED_NOT_LATCHED" 7 "EFUSE_SELF_TEST_EFUSE_RESULT_FAILED_POWER_FET_CHANNEL_OPEN" 5 "EFUSE_SELF_TEST_EFUSE_RESULT_FAILED_POWER_FET_STUCK_ON" 3 "EFUSE_SELF_TEST_EFUSE_RESULT_FAILED_RAILS_UNSTABLE" 9 "EFUSE_SELF_TEST_EFUSE_RESULT_FAILED_TURN_OFF_PATH_TOO_SLOW" 0 "EFUSE_SELF_TEST_EFUSE_RESULT_NOT_RUN" 2 "EFUSE_SELF_TEST_EFUSE_RESULT_PASSED" 1 "EFUSE_SELF_TEST_EFUSE_RESULT_RUNNING" 11 "EFUSE_SELF_TEST_EFUSE_RESULT_SKIPPED" ;
VAL_ 753 VCFRONT_EPAS3PState 2 "EFUSE_STATE_LOCKED_OUT" 0 "EFUSE_STATE_OFF" 1 "EFUSE_STATE_ON" ;
VAL_ 753 VCFRONT_EPAS3SSelfTestResult 4 "EFUSE_SELF_TEST_EFUSE_RESULT_FAILED_EFUSE_OUTPUT_SHORT" 8 "EFUSE_SELF_TEST_EFUSE_RESULT_FAILED_ENABLE_HIGH_MALFUNCTION" 6 "EFUSE_SELF_TEST_EFUSE_RESULT_FAILED_ENABLE_LOW_MALFUNCTION" 10 "EFUSE_SELF_TEST_EFUSE_RESULT_FAILED_NOT_LATCHED" 7 "EFUSE_SELF_TEST_EFUSE_RESULT_FAILED_POWER_FET_CHANNEL_OPEN" 5 "EFUSE_SELF_TEST_EFUSE_RESULT_FAILED_POWER_FET_STUCK_ON" 3 "EFUSE_SELF_TEST_EFUSE_RESULT_FAILED_RAILS_UNSTABLE" 9 "EFUSE_SELF_TEST_EFUSE_RESULT_FAILED_TURN_OFF_PATH_TOO_SLOW" 0 "EFUSE_SELF_TEST_EFUSE_RESULT_NOT_RUN" 2 "EFUSE_SELF_TEST_EFUSE_RESULT_PASSED" 1 "EFUSE_SELF_TEST_EFUSE_RESULT_RUNNING" 11 "EFUSE_SELF_TEST_EFUSE_RESULT_SKIPPED" ;
VAL_ 753 VCFRONT_EPAS3SState 2 "EFUSE_STATE_LOCKED_OUT" 0 "EFUSE_STATE_OFF" 1 "EFUSE_STATE_ON" ;
VAL_ 753 VCFRONT_ESPMotorSelfTestResult 4 "EFUSE_SELF_TEST_EFUSE_RESULT_FAILED_EFUSE_OUTPUT_SHORT" 8 "EFUSE_SELF_TEST_EFUSE_RESULT_FAILED_ENABLE_HIGH_MALFUNCTION" 6 "EFUSE_SELF_TEST_EFUSE_RESULT_FAILED_ENABLE_LOW_MALFUNCTION" 10 "EFUSE_SELF_TEST_EFUSE_RESULT_FAILED_NOT_LATCHED" 7 "EFUSE_SELF_TEST_EFUSE_RESULT_FAILED_POWER_FET_CHANNEL_OPEN" 5 "EFUSE_SELF_TEST_EFUSE_RESULT_FAILED_POWER_FET_STUCK_ON" 3 "EFUSE_SELF_TEST_EFUSE_RESULT_FAILED_RAILS_UNSTABLE" 9 "EFUSE_SELF_TEST_EFUSE_RESULT_FAILED_TURN_OFF_PATH_TOO_SLOW" 0 "EFUSE_SELF_TEST_EFUSE_RESULT_NOT_RUN" 2 "EFUSE_SELF_TEST_EFUSE_RESULT_PASSED" 1 "EFUSE_SELF_TEST_EFUSE_RESULT_RUNNING" 11 "EFUSE_SELF_TEST_EFUSE_RESULT_SKIPPED" ;
VAL_ 753 VCFRONT_ESPMotorState 2 "EFUSE_STATE_LOCKED_OUT" 0 "EFUSE_STATE_OFF" 1 "EFUSE_STATE_ON" ;
VAL_ 753 VCFRONT_ESPValveState 2 "EFUSE_STATE_LOCKED_OUT" 0 "EFUSE_STATE_OFF" 1 "EFUSE_STATE_ON" ;
VAL_ 753 VCFRONT_PCSState 2 "EFUSE_STATE_LOCKED_OUT" 0 "EFUSE_STATE_OFF" 1 "EFUSE_STATE_ON" ;
VAL_ 753 VCFRONT_autopilot1State 2 "EFUSE_STATE_LOCKED_OUT" 0 "EFUSE_STATE_OFF" 1 "EFUSE_STATE_ON" ;
VAL_ 753 VCFRONT_autopilot2State 2 "EFUSE_STATE_LOCKED_OUT" 0 "EFUSE_STATE_OFF" 1 "EFUSE_STATE_ON" ;
VAL_ 753 VCFRONT_headlampLeftTemperature 128 "SNA" ;
VAL_ 753 VCFRONT_headlampLeftVoltage 255 "SNA" ;
VAL_ 753 VCFRONT_headlampRightTemperature 128 "SNA" ;
VAL_ 753 VCFRONT_headlampRightVoltage 255 "SNA" ;
VAL_ 753 VCFRONT_iBoosterSelfTestResult 4 "EFUSE_SELF_TEST_EFUSE_RESULT_FAILED_EFUSE_OUTPUT_SHORT" 8 "EFUSE_SELF_TEST_EFUSE_RESULT_FAILED_ENABLE_HIGH_MALFUNCTION" 6 "EFUSE_SELF_TEST_EFUSE_RESULT_FAILED_ENABLE_LOW_MALFUNCTION" 10 "EFUSE_SELF_TEST_EFUSE_RESULT_FAILED_NOT_LATCHED" 7 "EFUSE_SELF_TEST_EFUSE_RESULT_FAILED_POWER_FET_CHANNEL_OPEN" 5 "EFUSE_SELF_TEST_EFUSE_RESULT_FAILED_POWER_FET_STUCK_ON" 3 "EFUSE_SELF_TEST_EFUSE_RESULT_FAILED_RAILS_UNSTABLE" 9 "EFUSE_SELF_TEST_EFUSE_RESULT_FAILED_TURN_OFF_PATH_TOO_SLOW" 0 "EFUSE_SELF_TEST_EFUSE_RESULT_NOT_RUN" 2 "EFUSE_SELF_TEST_EFUSE_RESULT_PASSED" 1 "EFUSE_SELF_TEST_EFUSE_RESULT_RUNNING" 11 "EFUSE_SELF_TEST_EFUSE_RESULT_SKIPPED" ;
VAL_ 753 VCFRONT_iBoosterState 2 "EFUSE_STATE_LOCKED_OUT" 0 "EFUSE_STATE_OFF" 1 "EFUSE_STATE_ON" ;
VAL_ 753 VCFRONT_leftControllerState 2 "EFUSE_STATE_LOCKED_OUT" 0 "EFUSE_STATE_OFF" 1 "EFUSE_STATE_ON" ;
VAL_ 753 VCFRONT_pcsSelfTestResult 4 "EFUSE_SELF_TEST_EFUSE_RESULT_FAILED_EFUSE_OUTPUT_SHORT" 8 "EFUSE_SELF_TEST_EFUSE_RESULT_FAILED_ENABLE_HIGH_MALFUNCTION" 6 "EFUSE_SELF_TEST_EFUSE_RESULT_FAILED_ENABLE_LOW_MALFUNCTION" 10 "EFUSE_SELF_TEST_EFUSE_RESULT_FAILED_NOT_LATCHED" 7 "EFUSE_SELF_TEST_EFUSE_RESULT_FAILED_POWER_FET_CHANNEL_OPEN" 5 "EFUSE_SELF_TEST_EFUSE_RESULT_FAILED_POWER_FET_STUCK_ON" 3 "EFUSE_SELF_TEST_EFUSE_RESULT_FAILED_RAILS_UNSTABLE" 9 "EFUSE_SELF_TEST_EFUSE_RESULT_FAILED_TURN_OFF_PATH_TOO_SLOW" 0 "EFUSE_SELF_TEST_EFUSE_RESULT_NOT_RUN" 2 "EFUSE_SELF_TEST_EFUSE_RESULT_PASSED" 1 "EFUSE_SELF_TEST_EFUSE_RESULT_RUNNING" 11 "EFUSE_SELF_TEST_EFUSE_RESULT_SKIPPED" ;
VAL_ 753 VCFRONT_rightControllerState 2 "EFUSE_STATE_LOCKED_OUT" 0 "EFUSE_STATE_OFF" 1 "EFUSE_STATE_ON" ;
VAL_ 753 VCFRONT_vbatFusedSelfTestResult 4 "EFUSE_SELF_TEST_EFUSE_RESULT_FAILED_EFUSE_OUTPUT_SHORT" 8 "EFUSE_SELF_TEST_EFUSE_RESULT_FAILED_ENABLE_HIGH_MALFUNCTION" 6 "EFUSE_SELF_TEST_EFUSE_RESULT_FAILED_ENABLE_LOW_MALFUNCTION" 10 "EFUSE_SELF_TEST_EFUSE_RESULT_FAILED_NOT_LATCHED" 7 "EFUSE_SELF_TEST_EFUSE_RESULT_FAILED_POWER_FET_CHANNEL_OPEN" 5 "EFUSE_SELF_TEST_EFUSE_RESULT_FAILED_POWER_FET_STUCK_ON" 3 "EFUSE_SELF_TEST_EFUSE_RESULT_FAILED_RAILS_UNSTABLE" 9 "EFUSE_SELF_TEST_EFUSE_RESULT_FAILED_TURN_OFF_PATH_TOO_SLOW" 0 "EFUSE_SELF_TEST_EFUSE_RESULT_NOT_RUN" 2 "EFUSE_SELF_TEST_EFUSE_RESULT_PASSED" 1 "EFUSE_SELF_TEST_EFUSE_RESULT_RUNNING" 11 "EFUSE_SELF_TEST_EFUSE_RESULT_SKIPPED" ;
VAL_ 753 VCFRONT_vcleftSelfTestResult 4 "EFUSE_SELF_TEST_EFUSE_RESULT_FAILED_EFUSE_OUTPUT_SHORT" 8 "EFUSE_SELF_TEST_EFUSE_RESULT_FAILED_ENABLE_HIGH_MALFUNCTION" 6 "EFUSE_SELF_TEST_EFUSE_RESULT_FAILED_ENABLE_LOW_MALFUNCTION" 10 "EFUSE_SELF_TEST_EFUSE_RESULT_FAILED_NOT_LATCHED" 7 "EFUSE_SELF_TEST_EFUSE_RESULT_FAILED_POWER_FET_CHANNEL_OPEN" 5 "EFUSE_SELF_TEST_EFUSE_RESULT_FAILED_POWER_FET_STUCK_ON" 3 "EFUSE_SELF_TEST_EFUSE_RESULT_FAILED_RAILS_UNSTABLE" 9 "EFUSE_SELF_TEST_EFUSE_RESULT_FAILED_TURN_OFF_PATH_TOO_SLOW" 0 "EFUSE_SELF_TEST_EFUSE_RESULT_NOT_RUN" 2 "EFUSE_SELF_TEST_EFUSE_RESULT_PASSED" 1 "EFUSE_SELF_TEST_EFUSE_RESULT_RUNNING" 11 "EFUSE_SELF_TEST_EFUSE_RESULT_SKIPPED" ;
VAL_ 753 VCFRONT_vcrightSelfTestResult 4 "EFUSE_SELF_TEST_EFUSE_RESULT_FAILED_EFUSE_OUTPUT_SHORT" 8 "EFUSE_SELF_TEST_EFUSE_RESULT_FAILED_ENABLE_HIGH_MALFUNCTION" 6 "EFUSE_SELF_TEST_EFUSE_RESULT_FAILED_ENABLE_LOW_MALFUNCTION" 10 "EFUSE_SELF_TEST_EFUSE_RESULT_FAILED_NOT_LATCHED" 7 "EFUSE_SELF_TEST_EFUSE_RESULT_FAILED_POWER_FET_CHANNEL_OPEN" 5 "EFUSE_SELF_TEST_EFUSE_RESULT_FAILED_POWER_FET_STUCK_ON" 3 "EFUSE_SELF_TEST_EFUSE_RESULT_FAILED_RAILS_UNSTABLE" 9 "EFUSE_SELF_TEST_EFUSE_RESULT_FAILED_TURN_OFF_PATH_TOO_SLOW" 0 "EFUSE_SELF_TEST_EFUSE_RESULT_NOT_RUN" 2 "EFUSE_SELF_TEST_EFUSE_RESULT_PASSED" 1 "EFUSE_SELF_TEST_EFUSE_RESULT_RUNNING" 11 "EFUSE_SELF_TEST_EFUSE_RESULT_SKIPPED" ;
VAL_ 578 VCLEFT_cpLVState 3 "LV_FAULT" 2 "LV_GOING_DOWN" 0 "LV_OFF" 1 "LV_ON" ;
VAL_ 578 VCLEFT_diLVState 3 "LV_FAULT" 2 "LV_GOING_DOWN" 0 "LV_OFF" 1 "LV_ON" ;
VAL_ 578 VCLEFT_lumbarLVState 3 "LV_FAULT" 2 "LV_GOING_DOWN" 0 "LV_OFF" 1 "LV_ON" ;
VAL_ 578 VCLEFT_rcmLVState 3 "LV_FAULT" 2 "LV_GOING_DOWN" 0 "LV_OFF" 1 "LV_ON" ;
VAL_ 578 VCLEFT_sccmLVState 3 "LV_FAULT" 2 "LV_GOING_DOWN" 0 "LV_OFF" 1 "LV_ON" ;
VAL_ 578 VCLEFT_swcLVState 3 "LV_FAULT" 2 "LV_GOING_DOWN" 0 "LV_OFF" 1 "LV_ON" ;
VAL_ 578 VCLEFT_tpmsLVState 3 "LV_FAULT" 2 "LV_GOING_DOWN" 0 "LV_OFF" 1 "LV_ON" ;
VAL_ 578 VCLEFT_vehiclePowerStateDBG 2 "VEHICLE_POWER_STATE_ACCESSORY" 1 "VEHICLE_POWER_STATE_CONDITIONING" 3 "VEHICLE_POWER_STATE_DRIVE" 0 "VEHICLE_POWER_STATE_OFF" ;
VAL_ 579 VCRIGHT_hvacStatusIndex 3 "END" 0 "STATUS_UI" 1 "STATUS_VCFRONT" 2 "STATUS_VCFRONT2" ;
VAL_ 579 VCRIGHT_hvacACRunning 0 "OFF" 1 "ON" ;
VAL_ 579 VCRIGHT_hvacAirDistributionMode 4 "DEFROST" 5 "DEFROST_FLOOR" 6 "DEFROST_PANEL" 7 "DEFROST_PANEL_FLOOR" 1 "FLOOR" 0 "NONE" 2 "PANEL" 3 "PANEL_FLOOR" ;
VAL_ 579 VCRIGHT_hvacBlowerSegment 1 "1" 10 "10" 11 "11" 2 "2" 3 "3" 4 "4" 5 "5" 6 "6" 7 "7" 8 "8" 9 "9" 0 "OFF" ;
VAL_ 579 VCRIGHT_hvacDuctTargetLeft 255 "SNA" ;
VAL_ 579 VCRIGHT_hvacDuctTargetRight 255 "SNA" ;
VAL_ 579 VCRIGHT_hvacEvapInletTempEstimat 1023 "SNA" ;
VAL_ 579 VCRIGHT_hvacModelInitStatus 4 "INIT_FORWARD_CALC" 2 "INIT_FROM_SENSORS" 3 "INIT_FROM_SENSORS_PREDICTION_ERROR" 5 "INIT_WAITING_FOR_SENSORS" 1 "NOT_INIT_WAIT_FOR_GTW" 0 "NOT_INIT_WAIT_FOR_SENSORS" ;
VAL_ 579 VCRIGHT_hvacPowerState 0 "OFF" 1 "ON" 4 "OVERHEAT_PROTECT" 3 "OVERHEAT_PROTECT_FANONLY" 2 "PRECONDITION" ;
VAL_ 579 VCRIGHT_hvacRecirc 0 "AUTO" 2 "FRESH" 1 "RECIRC" ;
VAL_ 579 VCRIGHT_hvacSecondRowState 0 "AUTO" 4 "HIGH" 2 "LOW" 3 "MED" 1 "OFF" ;
VAL_ 579 VCRIGHT_hvacVentStatus 0 "BOTH" 1 "LEFT" 2 "RIGHT" ;
VAL_ 579 VCRIGHT_tempDuctLeft 255 "SNA" ;
VAL_ 579 VCRIGHT_tempDuctLeftLower 255 "SNA" ;
VAL_ 579 VCRIGHT_tempDuctLeftUpper 255 "SNA" ;
VAL_ 579 VCRIGHT_tempDuctRight 255 "SNA" ;
VAL_ 579 VCRIGHT_tempDuctRightLower 255 "SNA" ;
VAL_ 579 VCRIGHT_tempDuctRightUpper 255 "SNA" ;
VAL_ 524 VCRIGHT_hvacPerfTestState 2 "BLOWING" 0 "STOPPED" 1 "WAITING" ;
VAL_ 524 VCRIGHT_tempAmbientRaw 0 "SNA" ;
VAL_ 524 VCRIGHT_tempEvaporator 2047 "SNA" ;
VAL_ 524 VCRIGHT_tempEvaporatorTarget 255 "SNA" ;
VAL_ 737 VCFRONT_statusIndex 0 "VCF_STS_IDX_BODY_CONTROLS" 2 "VCF_STS_IDX_HOMELINK" 6 "VCF_STS_IDX_INVALID" 4 "VCF_STS_IDX_LV_BATTERY" 3 "VCF_STS_IDX_REFRIGERANT_SYSTEM" 5 "VCF_STS_IDX_SYSTEM_HEALTH" 1 "VCF_STS_IDX_VEHICLE_STATE" ;
VAL_ 737 VCFRONT_AS8510Voltage 4095 "SNA" ;
VAL_ 737 VCFRONT_airCompressorStatus 4 "VCFRONT_AIR_COMPRESSOR_STATUS_FAULT" 0 "VCFRONT_AIR_COMPRESSOR_STATUS_OFF" 1 "VCFRONT_AIR_COMPRESSOR_STATUS_ON" 5 "VCFRONT_AIR_COMPRESSOR_STATUS_RETRY_AVAILABLE" 7 "VCFRONT_AIR_COMPRESSOR_STATUS_SNA" 2 "VCFRONT_AIR_COMPRESSOR_STATUS_TURNING_OFF" 3 "VCFRONT_AIR_COMPRESSOR_STATUS_TURNING_ON" ;
VAL_ 737 VCFRONT_batterySMState 1 "BATTERY_SM_STATE_CHARGE" 2 "BATTERY_SM_STATE_DISCHARGE" 6 "BATTERY_SM_STATE_DISCONNECTED_BATTERY_TEST" 8 "BATTERY_SM_STATE_FAULT" 0 "BATTERY_SM_STATE_INIT" 5 "BATTERY_SM_STATE_OTA_STANDBY" 4 "BATTERY_SM_STATE_RESISTANCE_ESTIMATION" 7 "BATTERY_SM_STATE_SHORTED_CELL_TEST" 3 "BATTERY_SM_STATE_STANDBY" ;
VAL_ 737 VCFRONT_coolantFillRoutineStatus 3 "FAULTED" 1 "MOVING_TO_FILL_POSITION" 0 "NOT_READY" 2 "READY_TO_FILL" ;
VAL_ 737 VCFRONT_crashDetectedType 1 "CRASH_DETECTED_TYPE_MINOR_1" 2 "CRASH_DETECTED_TYPE_MINOR_2" 0 "CRASH_DETECTED_TYPE_NONE" 3 "CRASH_DETECTED_TYPE_SEVERE" ;
VAL_ 737 VCFRONT_crashState 0 "CRASH_STATE_IDLE" 1 "CRASH_STATE_MINOR_1" 2 "CRASH_STATE_MINOR_2" 3 "CRASH_STATE_SEVERE" ;
VAL_ 737 VCFRONT_frunkLatchStatus 5 "LATCH_AJAR" 2 "LATCH_CLOSED" 3 "LATCH_CLOSING" 7 "LATCH_DEFAULT" 8 "LATCH_FAULT" 1 "LATCH_OPENED" 4 "LATCH_OPENING" 0 "LATCH_SNA" 6 "LATCH_TIMEOUT" ;
VAL_ 737 VCFRONT_frunkLatchType 1 "FRUNK_LATCH_TYPE_DOUBLE_ACTUATOR" 2 "FRUNK_LATCH_TYPE_DOUBLE_PULL" 0 "FRUNK_LATCH_TYPE_UNKNOWN" ;
VAL_ 737 VCFRONT_homelinkCommStatus 3 "HOMELINK_COMM_STATUS_FAULT" 1 "HOMELINK_COMM_STATUS_OFF" 2 "HOMELINK_COMM_STATUS_ON" 0 "HOMELINK_COMM_STATUS_SNA" ;
VAL_ 737 VCFRONT_hvacPerfTestCommand 2 "BLOW" 1 "INIT" 0 "NOT_STARTED" 3 "STOP" ;
VAL_ 737 VCFRONT_iBoosterStateDBG 4 "IBOOSTER_FORCE_OFF" 2 "IBOOSTER_GOING_DOWN" 0 "IBOOSTER_OFF" 1 "IBOOSTER_ON" 3 "IBOOSTER_WRITING_DATA_SHUTDOWN" ;
VAL_ 737 VCFRONT_passengerBuckleStatus 1 "BUCKLED" 0 "UNBUCKLED" ;
VAL_ 737 VCFRONT_pressureRefrigDischarge 255 "SNA" ;
VAL_ 737 VCFRONT_pressureRefrigSuction 127 "SNA" ;
VAL_ 737 VCFRONT_radarHeaterState 4 "HEATER_STATE_FAULT" 2 "HEATER_STATE_OFF" 3 "HEATER_STATE_OFF_UNAVAILABLE" 1 "HEATER_STATE_ON" 0 "HEATER_STATE_SNA" ;
VAL_ 737 VCFRONT_refrigFillRoutineStatus 3 "FAULTED" 1 "MOVING_TO_FILL_POSITION" 0 "NOT_READY" 2 "READY_TO_FILL" ;
VAL_ 737 VCFRONT_vbatMonitorVoltage 4095 "SNA" ;
VAL_ 737 VCFRONT_vehicleStatusDBG 10 "VEHICLE_STATUS_ACCESSORY" 11 "VEHICLE_STATUS_ACCESSORY_PLUS" 3 "VEHICLE_STATUS_BATTERY_POST_WAKE" 12 "VEHICLE_STATUS_CONDITIONING" 14 "VEHICLE_STATUS_CRASH" 13 "VEHICLE_STATUS_DRIVE" 9 "VEHICLE_STATUS_HV_UP_STANDBY" 0 "VEHICLE_STATUS_INIT" 1 "VEHICLE_STATUS_LOW_POWER_STANDBY" 8 "VEHICLE_STATUS_LV_AWAKE" 7 "VEHICLE_STATUS_LV_SHUTDOWN" 15 "VEHICLE_STATUS_OTA" 17 "VEHICLE_STATUS_RESET" 2 "VEHICLE_STATUS_SILENT_WAKE" 5 "VEHICLE_STATUS_SLEEP_SHUTDOWN" 6 "VEHICLE_STATUS_SLEEP_STANDBY" 4 "VEHICLE_STATUS_SYSTEM_CHECKS" 16 "VEHICLE_STATUS_TURN_ON_RAILS" ;
VAL_ 737 VCFRONT_voltageProfile 3 "VOLTAGE_PROFILE_ALWAYS_CLOSED_CONTACTORS" 0 "VOLTAGE_PROFILE_CHARGE" 1 "VOLTAGE_PROFILE_FLOAT" 2 "VOLTAGE_PROFILE_REDUCED_FLOAT" ;
VAL_ 737 VCFRONT_wiperPosition 3 "WIPER_POSITION_DELAYED_REST" 2 "WIPER_POSITION_DEPRESSED_PARK" 1 "WIPER_POSITION_SERVICE" 0 "WIPER_POSITION_SNA" 4 "WIPER_POSITION_WIPING" ;
VAL_ 737 VCFRONT_wiperSpeed 2 "WIPER_SPEED_1" 3 "WIPER_SPEED_2" 4 "WIPER_SPEED_3" 5 "WIPER_SPEED_4" 6 "WIPER_SPEED_5" 8 "WIPER_SPEED_HIGH" 7 "WIPER_SPEED_LOW" 1 "WIPER_SPEED_OFF" 0 "WIPER_SPEED_SNA" ;
VAL_ 737 VCFRONT_wiperState 9 "WIPER_STATE_CONT_FAST" 10 "WIPER_STATE_CONT_SLOW" 3 "WIPER_STATE_DELAYED_REST" 2 "WIPER_STATE_FAULT" 7 "WIPER_STATE_INTERMITTENT_HIGH" 8 "WIPER_STATE_INTERMITTENT_LOW" 12 "WIPER_STATE_INT_AUTO_HIGH" 11 "WIPER_STATE_INT_AUTO_LOW" 6 "WIPER_STATE_MOMENTARY_WIPE" 4 "WIPER_STATE_PARK" 1 "WIPER_STATE_SERVICE" 0 "WIPER_STATE_SNA" 5 "WIPER_STATE_WASH" ;
VAL_ 897 VCFRONT_logging1HzIndex 18 "BODY_CONTROL" 0 "COOLANT" 19 "COOLANT_2" 2 "COOLANT_VALVE" 20 "END" 1 "FAN_DEMAND_CONDENSER_AND_FET_TEMPS" 3 "HCML_LED_TEMPS" 4 "HCMR_LED_TEMPS" 6 "HEADLAMP_AIM" 5 "HOMELINK" 15 "HP_ARBITRATION" 9 "HP_CONTROL_LOOP_AND_STATE" 10 "HP_CYCLE_MODEL" 8 "HP_DATA_AND_ACCUMULATORS" 12 "HP_DISSIPATION_AND_POWER" 11 "HP_EXV_CALIBRATION" 7 "HP_EXV_RANGE" 17 "HP_MODE_OPTIONS_AND_ESTIMATES" 16 "HP_MODE_SELECT_AND_ESTIMATES" 14 "HP_PRESSURE_CONTROL" 13 "HP_TEMPS_AND_DEMANDS" ;
VAL_ 897 VCFRONT_HCML_bladeTemp 128 "SNA" ;
VAL_ 897 VCFRONT_HCML_diffuseTemp 128 "SNA" ;
VAL_ 897 VCFRONT_HCML_highBeamTemp 128 "SNA" ;
VAL_ 897 VCFRONT_HCML_lowBeamSpotTemp 128 "SNA" ;
VAL_ 897 VCFRONT_HCML_turnTemp 128 "SNA" ;
VAL_ 897 VCFRONT_HCMR_bladeTemp 128 "SNA" ;
VAL_ 897 VCFRONT_HCMR_diffuseTemp 128 "SNA" ;
VAL_ 897 VCFRONT_HCMR_highBeamTemp 128 "SNA" ;
VAL_ 897 VCFRONT_HCMR_lowBeamSpotTemp 128 "SNA" ;
VAL_ 897 VCFRONT_HCMR_turnTemp 128 "SNA" ;
VAL_ 897 VCFRONT_coolantValveCountRange 1023 "SNA" ;
VAL_ 897 VCFRONT_coolantValveRadBypass 127 "SNA" ;
VAL_ 897 VCFRONT_coolantValveRecalReason 3 "CALIBRATION_FAULT_NO_TRAVEL" 2 "GENERAL_FAULT" 1 "MAX_TRAVEL" 5 "MOTOR_FEEDBACK_INTERRUPTED" 6 "NVRAM_LOSS" 4 "SELF_TEST" 7 "SYSTEM_LEVEL_FAULT_RESPONSE" 0 "UNDEFINED" ;
VAL_ 897 VCFRONT_drlMode 2 "DRL_MODE_DRL" 0 "DRL_MODE_OFF" 1 "DRL_MODE_POSITION" ;
VAL_ 897 VCFRONT_homelinkRegionCode 5 "HOMELINK_REGION_CODE_AMERICAS" 9 "HOMELINK_REGION_CODE_CHINA" 1 "HOMELINK_REGION_CODE_EUROPE" 8 "HOMELINK_REGION_CODE_REST_OF_WORLD" 0 "HOMELINK_REGION_CODE_UNKNOWN" ;
VAL_ 897 VCFRONT_hpMode 2 "AMBIENT_SOURCE" 15 "BATTERY_COOL" 17 "BATTERY_COOL_CABIN_CONDENSER" 16 "BATTERY_COOL_CABIN_CONDENSER_REHEAT" 18 "BATTERY_COOL_CABIN_REHEAT" 19 "BATTERY_COOL_EVAPORATOR" 13 "BATTERY_HEAT_AMBIENT_SOURCE" 14 "BATTERY_HEAT_COP1" 11 "CABIN_COOL_EVAPORATOR" 12 "CABIN_COOL_EVAPORATOR_REHEAT" 4 "CABIN_HEAT_AMBIENT_SOURCE" 10 "CABIN_HEAT_BATTERY_COOL_REHEAT" 9 "CABIN_HEAT_BATTERY_HEAT_REHEAT_AMBIENT_SOURCE" 7 "CABIN_HEAT_BLEND" 8 "CABIN_HEAT_COP1" 6 "CABIN_HEAT_REHEAT_AMBIENT_SOURCE" 5 "CABIN_HEAT_REHEAT_SCAVENGE" 3 "CABIN_HEAT_SCAVENGE_ONLY" 1 "GENERAL" 0 "NONE" ;
VAL_ 897 VCFRONT_hpRefrigerantPurgeState 2 "COMPLETE" 1 "EVAP_PURGE" 0 "IDLE" ;
VAL_ 897 VCFRONT_modeDesired 3 "AMBIENT_SOURCE" 2 "BLEND" 1 "PARALLEL" 0 "SERIES" ;
VAL_ 897 VCFRONT_modeTransitionID 23 "ENTER_AMBIENTSOURCE" 24 "EXIT_AMBIENTSOURCE" 20 "INIT" 21 "OVERRIDE" 6 "PARALLEL_2_drive_batteryWantsHeat" 7 "PARALLEL_3_drive_batteryWantsCool" 8 "PARALLEL_4_drive_batteryNeedsCool" 11 "PARALLEL_5_charge_batteryWantsHeat" 12 "PARALLEL_6_charge_batteryWantsCool" 15 "PARALLEL_7_fastCharge_batteryWantsCool" 16 "PARALLEL_8_fastCharge_batteryWantsHeat" 19 "PARALLEL_9_drive_batteryThermalLimiting" 0 "PARALLEL_F1_noFlowRequest" 33 "PAR_1_drive_battNeedsActiveCooling_evapDisabled" 34 "PAR_2_drive_ptNeedsActiveCooling" 35 "PAR_3_drive_chillerPassivelyCoolsBatt" 36 "PAR_4_drive_cannotPassivelyCoolBatt" 37 "PAR_5_drive_battAboveHotStagnationTemp" 38 "PAR_6_FC_battNeedsActiveCooling_evapDisabled" 39 "PAR_7_FC_battNeedsActiveCooling_evapEnabled" 40 "PAR_8_charge_battAbovePassiveTarget" 3 "SERIES_1_drive_batteryWantsCool" 4 "SERIES_2_drive_batteryNeedsHeat" 5 "SERIES_3_drive_batteryWantsHeat" 9 "SERIES_4_charge_batteryNeedsHeat" 10 "SERIES_5_charge_batteryWantsHeat" 13 "SERIES_6_fastCharge_batteryNeedsHeat" 14 "SERIES_7_fastCharge_batteryWantsCool" 17 "SERIES_8_preConditioning_batteryNeedsHeat" 18 "SERIES_9_drive_driveUnitThermalLimiting" 1 "SERIES_F2_faultPumps" 2 "SERIES_F3_faultTempSensors" 25 "SER_1_drive_battNeedsActiveCooling_evapEnabled" 26 "SER_2_drive_battBelowHotStagnationTemp" 27 "SER_3_drive_chillerPassivelyCools" 28 "SER_4_drive_radPassivelyCoolsBatt" 29 "SER_5_FC_battHeatingNeeded" 30 "SER_6_FC_battNeedsActiveCooling_evapDisabled" 31 "SER_7_FC_battNeedsActiveCooling_evapEnabled" 32 "SER_8_charge_battBelowPassiveTarget" 22 "UNDEFINED" ;
VAL_ 897 VCFRONT_passiveCoolingState 3 "CannotCoolBattery" 2 "ChillerAndRadCoolSeriesLoop" 1 "ChillerCoolsParallelBattLoop" 0 "ChillerCoolsSeriesLoop" ;
VAL_ 897 VCFRONT_pumpBatteryFETTemp 255 "SNA" ;
VAL_ 897 VCFRONT_pumpPowertrainFETTemp 255 "SNA" ;
VAL_ 897 VCFRONT_radiatorFanFETTemp 255 "SNA" ;
VAL_ 897 VCFRONT_radiatorFanRunReason 1 "ACTIVE_MANAGER" 2 "AMBIENT_SNIFF" 5 "COAST_MODE" 4 "HEAT_PUMP" 6 "MIN_ON_GLOBAL" 7 "MIN_ON_NVH" 0 "NONE" 3 "NVH_MASKING" 8 "UDS" ;
VAL_ 897 VCFRONT_tempRefrigSuction 255 "SNA" ;
VAL_ 553 GearLeverPosition229 4 "Full Up" 3 "Half Up" 2 "Full Down" 1 "Half Down" 0 "Center" ;
VAL_ 585 SCCM_highBeamStalkStatus 0 "IDLE" 1 "PULL" 2 "PUSH" 3 "SNA" ;
VAL_ 585 SCCM_turnIndicatorStalkStatus 5 "DOWN_0_5" 6 "DOWN_1" 7 "DOWN_1_5" 8 "DOWN_2" 0 "IDLE" 9 "SNA" 1 "UP_0_5" 2 "UP_1" 3 "UP_1_5" 4 "UP_2" ;
VAL_ 585 SCCM_washWipeButtonStatus 1 "1ST_DETENT" 2 "2ND_DETENT" 0 "NOT_PRESSED" 3 "SNA" ;
VAL_ 390 DIF_axleSpeed 32768 "SNA" ;
VAL_ 390 DIF_slavePedalPos 255 "SNA" ;
VAL_ 390 DIF_torqueActual 4096 "SNA" ;
VAL_ 390 DIF_torqueCommand 4096 "SNA" ;
VAL_ 918 FrontOilPumpState396 7 "OIL_PUMP_SNA" 6 "OIL_PUMP_FAULTED" 2 "OIL_PUMP_COLD_STARTUP" 1 "OIL_PUMP_ENABLE" 0 "OIL_PUMP_STANDBY" ;
VAL_ 917 DIR_oilPumpFluidTQF 1 "OIL_PUMP_FLUIDT_HIGH_CONFIDENCE" 0 "OIL_PUMP_FLUIDT_LOW_CONFIDENCE" ;
VAL_ 917 DIR_oilPumpState 2 "OIL_PUMP_COLD_STARTUP" 1 "OIL_PUMP_ENABLE" 6 "OIL_PUMP_FAULTED" 7 "OIL_PUMP_SNA" 0 "OIL_PUMP_STANDBY" ;
VAL_ 341 ESP_WheelRotationReR 3 "WR_NOT_DEFINABLE" 2 "WR_STANDSTILL" 1 "WR_BACKWARD" 0 "WR_FORWARD" ;
VAL_ 341 ESP_WheelRotationReL 3 "WR_NOT_DEFINABLE" 2 "WR_STANDSTILL" 1 "WR_BACKWARD" 0 "WR_FORWARD" ;
VAL_ 341 ESP_WheelRotationFrR 3 "WR_NOT_DEFINABLE" 2 "WR_STANDSTILL" 1 "WR_BACKWARD" 0 "WR_FORWARD" ;
VAL_ 341 ESP_WheelRotationFrL 3 "WR_NOT_DEFINABLE" 2 "WR_STANDSTILL" 1 "WR_BACKWARD" 0 "WR_FORWARD" ;
VAL_ 341 ESP_wheelSpeedsQF 1 "ALL_WSS_VALID" 0 "ONE_OR_MORE_WSS_INVALID" ;
VAL_ 341 ESP_vehicleStandstillSts 1 "STANDSTILL" 0 "NOT_STANDSTILL" ;
VAL_ 341 ESP_vehicleSpeed 1023 "ESP_VEHICLE_SPEED_SNA" ;
VAL_ 373 WheelSpeedRR175 8191 "SNA" ;
VAL_ 373 WheelSpeedRL175 8191 "SNA" ;
VAL_ 373 WheelSpeedFR175 8191 "SNA" ;
VAL_ 373 WheelSpeedFL175 8191 "SNA" ;
VAL_ 389 ESP_brakeTorqueFrL 4095 "SNA" ;
VAL_ 389 ESP_brakeTorqueFrR 4095 "SNA" ;
VAL_ 389 ESP_brakeTorqueReL 4095 "SNA" ;
VAL_ 389 ESP_brakeTorqueReR 4095 "SNA" ;
VAL_ 389 ESP_brakeTorqueQF 1 "IN_SPEC" 0 "UNDEFINABLE_ACCURACY" ;
VAL_ 962 VCLEFT_switchStatusIndex 0 "VCLEFT_SWITCH_STATUS_INDEX_0" 1 "VCLEFT_SWITCH_STATUS_INDEX_1" 2 "VCLEFT_SWITCH_STATUS_INDEX_INVALID" ;
VAL_ 962 VCLEFT_frontBuckleSwitch 3 "SWITCH_FAULT" 1 "SWITCH_OFF" 2 "SWITCH_ON" 0 "SWITCH_SNA" ;
VAL_ 962 VCLEFT_frontOccupancySwitch 3 "SWITCH_FAULT" 1 "SWITCH_OFF" 2 "SWITCH_ON" 0 "SWITCH_SNA" ;
VAL_ 962 VCLEFT_frontSeatBackrestBack 3 "SWITCH_FAULT" 1 "SWITCH_OFF" 2 "SWITCH_ON" 0 "SWITCH_SNA" ;
VAL_ 962 VCLEFT_frontSeatBackrestForward 3 "SWITCH_FAULT" 1 "SWITCH_OFF" 2 "SWITCH_ON" 0 "SWITCH_SNA" ;
VAL_ 962 VCLEFT_frontSeatLiftDown 3 "SWITCH_FAULT" 1 "SWITCH_OFF" 2 "SWITCH_ON" 0 "SWITCH_SNA" ;
VAL_ 962 VCLEFT_frontSeatLiftUp 3 "SWITCH_FAULT" 1 "SWITCH_OFF" 2 "SWITCH_ON" 0 "SWITCH_SNA" ;
VAL_ 962 VCLEFT_frontSeatLumbarDown 3 "SWITCH_FAULT" 1 "SWITCH_OFF" 2 "SWITCH_ON" 0 "SWITCH_SNA" ;
VAL_ 962 VCLEFT_frontSeatLumbarIn 3 "SWITCH_FAULT" 1 "SWITCH_OFF" 2 "SWITCH_ON" 0 "SWITCH_SNA" ;
VAL_ 962 VCLEFT_frontSeatLumbarOut 3 "SWITCH_FAULT" 1 "SWITCH_OFF" 2 "SWITCH_ON" 0 "SWITCH_SNA" ;
VAL_ 962 VCLEFT_frontSeatLumbarUp 3 "SWITCH_FAULT" 1 "SWITCH_OFF" 2 "SWITCH_ON" 0 "SWITCH_SNA" ;
VAL_ 962 VCLEFT_frontSeatTiltDown 3 "SWITCH_FAULT" 1 "SWITCH_OFF" 2 "SWITCH_ON" 0 "SWITCH_SNA" ;
VAL_ 962 VCLEFT_frontSeatTiltUp 3 "SWITCH_FAULT" 1 "SWITCH_OFF" 2 "SWITCH_ON" 0 "SWITCH_SNA" ;
VAL_ 962 VCLEFT_frontSeatTrackBack 3 "SWITCH_FAULT" 1 "SWITCH_OFF" 2 "SWITCH_ON" 0 "SWITCH_SNA" ;
VAL_ 962 VCLEFT_frontSeatTrackForward 3 "SWITCH_FAULT" 1 "SWITCH_OFF" 2 "SWITCH_ON" 0 "SWITCH_SNA" ;
VAL_ 962 VCLEFT_rearCenterBuckleSwitch 3 "SWITCH_FAULT" 1 "SWITCH_OFF" 2 "SWITCH_ON" 0 "SWITCH_SNA" ;
VAL_ 962 VCLEFT_rearCenterOccupancySwitch 3 "SWITCH_FAULT" 1 "SWITCH_OFF" 2 "SWITCH_ON" 0 "SWITCH_SNA" ;
VAL_ 962 VCLEFT_rearLeftBuckleSwitch 3 "SWITCH_FAULT" 1 "SWITCH_OFF" 2 "SWITCH_ON" 0 "SWITCH_SNA" ;
VAL_ 962 VCLEFT_rearLeftOccupancySwitch 3 "SWITCH_FAULT" 1 "SWITCH_OFF" 2 "SWITCH_ON" 0 "SWITCH_SNA" ;
VAL_ 962 VCLEFT_rearRightOccupancySwitch 3 "SWITCH_FAULT" 1 "SWITCH_OFF" 2 "SWITCH_ON" 0 "SWITCH_SNA" ;
VAL_ 962 VCLEFT_rightMirrorTilt 1 "MIRROR_TILT_DOWN" 4 "MIRROR_TILT_LEFT" 3 "MIRROR_TILT_RIGHT" 0 "MIRROR_TILT_STOP" 2 "MIRROR_TILT_UP" ;
VAL_ 962 VCLEFT_swcLeftPressed 3 "SWITCH_FAULT" 1 "SWITCH_OFF" 2 "SWITCH_ON" 0 "SWITCH_SNA" ;
VAL_ 962 VCLEFT_swcLeftTiltLeft 3 "SWITCH_FAULT" 1 "SWITCH_OFF" 2 "SWITCH_ON" 0 "SWITCH_SNA" ;
VAL_ 962 VCLEFT_swcLeftTiltRight 3 "SWITCH_FAULT" 1 "SWITCH_OFF" 2 "SWITCH_ON" 0 "SWITCH_SNA" ;
VAL_ 962 VCLEFT_swcRightPressed 3 "SWITCH_FAULT" 1 "SWITCH_OFF" 2 "SWITCH_ON" 0 "SWITCH_SNA" ;
VAL_ 962 VCLEFT_swcRightTiltLeft 3 "SWITCH_FAULT" 1 "SWITCH_OFF" 2 "SWITCH_ON" 0 "SWITCH_SNA" ;
VAL_ 962 VCLEFT_swcRightTiltRight 3 "SWITCH_FAULT" 1 "SWITCH_OFF" 2 "SWITCH_ON" 0 "SWITCH_SNA" ;
VAL_ 822 DI_performancePackage 0 "BASE" 3 "BASE_PLUS" 1 "PERFORMANCE" 4 "SNA" ;
VAL_ 659 UI_accOvertakeEnable 0 "ACC_OVERTAKE_OFF" 1 "ACC_OVERTAKE_ON" 3 "SNA" ;
VAL_ 659 UI_aebEnable 0 "AEB_OFF" 1 "AEB_ON" 3 "SNA" ;
VAL_ 659 UI_aesEnable 0 "AES_OFF" 1 "AES_ON" 3 "SNA" ;
VAL_ 659 UI_ahlbEnable 0 "AHLB_OFF" 1 "AHLB_ON" 3 "SNA" ;
VAL_ 659 UI_autoLaneChangeEnable 0 "OFF" 1 "ON" 3 "SNA" ;
VAL_ 659 UI_autoParkRequest 7 "ABORT" 8 "COMPLETE" 0 "NONE" 5 "PARALLEL_PULL_OUT_TO_LEFT" 6 "PARALLEL_PULL_OUT_TO_RIGHT" 2 "PARK_LEFT_CROSS" 1 "PARK_LEFT_PARALLEL" 4 "PARK_RIGHT_CROSS" 3 "PARK_RIGHT_PARALLEL" 10 "PAUSE" 11 "RESUME" 9 "SEARCH" 15 "SNA" ;
VAL_ 659 UI_bsdEnable 0 "BSD_OFF" 1 "BSD_ON" 3 "SNA" ;
VAL_ 659 UI_distanceUnits 0 "DISTANCEUNITS_KM" 1 "DISTANCEUNITS_MILES" ;
VAL_ 659 UI_fcwEnable 0 "FCW_OFF" 1 "FCW_ON" 3 "SNA" ;
VAL_ 659 UI_fcwSensitivity 1 "AEB_SENSITIVITY_AVERAGE" 0 "AEB_SENSITIVITY_EARLY" 2 "AEB_SENSITIVITY_LATE" 3 "SNA" ;
VAL_ 659 UI_latControlEnable 0 "LATERAL_CONTROL_OFF" 1 "LATERAL_CONTROL_ON" 3 "LATERAL_CONTROL_SNA" 2 "LATERAL_CONTROL_UNAVAILABLE" ;
VAL_ 659 UI_ldwEnable 1 "LDW_TRIGGERS_HAPTIC" 0 "NO_HAPTIC" 3 "SNA" ;
VAL_ 659 UI_parkBrakeRequest 0 "PARK_BRAKE_REQUEST_IDLE" 1 "PARK_BRAKE_REQUEST_PRESSED" 3 "PARK_BRAKE_REQUEST_SNA" ;
VAL_ 659 UI_pedalSafetyEnable 0 "PEDAL_SAFETY_OFF" 1 "PEDAL_SAFETY_ON" 3 "SNA" ;
VAL_ 659 UI_redLightStopSignEnable 0 "RLSSW_OFF" 1 "RLSSW_ON" 3 "SNA" ;
VAL_ 659 UI_selfParkTune 15 "SNA" ;
VAL_ 659 UI_steeringTuneRequest 0 "STEERING_TUNE_COMFORT" 2 "STEERING_TUNE_SPORT" 1 "STEERING_TUNE_STANDARD" ;
VAL_ 659 UI_tractionControlMode 2 "TC_DEV_MODE_1_SELECTED" 3 "TC_DEV_MODE_2_SELECTED" 5 "TC_DYNO_MODE_SELECTED" 0 "TC_NORMAL_SELECTED" 6 "TC_OFFROAD_ASSIST_SELECTED" 4 "TC_ROLLS_MODE_SELECTED" 1 "TC_SLIP_START_SELECTED" ;
VAL_ 659 UI_trailerMode 0 "TRAILER_MODE_OFF" 1 "TRAILER_MODE_ON" ;
VAL_ 659 UI_winchModeRequest 1 "WINCH_MODE_ENTER" 2 "WINCH_MODE_EXIT" 0 "WINCH_MODE_IDLE" ;
VAL_ 659 UI_zeroSpeedConfirmed 0 "ZERO_SPEED_CANCELED" 1 "ZERO_SPEED_CONFIRMED" 3 "ZERO_SPEED_SNA" 2 "ZERO_SPEED_UNUSED" ;
VAL_ 616 DI_primaryUnitSiliconType 1 "IGBT" 0 "MOSFET" ;
VAL_ 532 FC_postID 2 "FC_POST_ID_2" 3 "FC_POST_ID_SNA" 0 "FC_POST_MASTER" 1 "FC_POST_SLAVE" ;
VAL_ 532 FC_statusCode 3 "FC_STATUS_DEPRECATED_3" 4 "FC_STATUS_DEPRECATED_4" 6 "FC_STATUS_EXT_ISOACTIVE" 5 "FC_STATUS_INT_ISOACTIVE" 14 "FC_STATUS_MALFUNCTION" 15 "FC_STATUS_NODATA" 13 "FC_STATUS_NOTCOMPATIBLE" 0 "FC_STATUS_NOTREADY_SNA" 7 "FC_STATUS_POST_OUT_OF_SERVICE" 1 "FC_STATUS_READY" 2 "FC_STATUS_UPDATE_IN_PROGRESS" ;
VAL_ 532 FC_type 3 "FC_TYPE_CC_EVSE" 1 "FC_TYPE_CHADEMO" 4 "FC_TYPE_COMBO" 2 "FC_TYPE_GB" 5 "FC_TYPE_MC_EVSE" 6 "FC_TYPE_OTHER" 7 "FC_TYPE_SNA" 0 "FC_TYPE_SUPERCHARGER" ;
VAL_ 535 FC_status3DataSelect 0 "Mux0" 1 "Mux1" ;
VAL_ 535 FC_brand 0 "FC_BRAND_SNA" 1 "FC_BRAND_TESLA" ;
VAL_ 535 FC_class 0 "FC_CLASS_SNA" 1 "FC_CLASS_SUPERCHARGER" 2 "FC_CLASS_URBANCHARGER" ;
VAL_ 535 FC_coolingType 2 "FC_COOLING_TYPE_CONVECTION" 1 "FC_COOLING_TYPE_LIQUID" 0 "FC_COOLING_TYPE_SNA" ;
VAL_ 535 FC_generation 0 "GENERATION_SNA" ;
VAL_ 535 FC_uiStopType 2 "FC_UI_STOP_TYPE_MOMENTARY" 0 "FC_UI_STOP_TYPE_SNA" 1 "FC_UI_STOP_TYPE_TOGGLE" ;
VAL_ 801 VCFRONT_brakeFluidLevel 1 "LOW" 2 "NORMAL" 0 "SNA" ;
VAL_ 801 VCFRONT_coolantLevel 1 "FILLED" 0 "NOT_OK" ;
VAL_ 801 VCFRONT_tempAmbient 0 "SNA" ;
VAL_ 801 VCFRONT_tempAmbientFiltered 0 "SNA" ;
VAL_ 801 VCFRONT_tempCoolantBatInlet 1023 "SNA" ;
VAL_ 801 VCFRONT_tempCoolantPTInlet 2047 "SNA" ;
VAL_ 801 VCFRONT_washerFluidLevel 1 "LOW" 2 "NORMAL" 0 "SNA" ;
VAL_ 769 VCFRONT_infoIndex 13 "BC_INFO_APP_CRC" 17 "BC_INFO_APP_GITHASH" 15 "BC_INFO_BOOTLOADER_CRC" 18 "BC_INFO_BOOTLOADER_GITHASH" 14 "BC_INFO_BOOTLOADER_SVN" 10 "BC_INFO_BUILD_HWID_COMPONENTID" 0 "BC_INFO_DEPRECATED_0" 1 "BC_INFO_DEPRECATED_1" 2 "BC_INFO_DEPRECATED_2" 3 "BC_INFO_DEPRECATED_3" 4 "BC_INFO_DEPRECATED_4" 5 "BC_INFO_DEPRECATED_5" 6 "BC_INFO_DEPRECATED_6" 7 "BC_INFO_DEPRECATED_7" 8 "BC_INFO_DEPRECATED_8" 9 "BC_INFO_DEPRECATED_9" 255 "BC_INFO_END" 11 "BC_INFO_PCBAID_ASSYID_USAGEID" 16 "BC_INFO_SUBCOMPONENT1" 23 "BC_INFO_SUBCOMPONENT2" 24 "BC_INFO_SUBCOMPONENT3" 31 "BC_INFO_SUBCOMPONENT4" 32 "BC_INFO_SUBCOMPONENT5" 33 "BC_INFO_SUBCOMPONENT6" 20 "BC_INFO_UDS_PROTOCOL_BOOTCRC" 19 "BC_INFO_VERSION_DEPRECATED" ;
VAL_ 769 VCFRONT_infoAssemblyId 1 "ASSEMBLY1" 255 "ASSEMBLY_SNA" ;
VAL_ 769 VCFRONT_infoBuildType 2 "INFO_LOCAL_BUILD" 4 "INFO_MFG_BUILD" 1 "INFO_PLATFORM_BUILD" 3 "INFO_TRACEABLE_CI_BUILD" 0 "INFO_UNKNOWN_BUILD" ;
VAL_ 513 VCFRONT_loggingAndVitals10HzInde 7 "END" 3 "EXV_FLOW" 5 "EXV_FLOW_TARGET" 6 "EXV_STATE" 4 "HP_STATE" 2 "STATES_AND_SENSORS" 0 "TARGETS_AND_ACTUALS_0" 1 "TARGETS_SENSORS_AND_ACTUALS_1" ;
VAL_ 513 VCFRONT_cclExvState 8 "CALIB_CLOSE" 9 "CALIB_CLOSE_OVERDRIVE" 4 "FAULTED" 2 "INIT_CLOSE" 1 "INIT_OPEN" 6 "OVERDRIVING_SHUT" 3 "READY" 7 "READY_SHUT" 0 "UNINIT" 5 "WAIT" ;
VAL_ 513 VCFRONT_ccrExvState 8 "CALIB_CLOSE" 9 "CALIB_CLOSE_OVERDRIVE" 4 "FAULTED" 2 "INIT_CLOSE" 1 "INIT_OPEN" 6 "OVERDRIVING_SHUT" 3 "READY" 7 "READY_SHUT" 0 "UNINIT" 5 "WAIT" ;
VAL_ 513 VCFRONT_chillerExvState 8 "CALIB_CLOSE" 9 "CALIB_CLOSE_OVERDRIVE" 4 "FAULTED" 2 "INIT_CLOSE" 1 "INIT_OPEN" 6 "OVERDRIVING_SHUT" 3 "READY" 7 "READY_SHUT" 0 "UNINIT" 5 "WAIT" ;
VAL_ 513 VCFRONT_compressorState 3 "FAULT" 1 "READY" 2 "RUNNING" 0 "STANDBY" ;
VAL_ 513 VCFRONT_coolantValveMode 3 "AMBIENT_SOURCE" 2 "BLEND" 1 "PARALLEL" 0 "SERIES" ;
VAL_ 513 VCFRONT_evapExvState 8 "CALIB_CLOSE" 9 "CALIB_CLOSE_OVERDRIVE" 4 "FAULTED" 2 "INIT_CLOSE" 1 "INIT_OPEN" 6 "OVERDRIVING_SHUT" 3 "READY" 7 "READY_SHUT" 0 "UNINIT" 5 "WAIT" ;
VAL_ 513 VCFRONT_exvState 8 "CALIB_CLOSE" 9 "CALIB_CLOSE_OVERDRIVE" 4 "FAULTED" 2 "INIT_CLOSE" 1 "INIT_OPEN" 6 "OVERDRIVING_SHUT" 3 "READY" 7 "READY_SHUT" 0 "UNINIT" 5 "WAIT" ;
VAL_ 513 VCFRONT_hpBatteryLoadType 2 "BATT_COOL" 1 "BATT_HEAT" 0 "NONE" ;
VAL_ 513 VCFRONT_hpBlendType 2 "HP_FULL" 0 "HP_NONE" 1 "HP_PARTIAL" ;
VAL_ 513 VCFRONT_hpCabinLoadType 1 "CC" 3 "EVAP" 0 "NONE" 2 "REHEAT" ;
VAL_ 513 VCFRONT_hpDominantLoad 5 "CC" 2 "CHILLER" 1 "EVAP" 6 "HIGH_BOTH" 4 "LCC" 3 "LOW_BOTH" 0 "NONE" ;
VAL_ 513 VCFRONT_hpHighSideHX 3 "BOTH" 2 "CC" 1 "LCC" 0 "NONE" ;
VAL_ 513 VCFRONT_hpLowSideHX 3 "BOTH" 1 "CHILLER" 2 "EVAP" 0 "NONE" ;
VAL_ 513 VCFRONT_hpReqCoolantMode 4 "AMBIENT_SOURCE" 0 "ANY" 3 "PARALLEL" 2 "SERIES_BYPASS" 1 "SERIES_NO_BYPASS" ;
VAL_ 513 VCFRONT_lccExvState 8 "CALIB_CLOSE" 9 "CALIB_CLOSE_OVERDRIVE" 4 "FAULTED" 2 "INIT_CLOSE" 1 "INIT_OPEN" 6 "OVERDRIVING_SHUT" 3 "READY" 7 "READY_SHUT" 0 "UNINIT" 5 "WAIT" ;
VAL_ 513 VCFRONT_pressureRefrigDischargeV 255 "SNA" ;
VAL_ 513 VCFRONT_pressureRefrigLiquid 255 "SNA" ;
VAL_ 513 VCFRONT_pressureRefrigSuctionVit 127 "SNA" ;
VAL_ 513 VCFRONT_pumpBatteryRPMActual 1023 "SNA" ;
VAL_ 513 VCFRONT_pumpPowertrainRPMActual 1023 "SNA" ;
VAL_ 513 VCFRONT_radiatorFanRPMActual 1023 "SNA" ;
VAL_ 513 VCFRONT_recircExvState 8 "CALIB_CLOSE" 9 "CALIB_CLOSE_OVERDRIVE" 4 "FAULTED" 2 "INIT_CLOSE" 1 "INIT_OPEN" 6 "OVERDRIVING_SHUT" 3 "READY" 7 "READY_SHUT" 0 "UNINIT" 5 "WAIT" ;
VAL_ 513 VCFRONT_solenoidEvapState 2 "CLOSED" 3 "FAULTED" 1 "OPENED" 0 "UNDEFINED" ;
VAL_ 513 VCFRONT_tempRefrigDischarge 2047 "SNA" ;
VAL_ 513 VCFRONT_tempRefrigLiquid 2047 "SNA" ;
VAL_ 513 VCFRONT_tempSuperheatActual 1023 "SNA" ;
VAL_ 609 VCFRONT_batterySMState 0 "INIT" 1 "CHARGE" 2 "DISCHARGE" 3 "STANDBY" 4 "RESISTANCE_ESTIMATION" 5 "OTA_STANDBY" 6 "DISCONNECTED_BATTERY_TEST" 7 "SHORTED_CELL_TEST" 8 "FAULT" 9 "RECOVERY" ;
VAL_ 609 VCFRONT_voltageProfile 0 "CHARGE" 1 "FLOAT" 2 "REDUCED_FLOAT" 3 "ALWAYS_CLOSED_CONTACTORS" ;
VAL_ 548 DCDCstate224 6 "Error" 5 "Shutdown" 4 "HVactive" 3 "Precharge" 2 "PrechargeStart" 1 "12vChg" 0 "Idle" ;
VAL_ 548 DCDCSubState224 0 "PWR_UP_INIT" 1 "STANDBY" 2 "12V_SUPPORT_ACTIVE" 3 "DIS_HVBUS" 4 "PCHG_FAST_DIS_HVBUS" 5 "PCHG_SLOW_DIS_HVBUS" 6 "PCHG_DWELL_CHARGE" 7 "PCHG_DWELL_WAIT" 8 "PCHG_DI_RECOVERY_WAIT" 9 "PCHG_ACTIVE" 10 "PCHG_FLT_FAST_DIS_HVBUS" 11 "SHUTDOWN" 12 "12V_SUPPORT_FAULTED" 13 "DIS_HVBUS_FAULTED" 14 "PCHG_FAULTED" 15 "CLEAR_FAULTS" 16 "FAULTED" 17 "NUM" ;
VAL_ 551 CMP_state 3 "CMP_STATE_FAULT" 0 "CMP_STATE_NONE" 1 "CMP_STATE_NORMAL" 15 "CMP_STATE_SNA" 5 "CMP_STATE_SOFT_SHUTDOWN" 4 "CMP_STATE_SOFT_START" 2 "CMP_STATE_WAIT" ;
VAL_ 280 DI_accelPedalPos 255 "SNA" ;
VAL_ 280 DI_brakePedalState 2 "INVALID" 0 "OFF" 1 "ON" ;
VAL_ 280 DI_driveBlocked 1 "DRIVE_BLOCKED_FRUNK" 0 "DRIVE_BLOCKED_NONE" 2 "DRIVE_BLOCKED_PROX" ;
VAL_ 280 DI_epbRequest 0 "DI_EPBREQUEST_NO_REQUEST" 1 "DI_EPBREQUEST_PARK" 2 "DI_EPBREQUEST_UNPARK" ;
VAL_ 280 DI_gear 4 "DI_GEAR_D" 0 "DI_GEAR_INVALID" 3 "DI_GEAR_N" 1 "DI_GEAR_P" 2 "DI_GEAR_R" 7 "DI_GEAR_SNA" ;
VAL_ 280 DI_immobilizerState 2 "DI_IMM_STATE_AUTHENTICATING" 3 "DI_IMM_STATE_DISARMED" 6 "DI_IMM_STATE_FAULT" 4 "DI_IMM_STATE_IDLE" 0 "DI_IMM_STATE_INIT_SNA" 1 "DI_IMM_STATE_REQUEST" 5 "DI_IMM_STATE_RESET" ;
VAL_ 280 DI_keepDrivePowerStateRequest 1 "KEEP_ALIVE" 0 "NO_REQUEST" ;
VAL_ 280 DI_systemState 4 "DI_SYS_ABORT" 5 "DI_SYS_ENABLE" 3 "DI_SYS_FAULT" 1 "DI_SYS_IDLE" 2 "DI_SYS_STANDBY" 0 "DI_SYS_UNAVAILABLE" ;
VAL_ 280 DI_trackModeState 1 "TRACK_MODE_AVAILABLE" 2 "TRACK_MODE_ON" 0 "TRACK_MODE_UNAVAILABLE" ;
VAL_ 280 DI_tractionControlMode 6 "Offroad Assist" 5 "Dyno Mode" 4 "Rolls Mode" 3 "Dev2" 2 "Dev1" 1 "Slip Start" 0 "Standard" ;
VAL_ 850 BMS_energyBuffer 255 "SNA" ;
VAL_ 850 BMS_energyToChargeComplete 2047 "SNA" ;
VAL_ 850 BMS_expectedEnergyRemaining 2047 "SNA" ;
VAL_ 850 BMS_idealEnergyRemaining 2047 "SNA" ;
VAL_ 850 BMS_nominalEnergyRemaining 2047 "SNA" ;
VAL_ 850 BMS_nominalFullPackEnergy 2047 "SNA" ;
VAL_ 914 BMS_packConfigMultiplexer 0 "Mux0" 1 "Mux1" ;
VAL_ 914 BMS_moduleType 0 "UNKNOWN" 1 "E3_NCT" 2 "E1_NCT" 3 "E3_CT" 4 "E1_CT" 5 "E1_CP" ;
VAL_ 914 BMS_reservedConfig_0 0 "BMS_CONFIG_0" 1 "BMS_CONFIG_1" 10 "BMS_CONFIG_10" 11 "BMS_CONFIG_11" 12 "BMS_CONFIG_12" 13 "BMS_CONFIG_13" 14 "BMS_CONFIG_14" 15 "BMS_CONFIG_15" 16 "BMS_CONFIG_16" 17 "BMS_CONFIG_17" 18 "BMS_CONFIG_18" 19 "BMS_CONFIG_19" 2 "BMS_CONFIG_2" 20 "BMS_CONFIG_20" 21 "BMS_CONFIG_21" 22 "BMS_CONFIG_22" 23 "BMS_CONFIG_23" 24 "BMS_CONFIG_24" 25 "BMS_CONFIG_25" 26 "BMS_CONFIG_26" 27 "BMS_CONFIG_27" 28 "BMS_CONFIG_28" 29 "BMS_CONFIG_29" 3 "BMS_CONFIG_3" 30 "BMS_CONFIG_30" 31 "BMS_CONFIG_31" 4 "BMS_CONFIG_4" 5 "BMS_CONFIG_5" 6 "BMS_CONFIG_6" 7 "BMS_CONFIG_7" 8 "BMS_CONFIG_8" 9 "BMS_CONFIG_9" ;
VAL_ 594 BMS_powerLimitsState 1 "POWER_CALCULATED_FOR_DRIVE" 0 "POWER_NOT_CALCULATED_FOR_DRIVE" ;
VAL_ 658 BattBeginningOfLifeEnergy292 1023 "SNA" ;
VAL_ 658 BMS_battTempPct 255 "SNA" ;
VAL_ 599 DI_uiSpeed 511 "DI_UI_SPEED_SNA" ;
VAL_ 599 DI_uiSpeedHighSpeed 511 "DI_UI_HIGH_SPEED_SNA" ;
VAL_ 599 DI_uiSpeedUnits 1 "DI_SPEED_KPH" 0 "DI_SPEED_MPH" ;
VAL_ 599 DI_vehicleSpeed 4095 "SNA" ;
VAL_ 680 CMPD_state 3 "CMPD_STATE_FAULT" 4 "CMPD_STATE_IDLE" 0 "CMPD_STATE_INIT" 1 "CMPD_STATE_RUNNING" 15 "CMPD_STATE_SNA" 2 "CMPD_STATE_STANDBY" ;
VAL_ 680 CMPD_wasteHeatState 1 "CMPD_WASTE_HEAT_STATE_ACTIVE" 2 "CMPD_WASTE_HEAT_STATE_NOT_AVAILABLE" 0 "CMPD_WASTE_HEAT_STATE_OFF" 3 "CMPD_WASTE_HEAT_STATE_UNUSED" ;
VAL_ 886 DIF_inverterTQF 0 "INVERTERT_INIT" 1 "INVERTERT_IRRATIONAL" 2 "INVERTERT_RATIONAL" 3 "INVERTERT_UNKNOWN" ;
VAL_ 789 DIR_inverterTQF 0 "INVERTERT_INIT" 1 "INVERTERT_IRRATIONAL" 2 "INVERTERT_RATIONAL" 3 "INVERTERT_UNKNOWN" ;
VAL_ 950 Odometer3B6 4294967 "SNA" ;
VAL_ 264 DIR_axleSpeed 32768 "SNA" ;
VAL_ 264 DIR_slavePedalPos 255 "SNA" ;
VAL_ 264 DIR_torqueActual 4096 "SNA" ;
VAL_ 264 DIR_torqueCommand 4096 "SNA" ;
VAL_ 294 DIR_vBatQF 0 "NOT_QUALIFIED" 1 "QUALIFIED" ;
VAL_ 421 DIF_vBatQF 0 "NOT_QUALIFIED" 1 "QUALIFIED" ;
VAL_ 552 EPBResmCaliperRequest228 3 "disengaging" 2 "engaging" 1 "idle" ;
VAL_ 552 EPBResmOperationTrigger228 22 "SuperPark" 6 "Released" 1 "ParkEngaged" ;
VAL_ 552 EPBRunitStatus228 10 "Disengaging" 8 "Engaging" 3 "ParkEngaged" 1 "DriveReleased" ;
VAL_ 648 EPBLesmCaliperRequest288 3 "disengaging" 2 "engaging" 1 "idle" ;
VAL_ 648 EPBLesmOperationTrigger288 22 "SuperPark" 6 "Released" 1 "ParkEngaged" ;
VAL_ 648 EPBLunitStatus288 10 "Disengaging" 8 "Engaging" 3 "ParkEngaged" 1 "DriveReleased" ;
VAL_ 2047 GTW_activeHighBeam 1 "ACTIVE" 0 "NOT_ACTIVE" ;
VAL_ 2047 GTW_airSuspension 0 "NONE" 2 "TESLA_ADAPTIVE" 1 "TESLA_STANDARD" ;
VAL_ 2047 GTW_airbagCutoffSwitch 0 "CUTOFF_SWITCH_DISABLED" 1 "CUTOFF_SWITCH_ENABLED" ;
VAL_ 2047 GTW_audioType 0 "BASE" 2 "BASE_WITH_PREMIUM200" 1 "PREMIUM" ;
VAL_ 2047 GTW_autopilot 4 "BASIC" 2 "ENHANCED" 1 "HIGHWAY" 0 "NONE" 3 "SELF_DRIVING" ;
VAL_ 2047 GTW_autopilotCameraType 0 "RCCB_CAMERAS" ;
VAL_ 2047 GTW_auxParkLamps 2 "EU" 0 "NA_BASE" 1 "NA_PREMIUM" 3 "NONE" ;
VAL_ 2047 GTW_bPillarNFCParam 0 "MODEL_3" 1 "MODEL_Y" ;
VAL_ 2047 GTW_brakeHWType 1 "BREMBO_LARGE_P42_BREMBO_44MOC" 3 "BREMBO_LARGE_P42_BREMBO_LARGE_44MOC" 2 "BREMBO_LARGE_P42_MANDO_43MOC" 0 "BREMBO_P42_MANDO_43MOC" ;
VAL_ 2047 GTW_brakeLineSwitchType 0 "DI_VC_SHARED" 1 "VC_ONLY" ;
VAL_ 2047 GTW_cabinPTCHeaterType 0 "BORGWARNER" 1 "NONE" ;
VAL_ 2047 GTW_chassisType 2 "MODEL_3_CHASSIS" 0 "MODEL_S_CHASSIS" 1 "MODEL_X_CHASSIS" 3 "MODEL_Y_CHASSIS" ;
VAL_ 2047 GTW_compressorType 2 "DENSO_41CC_11K" 1 "DENSO_41CC_8K" 0 "HANON_33CC" ;
VAL_ 2047 GTW_connectivityPackage 0 "BASE" 1 "PREMIUM" ;
VAL_ 2047 GTW_coolantPumpType 0 "DUAL" 1 "SINGLE_PUMP_BATT" ;
VAL_ 2047 GTW_dasHw 3 "PARKER_PASCAL_2_5" 4 "TESLA_AP3" ;
VAL_ 2047 GTW_deliveryStatus 1 "DELIVERED" 0 "NOT_DELIVERED" ;
VAL_ 2047 GTW_drivetrainType 1 "AWD" 0 "RWD" ;
VAL_ 2047 GTW_eBuckConfig 1 "DEV_BUCK" 0 "NONE" ;
VAL_ 2047 GTW_eCallEnabled 0 "DISABLED" 1 "ENABLED_OHC_SOS" 2 "ENABLED_UI_SOS" ;
VAL_ 2047 GTW_efficiencyPackage 0 "DEFAULT" 2 "M3_LR_2020" 3 "M3_LR_PERFORMANCE_2020" 1 "M3_SR_PLUS_2020" ;
VAL_ 2047 GTW_epasType 0 "MANDO_VGR69_GEN3" ;
VAL_ 2047 GTW_espValveType 0 "UNKNOWN" 1 "VALVE_TYPE_1" 2 "VALVE_TYPE_2" ;
VAL_ 2047 GTW_exteriorColor 5 "DEEP_BLUE" 3 "MIDNIGHT_SILVER" 6 "PEARL_WHITE" 0 "RED_MULTICOAT" 2 "SILVER_METALLIC" 1 "SOLID_BLACK" ;
VAL_ 2047 GTW_frontFogLamps 1 "INSTALLED" 0 "NOT_INSTALLED" ;
VAL_ 2047 GTW_frontSeatHeaters 1 "KONGSBERG_LOW_POWER" 0 "NONE" ;
VAL_ 2047 GTW_frontSeatReclinerHardware 3 "LEFT_RIGHT_SEAT_REDUCED_RANGE" 2 "LEFT_SEAT_REDUCED_RANGE" 1 "RIGHT_SEAT_REDUCED_RANGE" 0 "STANDARD_RANGE" ;
VAL_ 2047 GTW_frontSeatType 0 "BASE_TESLA" 3 "PREMIUM_L_TESLA_R_YANFENG" 2 "PREMIUM_L_YANFENG_R_TESLA" 1 "PREMIUM_TESLA" 4 "PREMIUM_YANFENG" ;
VAL_ 2047 GTW_headlamps 0 "BASE" 1 "PREMIUM" ;
VAL_ 2047 GTW_headlightLevelerType 1 "GEN1" 0 "NONE" ;
VAL_ 2047 GTW_homelinkType 1 "HOMELINK_V_OPT_2" 0 "NONE" ;
VAL_ 2047 GTW_hvacPanelVaneType 1 "CONVERGENT_V1" 0 "PARALLEL_V1" ;
VAL_ 2047 GTW_immersiveAudio 1 "BASE" 0 "DISABLED" 2 "PREMIUM" ;
VAL_ 2047 GTW_interiorLighting 0 "BASE" 1 "PREMIUM" 2 "PREMIUM_NO_POCKET_LIGHT" ;
VAL_ 2047 GTW_intrusionSensorType 0 "NOT_INSTALLED" 1 "VODAFONE" ;
VAL_ 2047 GTW_lumbarECUType 1 "ALFMEIER" 0 "NONE" ;
VAL_ 2047 GTW_mapRegion 4 "AU" 3 "CN" 1 "EU" 9 "HK" 5 "JP" 7 "KR" 8 "ME" 10 "MO" 2 "NONE" 6 "TW" 0 "US" ;
VAL_ 2047 GTW_memoryMirrors 0 "NOT_INSTALLED" 1 "SMR" ;
VAL_ 2047 GTW_numberHVILNodes 0 "HVIL_NODES_0" 1 "HVIL_NODES_1" 2 "HVIL_NODES_2" 3 "HVIL_NODES_3" 4 "HVIL_NODES_4" 5 "HVIL_NODES_5" ;
VAL_ 2047 GTW_packEnergy 3 "PACK_100_KWH" 0 "PACK_50_KWH" 2 "PACK_62_KWH" 1 "PACK_74_KWH" 4 "PACK_75_KWH" ;
VAL_ 2047 GTW_passengerAirbagType 2 "EUROW" 0 "FULL_SUPPRESSION" 1 "SAFETY_VENT" ;
VAL_ 2047 GTW_passengerOccupancySensorType 0 "OCS" 1 "RESISTIVE_PAD" ;
VAL_ 2047 GTW_pedestrianWarningSound 0 "NONE" 1 "SPEAKER" ;
VAL_ 2047 GTW_performancePackage 0 "BASE" 3 "BASE_PLUS" 4 "BASE_PLUS_AWD" 2 "LUDICROUS" 1 "PERFORMANCE" ;
VAL_ 2047 GTW_plcSupportType 2 "NATIVE_CHARGE_PORT" 0 "NONE" 1 "ONBOARD_ADAPTER" ;
VAL_ 2047 GTW_powerSteeringColumn 0 "NOT_INSTALLED" 1 "TK" ;
VAL_ 2047 GTW_radarHeaterType 1 "BECKER_THIN_3M" 0 "NONE" ;
VAL_ 2047 GTW_rearFogLamps 1 "INSTALLED" 0 "NOT_INSTALLED" ;
VAL_ 2047 GTW_rearGlassType 0 "NX" 1 "TSA5_NOPET" ;
VAL_ 2047 GTW_rearLightType 1 "EU_CN" 2 "GLOBAL" 0 "NA" ;
VAL_ 2047 GTW_rearSeatHeaters 1 "KONGSBERG_LOW_POWER" 0 "NONE" ;
VAL_ 2047 GTW_refrigerantType 0 "Default" 2 "R1234YF" 1 "R134A" ;
VAL_ 2047 GTW_restraintsHardwareType 22 "EUROW_ECALL_M3" 33 "EUROW_ECALL_MY" 23 "EUROW_NO_ECALL_M3" 34 "EUROW_NO_ECALL_MY" 21 "NA_M3" 32 "NA_MY" 31 "NA_MY_OLD" ;
VAL_ 2047 GTW_rightHandDrive 0 "LEFT" 1 "RIGHT" ;
VAL_ 2047 GTW_roofGlassType 0 "TSA3_PET" 1 "TSA5_NOPET" ;
VAL_ 2047 GTW_roofType 1 "FIXED_GLASS" 0 "METAL" 2 "PANORAMIC" ;
VAL_ 2047 GTW_softRange 1 "RANGE_220_MILES" 2 "RANGE_93_MILES" 0 "STANDARD" ;
VAL_ 2047 GTW_spoilerType 0 "NOT_INSTALLED" 1 "PASSIVE" ;
VAL_ 2047 GTW_steeringColumnMotorType 0 "BOSCH" 1 "JE" ;
VAL_ 2047 GTW_steeringColumnUJointType 0 "B_SAMPLE_PHASING" 1 "C_SAMPLE_PHASING" ;
VAL_ 2047 GTW_superchargingAccess 1 "ALLOWED" 0 "NOT_ALLOWED" 2 "PAY_AS_YOU_GO" ;
VAL_ 2047 GTW_tireType 4 "CONTI_ALL_SEASON_19" 17 "GOODYEAR_ALL_SEASON_20" 3 "HANKOOK_SUMMER_19" 1 "MICHELIN_ALL_SEASON_18" 19 "MICHELIN_ALL_SEASON_21" 2 "MICHELIN_SUMMER_18" 5 "MICHELIN_SUMMER_20" 18 "PIRELLI_SUMMER_21" 0 "UNKNOWN" ;
VAL_ 2047 GTW_towPackage 0 "NONE" 1 "TESLA_REV1" ;
VAL_ 2047 GTW_tpmsType 0 "CONTI_2" 1 "TESLA_BLE" ;
VAL_ 2047 GTW_twelveVBatteryType 0 "ATLASBX_B24_FLOODED" 1 "CLARIOS_B24_FLOODED" ;
VAL_ 2047 GTW_vdcType 0 "BOSCH_VDC" 1 "TESLA_VDC" ;
VAL_ 2047 GTW_wheelType 4 "GEMINI_19_SQUARE" 5 "GEMINI_19_STAGGERED" 0 "PINWHEEL_18" 18 "PINWHEEL_18_CAP_KIT" 1 "STILETTO_19" 2 "STILETTO_20" 14 "STILETTO_20_DARK_SQUARE" 3 "STILETTO_20_DARK_STAGGERED" 19 "ZEROG_20_GUNPOWDER" 17 "APOLLO_19_SILVER" 20 "APOLLO_19_SILVER_CAP_KIT" 15 "INDUCTION_20_BLACK" 16 "UBERTURBINE_21_BLACK" ;
VAL_ 2047 GTW_windshieldType 1 "EASTMAN_ACOUSTIC" 0 "SEKISUI_ACOUSTIC" ;
VAL_ 2047 GTW_xcpESP 0 "FALSE" 1 "TRUE" ;
VAL_ 2047 GTW_xcpIbst 0 "FALSE" 1 "TRUE" ;
